VERSION "DNNBNNNYNNNNNNNNNNNNNNNNNNNNNNNNNNNNNNNNNN/4/%%%/4/'%**4NNN///"

NS_ :

BS_:

BU_: Vector__XXX xSolarWave xSolarSurveyor xSolarStorm xNova xMiata_SCP xMiata_AGS UI INV_CHG INV GATEWAY EMS DIAG CHG BMS BATTMON AGS

BO_ 2147560448 ChgCfg: 10 BMS
 SG_ RsvBits : 56|2@1+ (1,0) [0|0] "" BMS,CHG,DIAG,INV_CHG,UI,xNova,xSolarSurveyor,xSolarWave
 SG_ OverChgEnDis : 60|2@1+ (1,0) [0|0] "" BMS,CHG,DIAG,INV_CHG,UI,xNova,xSolarSurveyor,xSolarWave
 SG_ MsgCount : 2|6@1+ (1,0) [0|0] "" BMS,CHG,DIAG,INV_CHG,UI,xNova,xSolarSurveyor,xSolarWave
 SG_ EqlzOneTimeEnDis : 58|2@1+ (1,0) [0|0] "" BMS,CHG,DIAG,INV_CHG,UI,xNova,xSolarSurveyor,xSolarWave
 SG_ DcSrcId : 16|8@1+ (1,0) [0|252] "" BMS,CHG,DIAG,INV_CHG,UI,xNova,xSolarSurveyor,xSolarWave
 SG_ ConcurAccCtr : 8|8@1+ (1,0) [0|252] "" BMS,CHG,DIAG,INV_CHG,UI,xNova,xSolarSurveyor,xSolarWave
 SG_ ChgOverrideEnDis : 62|2@1+ (1,0) [0|0] "" BMS,CHG,DIAG,INV_CHG,UI,xNova,xSolarSurveyor,xSolarWave
 SG_ ChgMode : 64|8@1+ (1,0) [0|252] "" BMS,CHG,DIAG,INV_CHG,UI,xNova,xSolarSurveyor,xSolarWave
 SG_ ChgILimitMin : 40|8@1+ (1,0) [0|252] "%" BMS,CHG,DIAG,INV_CHG,UI,xNova,xSolarSurveyor,xSolarWave
 SG_ ChgILimitMax : 48|8@1+ (1,0) [0|252] "%" BMS,CHG,DIAG,INV_CHG,UI,xNova,xSolarSurveyor,xSolarWave
 SG_ ChgILimit : 32|8@1+ (1,0) [0|252] "%" BMS,CHG,DIAG,INV_CHG,UI,xNova,xSolarSurveyor,xSolarWave
 SG_ ChgAlgorithm : 24|8@1+ (1,0) [0|252] "" BMS,CHG,DIAG,INV_CHG,UI,xNova,xSolarSurveyor,xSolarWave
 SG_ CfgType : 0|2@1+ (1,0) [0|0] "" BMS,CHG,DIAG,INV_CHG,UI,xNova,xSolarSurveyor,xSolarWave
 SG_ BattTempNoSensor : 72|8@1+ (1,0) [0|252] "" BMS,CHG,DIAG,INV_CHG,UI,xNova,xSolarSurveyor,xSolarWave

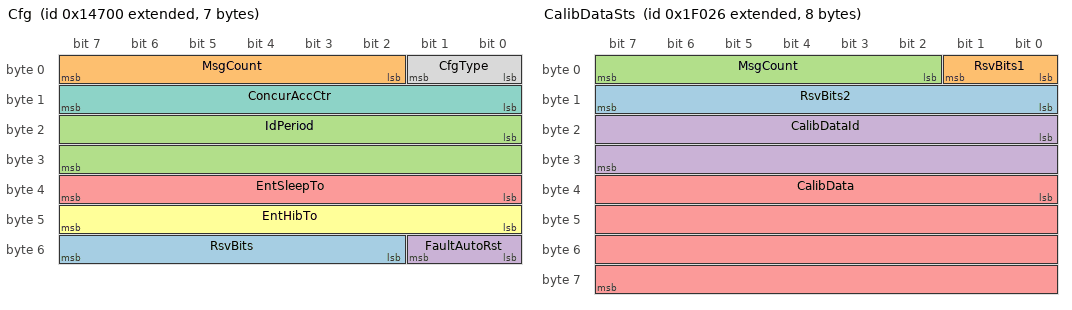
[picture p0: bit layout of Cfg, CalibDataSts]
BO_ 2147567360 Cfg: 7 AGS
 SG_ RsvBits : 50|6@1+ (1,0) [0|0] "" AGS,BATTMON,BMS,CHG,DIAG,EMS,GATEWAY,INV,INV_CHG,UI,xMiata_AGS,xNova,xSolarSurveyor,xSolarWave
 SG_ MsgCount : 2|6@1+ (1,0) [0|0] "" AGS,BATTMON,BMS,CHG,DIAG,EMS,GATEWAY,INV,INV_CHG,UI,xMiata_AGS,xNova,xSolarSurveyor,xSolarWave
 SG_ IdPeriod : 16|16@1+ (0.01,0) [0|655.32] "seconds" AGS,BATTMON,BMS,CHG,DIAG,EMS,GATEWAY,INV,INV_CHG,UI,xMiata_AGS,xNova,xSolarSurveyor,xSolarWave
 SG_ FaultAutoRst : 48|2@1+ (1,0) [0|0] "" AGS,BATTMON,BMS,CHG,DIAG,EMS,GATEWAY,INV,INV_CHG,UI,xMiata_AGS,xNova,xSolarSurveyor,xSolarWave
 SG_ EntSleepTo : 32|8@1+ (1,0) [0|252] "seconds" AGS,BATTMON,BMS,CHG,DIAG,EMS,GATEWAY,INV,INV_CHG,UI,xMiata_AGS,xNova,xSolarSurveyor,xSolarWave
 SG_ EntHibTo : 40|8@1+ (1,0) [0|252] "seconds" AGS,BATTMON,BMS,CHG,DIAG,EMS,GATEWAY,INV,INV_CHG,UI,xMiata_AGS,xNova,xSolarSurveyor,xSolarWave
 SG_ ConcurAccCtr : 8|8@1+ (1,0) [0|252] "" AGS,BATTMON,BMS,CHG,DIAG,EMS,GATEWAY,INV,INV_CHG,UI,xMiata_AGS,xNova,xSolarSurveyor,xSolarWave
 SG_ CfgType : 0|2@1+ (1,0) [0|0] "" AGS,BATTMON,BMS,CHG,DIAG,EMS,GATEWAY,INV,INV_CHG,UI,xMiata_AGS,xNova,xSolarSurveyor,xSolarWave

BO_ 2147610662 CalibDataSts: 8 BATTMON
 SG_ RsvBits2 : 8|8@1+ (1,0) [0|0] "" BATTMON,CHG,DIAG,INV,INV_CHG
 SG_ RsvBits1 : 0|2@1+ (1,0) [0|0] "" BATTMON,CHG,DIAG,INV,INV_CHG
 SG_ MsgCount : 2|6@1+ (1,0) [0|0] "" BATTMON,CHG,DIAG,INV,INV_CHG
 SG_ CalibDataId : 16|16@1+ (1,0) [0|65532] "" BATTMON,CHG,DIAG,INV,INV_CHG
 SG_ CalibData : 32|32@1+ (1,0) [0|4.29497E+09] "" BATTMON,CHG,DIAG,INV,INV_CHG

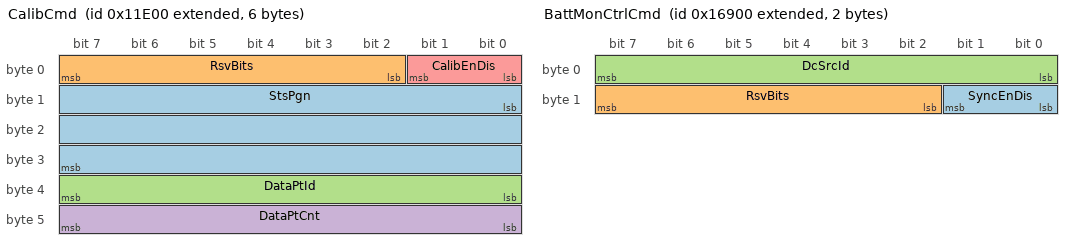
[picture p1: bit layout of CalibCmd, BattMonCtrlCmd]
BO_ 2147556864 CalibCmd: 6 DIAG
 SG_ StsPgn : 8|24@1+ (1,0) [0|0] "" BATTMON,CHG,INV,INV_CHG
 SG_ RsvBits : 2|6@1+ (1,0) [0|0] "" BATTMON,CHG,INV,INV_CHG
 SG_ DataPtId : 32|8@1+ (1,0) [0|252] "" BATTMON,CHG,INV,INV_CHG
 SG_ DataPtCnt : 40|8@1+ (1,0) [0|252] "" BATTMON,CHG,INV,INV_CHG
 SG_ CalibEnDis : 0|2@1+ (1,0) [0|0] "" BATTMON,CHG,INV,INV_CHG

BO_ 2147610665 BmsSts: 18 BATTMON
 SG_ RsvBits : 0|2@1+ (1,0) [0|0] "" CHG,DIAG,INV_CHG,UI,xSolarSurveyor,xSolarWave
 SG_ ReferenceV : 16|32@1- (0.001,0) [-2.14748E+06|2.14748E+06] "V" CHG,DIAG,INV_CHG,UI,xSolarSurveyor,xSolarWave
 SG_ ReferenceI : 48|32@1- (0.001,0) [-2.14748E+06|2.14748E+06] "Amps" CHG,DIAG,INV_CHG,UI,xSolarSurveyor,xSolarWave
 SG_ ReadbackV : 80|32@1- (0.001,0) [-2.14748E+06|2.14748E+06] "V" CHG,DIAG,INV_CHG,UI,xSolarSurveyor,xSolarWave
 SG_ ReadbackI : 112|32@1- (0.001,0) [-2.14748E+06|2.14748E+06] "Amps" CHG,DIAG,INV_CHG,UI,xSolarSurveyor,xSolarWave
 SG_ MsgCount : 2|6@1+ (1,0) [0|0] "" CHG,DIAG,INV_CHG,UI,xSolarSurveyor,xSolarWave
 SG_ DcSrcId : 8|8@1+ (1,0) [0|252] "" CHG,DIAG,INV_CHG,UI,xSolarSurveyor,xSolarWave

BO_ 2147574528 BmsCfg: 16 BATTMON
 SG_ MsgCount : 2|6@1+ (1,0) [0|0] "" BATTMON,BMS,DIAG,INV,INV_CHG,UI,xSolarWave
 SG_ MaxDischargeTimeIntMin : 96|16@1+ (0.01,0) [0|655.32] "seconds" BATTMON,BMS,DIAG,INV,INV_CHG,UI,xSolarWave
 SG_ MaxDischargeTimeIntMax : 112|16@1+ (0.01,0) [0|655.32] "seconds" BATTMON,BMS,DIAG,INV,INV_CHG,UI,xSolarWave
 SG_ MaxDischargeTimeInt : 80|16@1+ (0.01,0) [0|655.32] "seconds" BATTMON,BMS,DIAG,INV,INV_CHG,UI,xSolarWave
 SG_ MaxDischargeIMin : 48|16@1+ (1,0) [0|65532] "%" BATTMON,BMS,DIAG,INV,INV_CHG,UI,xSolarWave
 SG_ MaxDischargeIMax : 64|16@1+ (1,0) [0|65532] "%" BATTMON,BMS,DIAG,INV,INV_CHG,UI,xSolarWave
 SG_ MaxDischargeI : 32|16@1+ (1,0) [0|65532] "%" BATTMON,BMS,DIAG,INV,INV_CHG,UI,xSolarWave
 SG_ DcSrcId : 16|8@1+ (1,0) [0|252] "" BATTMON,BMS,DIAG,INV,INV_CHG,UI,xSolarWave
 SG_ ConcurAccCtr : 8|8@1+ (1,0) [0|252] "" BATTMON,BMS,DIAG,INV,INV_CHG,UI,xSolarWave
 SG_ CfgType : 0|2@1+ (1,0) [0|0] "" BATTMON,BMS,DIAG,INV,INV_CHG,UI,xSolarWave
 SG_ BattType : 24|8@1+ (1,0) [0|252] "" BATTMON,BMS,DIAG,INV,INV_CHG,UI,xSolarWave

BO_ 2147610820 BattSts2: 36 BATTMON
 SG_ Voltage : 16|32@1- (0.001,0) [-2.14748E+06|2.14748E+06] "V" AGS,BATTMON,CHG,DIAG,GATEWAY,INV,INV_CHG,UI,xSolarSurveyor,xSolarWave
 SG_ TimeToFull : 256|16@1+ (1,0) [0|65532] "minutes" AGS,BATTMON,CHG,DIAG,GATEWAY,INV,INV_CHG,UI,xSolarSurveyor,xSolarWave
 SG_ TimeRemain : 208|16@1+ (1,0) [0|65532] "minutes" AGS,BATTMON,CHG,DIAG,GATEWAY,INV,INV_CHG,UI,xSolarSurveyor,xSolarWave
 SG_ TempSensId : 144|8@1+ (1,0) [0|252] "" AGS,BATTMON,CHG,DIAG,GATEWAY,INV,INV_CHG,UI,xSolarSurveyor,xSolarWave
 SG_ Temp : 152|16@1+ (0.01,0) [0|655.32] "°K" AGS,BATTMON,CHG,DIAG,GATEWAY,INV,INV_CHG,UI,xSolarSurveyor,xSolarWave
 SG_ Soh : 176|8@1+ (1,0) [0|252] "%" AGS,BATTMON,CHG,DIAG,GATEWAY,INV,INV_CHG,UI,xSolarSurveyor,xSolarWave
 SG_ Soc : 168|8@1+ (1,0) [0|252] "%" AGS,BATTMON,CHG,DIAG,GATEWAY,INV,INV_CHG,UI,xSolarSurveyor,xSolarWave
 SG_ RsvBits : 0|2@1+ (1,0) [0|0] "" AGS,BATTMON,CHG,DIAG,GATEWAY,INV,INV_CHG,UI,xSolarSurveyor,xSolarWave
 SG_ RippleVoltage : 112|32@1+ (0.001,0) [0|4.29497E+06] "V" AGS,BATTMON,CHG,DIAG,GATEWAY,INV,INV_CHG,UI,xSolarSurveyor,xSolarWave
 SG_ Pwr : 80|32@1+ (1,0) [0|4.29497E+09] "W" AGS,BATTMON,CHG,DIAG,GATEWAY,INV,INV_CHG,UI,xSolarSurveyor,xSolarWave
 SG_ NomBattVoltage : 280|8@1+ (1,0) [0|252] "" AGS,BATTMON,CHG,DIAG,GATEWAY,INV,INV_CHG,UI,xSolarSurveyor,xSolarWave
 SG_ MsgCount : 2|6@1+ (1,0) [0|0] "" AGS,BATTMON,CHG,DIAG,GATEWAY,INV,INV_CHG,UI,xSolarSurveyor,xSolarWave
 SG_ EnergyRemain : 224|32@1+ (1,0) [0|4.29497E+09] "W h" AGS,BATTMON,CHG,DIAG,GATEWAY,INV,INV_CHG,UI,xSolarSurveyor,xSolarWave
 SG_ DcSrcId : 8|8@1+ (1,0) [0|252] "" AGS,BATTMON,CHG,DIAG,GATEWAY,INV,INV_CHG,UI,xSolarSurveyor,xSolarWave
 SG_ Current : 48|32@1- (0.001,0) [-2.14748E+06|2.14748E+06] "Amps" AGS,BATTMON,CHG,DIAG,GATEWAY,INV,INV_CHG,UI,xSolarSurveyor,xSolarWave
 SG_ BattType : 272|8@1+ (1,0) [0|252] "" AGS,BATTMON,CHG,DIAG,GATEWAY,INV,INV_CHG,UI,xSolarSurveyor,xSolarWave
 SG_ BattCapRemain : 184|16@1+ (1,0) [0|65532] "Ah" AGS,BATTMON,CHG,DIAG,GATEWAY,INV,INV_CHG,UI,xSolarSurveyor,xSolarWave
 SG_ BattCapPer : 200|8@1+ (1,0) [0|252] "%" AGS,BATTMON,CHG,DIAG,GATEWAY,INV,INV_CHG,UI,xSolarSurveyor,xSolarWave

BO_ 2147610651 BattMonSts: 39 BATTMON
 SG_ Voltage : 16|32@1- (0.001,0) [-2.14748E+06|2.14748E+06] "V" AGS,BATTMON,CHG,DIAG,INV,INV_CHG,UI,xSolarWave
 SG_ TimeToFull : 160|16@1+ (1,0) [0|65532] "minutes" AGS,BATTMON,CHG,DIAG,INV,INV_CHG,UI,xSolarWave
 SG_ TimeToDischarge : 144|16@1+ (1,0) [0|65532] "minutes" AGS,BATTMON,CHG,DIAG,INV,INV_CHG,UI,xSolarWave
 SG_ Temp : 80|16@1+ (0.01,0) [0|655.32] "°K" AGS,BATTMON,CHG,DIAG,INV,INV_CHG,UI,xSolarWave
 SG_ Soh : 136|8@1+ (1,0) [0|252] "%" AGS,BATTMON,CHG,DIAG,INV,INV_CHG,UI,xSolarWave
 SG_ Soc : 128|8@1+ (1,0) [0|252] "%" AGS,BATTMON,CHG,DIAG,INV,INV_CHG,UI,xSolarWave
 SG_ RsvBits : 202|6@1+ (1,0) [0|0] "" AGS,BATTMON,CHG,DIAG,INV,INV_CHG,UI,xSolarWave
 SG_ RsvBits : 0|2@1+ (1,0) [0|0] "" AGS,BATTMON,CHG,DIAG,INV,INV_CHG,UI,xSolarWave
 SG_ PerOvercharge : 192|8@1+ (1,0) [0|252] "%" AGS,BATTMON,CHG,DIAG,INV,INV_CHG,UI,xSolarWave
 SG_ MsgCount : 2|6@1+ (1,0) [0|0] "" AGS,BATTMON,CHG,DIAG,INV,INV_CHG,UI,xSolarWave
 SG_ Mid3Voltage : 280|32@1- (0.001,0) [-2.14748E+06|2.14748E+06] "V" AGS,BATTMON,CHG,DIAG,INV,INV_CHG,UI,xSolarWave
 SG_ Mid2Voltage : 248|32@1- (0.001,0) [-2.14748E+06|2.14748E+06] "V" AGS,BATTMON,CHG,DIAG,INV,INV_CHG,UI,xSolarWave
 SG_ Mid1Voltage : 216|32@1- (0.001,0) [-2.14748E+06|2.14748E+06] "V" AGS,BATTMON,CHG,DIAG,INV,INV_CHG,UI,xSolarWave
 SG_ LastEqualize : 208|8@1+ (1,0) [0|252] "days" AGS,BATTMON,CHG,DIAG,INV,INV_CHG,UI,xSolarWave
 SG_ HoursInFloat : 176|16@1+ (0.1,0) [0|6553.2] "hours" AGS,BATTMON,CHG,DIAG,INV,INV_CHG,UI,xSolarWave
 SG_ DcSrcId : 8|8@1+ (1,0) [0|252] "" AGS,BATTMON,CHG,DIAG,INV,INV_CHG,UI,xSolarWave
 SG_ Current : 48|32@1- (0.001,0) [-2.14748E+06|2.14748E+06] "Amps" AGS,BATTMON,CHG,DIAG,INV,INV_CHG,UI,xSolarWave
 SG_ BtsPresent : 200|2@1+ (1,0) [0|0] "" AGS,BATTMON,CHG,DIAG,INV,INV_CHG,UI,xSolarWave
 SG_ BattCapRemoved : 96|16@1+ (1,0) [0|65532] "Ah" AGS,BATTMON,CHG,DIAG,INV,INV_CHG,UI,xSolarWave
 SG_ BattCapRemain : 112|16@1+ (1,0) [0|65532] "Ah" AGS,BATTMON,CHG,DIAG,INV,INV_CHG,UI,xSolarWave

BO_ 2147610645 BattMonStatsBatt: 1785 BATTMON
 SG_ VoltageMin : 88|32@1- (0.001,0) [-2.14748E+06|2.14748E+06] "V" DIAG,UI
 SG_ VoltageMax : 120|32@1- (0.001,0) [-2.14748E+06|2.14748E+06] "V" DIAG,UI
 SG_ TimeSinceSync : 392|32@1+ (1,0) [0|4.29497E+09] "seconds" DIAG,UI
 SG_ TempMin : 248|16@1+ (0.01,0) [0|655.32] "°K" DIAG,UI
 SG_ TempMax : 264|16@1+ (0.01,0) [0|655.32] "°K" DIAG,UI
 SG_ RsvBits : 0|2@1+ (1,0) [0|0] "" DIAG,UI
 SG_ PreviousPeriodCount : 19|5@1+ (1,0) [0|0] "" DIAG,UI
 SG_ PreviousPeriod : 16|3@1+ (1,0) [0|0] "" DIAG,UI
 SG_ NumSync : 440|16@1+ (1,0) [0|65532] "" DIAG,UI
 SG_ NumSoc90 : 520|16@1+ (1,0) [0|65532] "" DIAG,UI
 SG_ NumSoc75 : 504|16@1+ (1,0) [0|65532] "" DIAG,UI
 SG_ NumSoc50 : 488|16@1+ (1,0) [0|65532] "" DIAG,UI
 SG_ NumSoc25 : 472|16@1+ (1,0) [0|65532] "" DIAG,UI
 SG_ NumDischg : 456|16@1+ (1,0) [0|65532] "" DIAG,UI
 SG_ NumChg : 424|16@1+ (1,0) [0|65532] "" DIAG,UI
 SG_ MsgCount : 2|6@1+ (1,0) [0|0] "" DIAG,UI
 SG_ EnergyOut : 360|32@1+ (1,0) [0|4.29497E+09] "W h" DIAG,UI
 SG_ EnergyIn : 328|32@1+ (1,0) [0|4.29497E+09] "W h" DIAG,UI
 SG_ DeepestSoc : 536|8@1+ (1,0) [0|252] "%" DIAG,UI
 SG_ DeepestDischgPer : 320|8@1+ (1,0) [0|252] "%" DIAG,UI
 SG_ DeepestDischg : 304|16@1+ (1,0) [0|65532] "Ah" DIAG,UI
 SG_ DcSrcId : 8|8@1+ (1,0) [0|252] "" DIAG,UI
 SG_ CurrentMaxDischg : 56|32@1- (0.001,0) [-2.14748E+06|2.14748E+06] "Amps" DIAG,UI
 SG_ CurrentMaxChg : 24|32@1- (0.001,0) [-2.14748E+06|2.14748E+06] "Amps" DIAG,UI
 SG_ CapacityReturned : 184|32@1- (1,0) [-2.14748E+09|2.14748E+09] "Ah" DIAG,UI
 SG_ CapacityRemoved : 216|32@1- (1,0) [-2.14748E+09|2.14748E+09] "Ah" DIAG,UI
 SG_ CapacityMin : 152|16@1+ (1,0) [0|65532] "Ah" DIAG,UI
 SG_ CapacityMax : 168|16@1+ (1,0) [0|65532] "Ah" DIAG,UI
 SG_ AvgDischgPer : 296|8@1+ (1,0) [0|252] "%" DIAG,UI
 SG_ AvgDischg : 280|16@1+ (1,0) [0|65532] "Ah" DIAG,UI

BO_ 2147610829 BattMonHist: 24 BATTMON
 SG_ RsvBits : 0|2@1+ (1,0) [0|0] "" DIAG,UI
 SG_ NumSync : 160|16@1+ (1,0) [0|65532] "" DIAG,UI
 SG_ NumDischg : 176|16@1+ (1,0) [0|65532] "" DIAG,UI
 SG_ NumChg : 144|16@1+ (1,0) [0|65532] "" DIAG,UI
 SG_ MsgCount : 2|6@1+ (1,0) [0|0] "" DIAG,UI
 SG_ DeepestDischgPer : 64|16@1+ (0.01,0) [0|655.32] "%" DIAG,UI
 SG_ DeepestDischg : 48|16@1+ (1,0) [0|65532] "Ah" DIAG,UI
 SG_ DcSrcId : 8|8@1+ (1,0) [0|252] "" DIAG,UI
 SG_ CapacityReturned : 112|32@1+ (1,0) [0|4.29497E+09] "Ah" DIAG,UI
 SG_ CapacityRemoved : 80|32@1+ (1,0) [0|4.29497E+09] "Ah" DIAG,UI
 SG_ AvgDischgPer : 32|16@1+ (0.01,0) [0|655.32] "%" DIAG,UI
 SG_ AvgDischg : 16|16@1+ (1,0) [0|65532] "Ah" DIAG,UI

BO_ 2147576064 BattMonCtrlCmd: 2 DIAG
 SG_ SyncEnDis : 8|2@1+ (1,0) [0|0] "" BATTMON
 SG_ RsvBits : 10|6@1+ (1,0) [0|0] "" BATTMON
 SG_ DcSrcId : 0|8@1+ (1,0) [0|252] "" BATTMON

BO_ 2147574784 BattMonCfgSync: 19 BATTMON
 SG_ RsvBits : 124|4@1+ (1,0) [0|0] "" BATTMON,DIAG,UI
 SG_ MsgCount : 2|6@1+ (1,0) [0|0] "" BATTMON,DIAG,UI
 SG_ DischgFloorMin : 104|8@1+ (1,0) [0|252] "%" BATTMON,DIAG,UI
 SG_ DischgFloorMax : 112|8@1+ (1,0) [0|252] "%" BATTMON,DIAG,UI
 SG_ DischgFloor : 96|8@1+ (1,0) [0|252] "%" BATTMON,DIAG,UI
 SG_ DcSrcId : 16|8@1+ (1,0) [0|252] "" BATTMON,DIAG,UI
 SG_ ConcurAccCtr : 8|8@1+ (1,0) [0|252] "" BATTMON,DIAG,UI
 SG_ ChgFloatVMin : 40|16@1+ (0.001,0) [0|65.532] "V" BATTMON,DIAG,UI
 SG_ ChgFloatVMax : 56|16@1+ (0.001,0) [0|65.532] "V" BATTMON,DIAG,UI
 SG_ ChgFloatV : 24|16@1+ (0.001,0) [0|65.532] "V" BATTMON,DIAG,UI
 SG_ ChgFloatIMin : 80|8@1+ (0.1,0) [0|25.2] "%" BATTMON,DIAG,UI
 SG_ ChgFloatIMax : 88|8@1+ (0.1,0) [0|25.2] "%" BATTMON,DIAG,UI
 SG_ ChgFloatI : 72|8@1+ (0.1,0) [0|25.2] "%" BATTMON,DIAG,UI
 SG_ CfgType : 0|2@1+ (1,0) [0|0] "" BATTMON,DIAG,UI
 SG_ AutoSyncTime : 120|4@1+ (1,0) [0|0] "seconds" BATTMON,DIAG,UI
 SG_ AutoSyncSensMin : 136|8@1+ (1,0) [0|252] "" BATTMON,DIAG,UI
 SG_ AutoSyncSensMax : 144|8@1+ (1,0) [0|252] "" BATTMON,DIAG,UI
 SG_ AutoSyncSens : 128|8@1+ (1,0) [0|252] "" BATTMON,DIAG,UI

BO_ 2147559680 BattMonCfg: 28 BATTMON
 SG_ TimeRemAvgFilter : 172|2@1+ (1,0) [0|0] "" BATTMON,DIAG,UI
 SG_ TempUnit : 72|8@1+ (1,0) [0|252] "" BATTMON,DIAG,UI
 SG_ ShuntVoltRating : 160|2@1+ (1,0) [0|0] "mV" BATTMON,DIAG,UI
 SG_ ShuntAmpRating : 152|8@1+ (1,0) [0|0] "A" BATTMON,DIAG,UI
 SG_ SetupLock : 170|2@1+ (1,0) [0|0] "" BATTMON,DIAG,UI
 SG_ SelfDischargeRateMin : 136|8@1+ (0.1,0) [0|25.2] "%/month" BATTMON,DIAG,UI
 SG_ SelfDischargeRateMax : 144|8@1+ (0.1,0) [0|25.2] "%/month" BATTMON,DIAG,UI
 SG_ SelfDischargeRate : 128|8@1+ (0.1,0) [0|25.2] "%/month" BATTMON,DIAG,UI
 SG_ RsvBits : 174|2@1+ (1,0) [0|0] "" BATTMON,DIAG,UI
 SG_ NomV : 168|2@1+ (1,0) [0|0] "" BATTMON,DIAG,UI
 SG_ NomTempMin : 40|16@1+ (0.01,0) [0|655.32] "°K" BATTMON,DIAG,UI
 SG_ NomTempMax : 56|16@1+ (0.01,0) [0|655.32] "°K" BATTMON,DIAG,UI
 SG_ NomTemp : 24|16@1+ (0.01,0) [0|655.32] "°K" BATTMON,DIAG,UI
 SG_ NomDisRateMin : 112|8@1+ (1,0) [0|252] "hours" BATTMON,DIAG,UI
 SG_ NomDisRateMax : 120|8@1+ (1,0) [0|252] "hours" BATTMON,DIAG,UI
 SG_ NomDisRate : 104|8@1+ (1,0) [0|252] "hours" BATTMON,DIAG,UI
 SG_ MsgCount : 2|6@1+ (1,0) [0|0] "" BATTMON,DIAG,UI
 SG_ DefaultTempMin : 192|16@1+ (0.01,0) [0|655.32] "°K" BATTMON,DIAG,UI
 SG_ DefaultTempMax : 208|16@1+ (0.01,0) [0|655.32] "°K" BATTMON,DIAG,UI
 SG_ DefaultTemp : 176|16@1+ (0.01,0) [0|655.32] "°K" BATTMON,DIAG,UI
 SG_ DcSrcId : 16|8@1+ (1,0) [0|252] "" BATTMON,DIAG,UI
 SG_ ConcurAccCtr : 8|8@1+ (1,0) [0|252] "" BATTMON,DIAG,UI
 SG_ ChgEfficFactorMode : 162|2@1+ (1,0) [0|0] "" BATTMON,DIAG,UI
 SG_ CfgType : 0|2@1+ (1,0) [0|0] "" BATTMON,DIAG,UI
 SG_ BattCapTempCoeffMin : 88|8@1+ (0.01,0) [0|2.52] "%Ah/°C" BATTMON,DIAG,UI
 SG_ BattCapTempCoeffMax : 96|8@1+ (0.01,0) [0|2.52] "%Ah/°C" BATTMON,DIAG,UI
 SG_ BattCapTempCoeff : 80|8@1+ (0.01,0) [0|2.52] "%Ah/°C" BATTMON,DIAG,UI
 SG_ BacklightDuration : 164|4@1+ (1,0) [0|0] "seconds" BATTMON,DIAG,UI

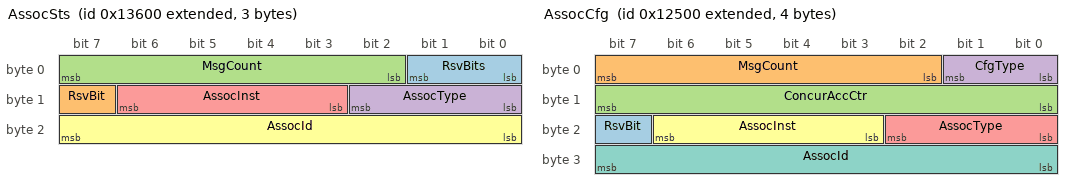
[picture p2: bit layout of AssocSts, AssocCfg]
BO_ 2147563008 AssocSts: 3 AGS
 SG_ RsvBits : 0|2@1+ (1,0) [0|0] "" AGS,BATTMON,BMS,CHG,EMS,GATEWAY,INV,INV_CHG,UI,xMiata_AGS,xNova,xSolarSurveyor,xSolarWave
 SG_ RsvBit : 15|1@1+ (1,0) [0|0] "" AGS,BATTMON,BMS,CHG,EMS,GATEWAY,INV,INV_CHG,UI,xMiata_AGS,xNova,xSolarSurveyor,xSolarWave
 SG_ MsgCount : 2|6@1+ (1,0) [0|0] "" AGS,BATTMON,BMS,CHG,EMS,GATEWAY,INV,INV_CHG,UI,xMiata_AGS,xNova,xSolarSurveyor,xSolarWave
 SG_ AssocType : 8|3@1+ (1,0) [0|0] "" AGS,BATTMON,BMS,CHG,EMS,GATEWAY,INV,INV_CHG,UI,xMiata_AGS,xNova,xSolarSurveyor,xSolarWave
 SG_ AssocInst : 11|4@1+ (1,0) [0|0] "" AGS,BATTMON,BMS,CHG,EMS,GATEWAY,INV,INV_CHG,UI,xMiata_AGS,xNova,xSolarSurveyor,xSolarWave
 SG_ AssocId : 16|8@1+ (1,0) [0|252] "" AGS,BATTMON,BMS,CHG,EMS,GATEWAY,INV,INV_CHG,UI,xMiata_AGS,xNova,xSolarSurveyor,xSolarWave

BO_ 2147558656 AssocCfg: 4 AGS
 SG_ RsvBit : 23|1@1+ (1,0) [0|0] "" AGS,BATTMON,BMS,CHG,DIAG,EMS,INV,INV_CHG,UI,xMiata_AGS,xNova,xSolarSurveyor,xSolarWave
 SG_ MsgCount : 2|6@1+ (1,0) [0|0] "" AGS,BATTMON,BMS,CHG,DIAG,EMS,INV,INV_CHG,UI,xMiata_AGS,xNova,xSolarSurveyor,xSolarWave
 SG_ ConcurAccCtr : 8|8@1+ (1,0) [0|252] "" AGS,BATTMON,BMS,CHG,DIAG,EMS,INV,INV_CHG,UI,xMiata_AGS,xNova,xSolarSurveyor,xSolarWave
 SG_ CfgType : 0|2@1+ (1,0) [0|0] "" AGS,BATTMON,BMS,CHG,DIAG,EMS,INV,INV_CHG,UI,xMiata_AGS,xNova,xSolarSurveyor,xSolarWave
 SG_ AssocType : 16|3@1+ (1,0) [0|0] "" AGS,BATTMON,BMS,CHG,DIAG,EMS,INV,INV_CHG,UI,xMiata_AGS,xNova,xSolarSurveyor,xSolarWave
 SG_ AssocInst : 19|4@1+ (1,0) [0|0] "" AGS,BATTMON,BMS,CHG,DIAG,EMS,INV,INV_CHG,UI,xMiata_AGS,xNova,xSolarSurveyor,xSolarWave
 SG_ AssocId : 24|8@1+ (1,0) [0|252] "" AGS,BATTMON,BMS,CHG,DIAG,EMS,INV,INV_CHG,UI,xMiata_AGS,xNova,xSolarSurveyor,xSolarWave

BO_ 2147610633 ApsSts: 10 CHG
 SG_ Voltage : 16|32@1- (0.001,0) [-2.14748E+06|2.14748E+06] "V" CHG,DIAG,INV,INV_CHG
 SG_ RsvBits : 0|2@1+ (1,0) [0|0] "" CHG,DIAG,INV,INV_CHG
 SG_ OutputId : 8|8@1+ (1,0) [0|252] "" CHG,DIAG,INV,INV_CHG
 SG_ MsgCount : 2|6@1+ (1,0) [0|0] "" CHG,DIAG,INV,INV_CHG
 SG_ Current : 48|32@1- (0.001,0) [-2.14748E+06|2.14748E+06] "Amps" CHG,DIAG,INV,INV_CHG

BO_ 2147552512 ApsCfgUv: 223 CHG
 SG_ UvLvlMin : 88|32@1- (0.001,0) [-2.14748E+06|2.14748E+06] "V" CHG,DIAG,INV,INV_CHG,xNova,xSolarWave
 SG_ UvLvlMax : 120|32@1- (0.001,0) [-2.14748E+06|2.14748E+06] "V" CHG,DIAG,INV,INV_CHG,xNova,xSolarWave
 SG_ UvLvl : 56|32@1- (0.001,0) [-2.14748E+06|2.14748E+06] "V" CHG,DIAG,INV,INV_CHG,xNova,xSolarWave
 SG_ UvIntvlMin : 168|16@1+ (0.01,0) [0|655.32] "seconds" CHG,DIAG,INV,INV_CHG,xNova,xSolarWave
 SG_ UvIntvlMax : 184|16@1+ (0.01,0) [0|655.32] "seconds" CHG,DIAG,INV,INV_CHG,xNova,xSolarWave
 SG_ UvIntvl : 152|16@1+ (0.01,0) [0|655.32] "seconds" CHG,DIAG,INV,INV_CHG,xNova,xSolarWave
 SG_ RefEvtId : 40|16@1+ (1,0) [0|65532] "" CHG,DIAG,INV,INV_CHG,xNova,xSolarWave
 SG_ OutputId : 16|8@1+ (1,0) [0|252] "" CHG,DIAG,INV,INV_CHG,xNova,xSolarWave
 SG_ MsgCount : 2|6@1+ (1,0) [0|0] "" CHG,DIAG,INV,INV_CHG,xNova,xSolarWave
 SG_ EvtId : 24|16@1+ (1,0) [0|65532] "" CHG,DIAG,INV,INV_CHG,xNova,xSolarWave
 SG_ ConcurAccCtr : 8|8@1+ (1,0) [0|252] "" CHG,DIAG,INV,INV_CHG,xNova,xSolarWave
 SG_ CfgType : 0|2@1+ (1,0) [0|0] "" CHG,DIAG,INV,INV_CHG,xNova,xSolarWave

BO_ 2147552768 ApsCfgOv: 223 CHG
 SG_ RefEvtId : 40|16@1+ (1,0) [0|65532] "" CHG,DIAG,INV,INV_CHG,xNova,xSolarWave
 SG_ OvLvlMin : 88|32@1- (0.001,0) [-2.14748E+06|2.14748E+06] "V" CHG,DIAG,INV,INV_CHG,xNova,xSolarWave
 SG_ OvLvlMax : 120|32@1- (0.001,0) [-2.14748E+06|2.14748E+06] "V" CHG,DIAG,INV,INV_CHG,xNova,xSolarWave
 SG_ OvLvl : 56|32@1- (0.001,0) [-2.14748E+06|2.14748E+06] "V" CHG,DIAG,INV,INV_CHG,xNova,xSolarWave
 SG_ OvIntvlMin : 168|16@1+ (0.01,0) [0|655.32] "seconds" CHG,DIAG,INV,INV_CHG,xNova,xSolarWave
 SG_ OvIntvlMax : 184|16@1+ (0.01,0) [0|655.32] "seconds" CHG,DIAG,INV,INV_CHG,xNova,xSolarWave
 SG_ OvIntvl : 152|16@1+ (0.01,0) [0|655.32] "seconds" CHG,DIAG,INV,INV_CHG,xNova,xSolarWave
 SG_ OutputId : 16|8@1+ (1,0) [0|252] "" CHG,DIAG,INV,INV_CHG,xNova,xSolarWave
 SG_ MsgCount : 2|6@1+ (1,0) [0|0] "" CHG,DIAG,INV,INV_CHG,xNova,xSolarWave
 SG_ EvtId : 24|16@1+ (1,0) [0|65532] "" CHG,DIAG,INV,INV_CHG,xNova,xSolarWave
 SG_ ConcurAccCtr : 8|8@1+ (1,0) [0|252] "" CHG,DIAG,INV,INV_CHG,xNova,xSolarWave
 SG_ CfgType : 0|2@1+ (1,0) [0|0] "" CHG,DIAG,INV,INV_CHG,xNova,xSolarWave

BO_ 2147610647 AgsStsGen: 15 AGS
 SG_ Temp : 32|16@1+ (0.01,0) [0|655.32] "°K" DIAG,UI
 SG_ RsvBits : 0|2@1+ (1,0) [0|0] "" DIAG,UI
 SG_ OilPress : 16|16@1+ (100,0) [0|6.5532E+06] "Pa" DIAG,UI
 SG_ MsgCount : 2|6@1+ (1,0) [0|0] "" DIAG,UI
 SG_ FuelPress : 88|16@1+ (100,0) [0|6.5532E+06] "Pa" DIAG,UI
 SG_ FuelLvl : 80|8@1+ (1,0) [0|252] "%" DIAG,UI
 SG_ EngineDiscreteWarnSts : 104|16@1+ (1,0) [0|0] "" DIAG,UI
 SG_ BattV : 48|32@1- (0.001,0) [-2.14748E+06|2.14748E+06] "V" DIAG,UI
 SG_ AcSrcId : 8|8@1+ (1,0) [0|252] "" DIAG,UI

BO_ 2147610641 AgsSts: 10 AGS
 SG_ TimeInt : 56|16@1+ (0.1,0) [0|6553.2] "minutes" AGS,BATTMON,CHG,DIAG,EMS,GATEWAY,INV,INV_CHG,UI,xSolarWave
 SG_ RsvBits2 : 74|6@1+ (1,0) [0|0] "" AGS,BATTMON,CHG,DIAG,EMS,GATEWAY,INV,INV_CHG,UI,xSolarWave
 SG_ RsvBits1 : 0|2@1+ (1,0) [0|0] "" AGS,BATTMON,CHG,DIAG,EMS,GATEWAY,INV,INV_CHG,UI,xSolarWave
 SG_ OpState : 16|16@1+ (1,0) [0|65532] "" AGS,BATTMON,CHG,DIAG,EMS,GATEWAY,INV,INV_CHG,UI,xSolarWave
 SG_ MsgCount : 2|6@1+ (1,0) [0|0] "" AGS,BATTMON,CHG,DIAG,EMS,GATEWAY,INV,INV_CHG,UI,xSolarWave
 SG_ GenState : 32|8@1+ (1,0) [0|252] "" AGS,BATTMON,CHG,DIAG,EMS,GATEWAY,INV,INV_CHG,UI,xSolarWave
 SG_ GenOnReason : 40|8@1+ (1,0) [0|252] "" AGS,BATTMON,CHG,DIAG,EMS,GATEWAY,INV,INV_CHG,UI,xSolarWave
 SG_ GenOffReason : 48|8@1+ (1,0) [0|252] "" AGS,BATTMON,CHG,DIAG,EMS,GATEWAY,INV,INV_CHG,UI,xSolarWave
 SG_ AgsGenSig : 72|2@1+ (1,0) [0|0] "" AGS,BATTMON,CHG,DIAG,EMS,GATEWAY,INV,INV_CHG,UI,xSolarWave
 SG_ AcSrcId : 8|8@1+ (1,0) [0|252] "" AGS,BATTMON,CHG,DIAG,EMS,GATEWAY,INV,INV_CHG,UI,xSolarWave

BO_ 2147610648 AgsStatsGen: 12 AGS
 SG_ TotalRunTime : 48|16@1+ (0.1,0) [0|6553.2] "hours" DIAG,UI
 SG_ SuccStartCnt : 16|16@1+ (1,0) [0|65532] "" DIAG,UI
 SG_ RsvBits : 0|2@1+ (1,0) [0|0] "" DIAG,UI
 SG_ PrevRunTime : 64|16@1+ (1,0) [0|65532] "minutes" DIAG,UI
 SG_ MsgCount : 2|6@1+ (1,0) [0|0] "" DIAG,UI
 SG_ FailStartCnt : 32|16@1+ (1,0) [0|65532] "" DIAG,UI
 SG_ CurrRunTime : 80|16@1+ (1,0) [0|65532] "minutes" DIAG,UI
 SG_ AcSrcId : 8|8@1+ (1,0) [0|252] "" DIAG,UI

BO_ 2147557120 AgsCtrlCmd: 2 DIAG
 SG_ DesiredState : 8|8@1+ (1,0) [0|252] "" AGS,xMiata_AGS
 SG_ AcSrcId : 0|8@1+ (1,0) [0|252] "" AGS,xMiata_AGS

BO_ 2147560192 AgsCfgGen: 223 AGS
 SG_ StopTimeoutMin : 536|16@1+ (1,0) [0|65532] "seconds" AGS,DIAG,UI,xMiata_AGS
 SG_ StopTimeoutMax : 552|16@1+ (1,0) [0|65532] "seconds" AGS,DIAG,UI,xMiata_AGS
 SG_ StopTimeout : 520|16@1+ (1,0) [0|65532] "seconds" AGS,DIAG,UI,xMiata_AGS
 SG_ StarterCooldownTimeMin : 248|16@1+ (1,0) [0|65532] "seconds" AGS,DIAG,UI,xMiata_AGS
 SG_ StarterCooldownTimeMax : 264|16@1+ (1,0) [0|65532] "seconds" AGS,DIAG,UI,xMiata_AGS
 SG_ StarterCooldownTime : 232|16@1+ (1,0) [0|65532] "seconds" AGS,DIAG,UI,xMiata_AGS
 SG_ StartDlyMin : 104|16@1+ (1,0) [0|65532] "seconds" AGS,DIAG,UI,xMiata_AGS
 SG_ StartDlyMax : 120|16@1+ (1,0) [0|65532] "seconds" AGS,DIAG,UI,xMiata_AGS
 SG_ StartDly : 88|16@1+ (1,0) [0|65532] "seconds" AGS,DIAG,UI,xMiata_AGS
 SG_ SpindownTimeMin : 488|16@1+ (1,0) [0|65532] "seconds" AGS,DIAG,UI,xMiata_AGS
 SG_ SpindownTimeMax : 504|16@1+ (1,0) [0|65532] "seconds" AGS,DIAG,UI,xMiata_AGS
 SG_ SpindownTime : 472|16@1+ (1,0) [0|65532] "seconds" AGS,DIAG,UI,xMiata_AGS
 SG_ ShutdownBypassTimeMin : 200|16@1+ (1,0) [0|65532] "seconds" AGS,DIAG,UI,xMiata_AGS
 SG_ ShutdownBypassTimeMax : 216|16@1+ (1,0) [0|65532] "seconds" AGS,DIAG,UI,xMiata_AGS
 SG_ ShutdownBypassTime : 184|16@1+ (1,0) [0|65532] "seconds" AGS,DIAG,UI,xMiata_AGS
 SG_ RelayId : 736|8@1+ (1,0) [0|252] "" AGS,DIAG,UI,xMiata_AGS
 SG_ RelayFunc : 744|8@1+ (1,0) [0|252] "" AGS,DIAG,UI,xMiata_AGS
 SG_ PreheatTimeMin : 56|16@1+ (1,0) [0|65532] "seconds" AGS,DIAG,UI,xMiata_AGS
 SG_ PreheatTimeMax : 72|16@1+ (1,0) [0|65532] "seconds" AGS,DIAG,UI,xMiata_AGS
 SG_ PreheatTime : 40|16@1+ (1,0) [0|65532] "seconds" AGS,DIAG,UI,xMiata_AGS
 SG_ MsgCount : 2|6@1+ (1,0) [0|0] "" AGS,DIAG,UI,xMiata_AGS
 SG_ MaxRunTimeMin : 392|16@1+ (1,0) [0|65532] "minutes" AGS,DIAG,UI,xMiata_AGS
 SG_ MaxRunTimeMax : 408|16@1+ (1,0) [0|65532] "minutes" AGS,DIAG,UI,xMiata_AGS
 SG_ MaxRunTime : 376|16@1+ (1,0) [0|65532] "minutes" AGS,DIAG,UI,xMiata_AGS
 SG_ MaxGenStartRetriesMin : 576|8@1+ (1,0) [0|252] "" AGS,DIAG,UI,xMiata_AGS
 SG_ MaxGenStartRetriesMax : 584|8@1+ (1,0) [0|252] "" AGS,DIAG,UI,xMiata_AGS
 SG_ MaxGenStartRetries : 568|8@1+ (1,0) [0|252] "" AGS,DIAG,UI,xMiata_AGS
 SG_ GenWarmupTimeMin : 344|16@1+ (1,0) [0|65532] "seconds" AGS,DIAG,UI,xMiata_AGS
 SG_ GenWarmupTimeMax : 360|16@1+ (1,0) [0|65532] "seconds" AGS,DIAG,UI,xMiata_AGS
 SG_ GenWarmupTime : 328|16@1+ (1,0) [0|65532] "seconds" AGS,DIAG,UI,xMiata_AGS
 SG_ GenRunHoldTimeMin : 704|16@1+ (0.01,0) [0|655.32] "seconds" AGS,DIAG,UI,xMiata_AGS
 SG_ GenRunHoldTimeMax : 720|16@1+ (0.01,0) [0|655.32] "seconds" AGS,DIAG,UI,xMiata_AGS
 SG_ GenRunHoldTime : 688|16@1+ (0.01,0) [0|655.32] "seconds" AGS,DIAG,UI,xMiata_AGS
 SG_ GenOutType : 32|8@1+ (1,0) [0|252] "" AGS,DIAG,UI,xMiata_AGS
 SG_ GenIntfType : 24|8@1+ (1,0) [0|252] "" AGS,DIAG,UI,xMiata_AGS
 SG_ GenCooldownTimeMin : 440|16@1+ (1,0) [0|65532] "seconds" AGS,DIAG,UI,xMiata_AGS
 SG_ GenCooldownTimeMax : 456|16@1+ (1,0) [0|65532] "seconds" AGS,DIAG,UI,xMiata_AGS
 SG_ GenCooldownTime : 424|16@1+ (1,0) [0|65532] "seconds" AGS,DIAG,UI,xMiata_AGS
 SG_ ExerciseTodMin : 656|16@1+ (1,0) [0|65532] "minutes" AGS,DIAG,UI,xMiata_AGS
 SG_ ExerciseTodMax : 672|16@1+ (1,0) [0|65532] "minutes" AGS,DIAG,UI,xMiata_AGS
 SG_ ExerciseTod : 640|16@1+ (1,0) [0|65532] "minutes" AGS,DIAG,UI,xMiata_AGS
 SG_ ExercisePerMin : 600|8@1+ (1,0) [0|252] "days" AGS,DIAG,UI,xMiata_AGS
 SG_ ExercisePerMax : 608|8@1+ (1,0) [0|252] "days" AGS,DIAG,UI,xMiata_AGS
 SG_ ExercisePer : 592|8@1+ (1,0) [0|252] "days" AGS,DIAG,UI,xMiata_AGS
 SG_ ExerciseDurMin : 624|8@1+ (1,0) [0|252] "minutes" AGS,DIAG,UI,xMiata_AGS
 SG_ ExerciseDurMax : 632|8@1+ (1,0) [0|252] "minutes" AGS,DIAG,UI,xMiata_AGS
 SG_ ExerciseDur : 616|8@1+ (1,0) [0|252] "minutes" AGS,DIAG,UI,xMiata_AGS
 SG_ CrankTimeMin : 152|16@1+ (1,0) [0|65532] "seconds" AGS,DIAG,UI,xMiata_AGS
 SG_ CrankTimeMax : 168|16@1+ (1,0) [0|65532] "seconds" AGS,DIAG,UI,xMiata_AGS
 SG_ CrankTime : 136|16@1+ (1,0) [0|65532] "seconds" AGS,DIAG,UI,xMiata_AGS
 SG_ CrankRetryTimeMin : 296|16@1+ (1,0) [0|65532] "seconds" AGS,DIAG,UI,xMiata_AGS
 SG_ CrankRetryTimeMax : 312|16@1+ (1,0) [0|65532] "seconds" AGS,DIAG,UI,xMiata_AGS
 SG_ CrankRetryTime : 280|16@1+ (1,0) [0|65532] "seconds" AGS,DIAG,UI,xMiata_AGS
 SG_ ConcurAccCtr : 8|8@1+ (1,0) [0|252] "" AGS,DIAG,UI,xMiata_AGS
 SG_ CfgType : 0|2@1+ (1,0) [0|0] "" AGS,DIAG,UI,xMiata_AGS
 SG_ AcSrcId : 16|8@1+ (1,0) [0|252] "" AGS,DIAG,UI,xMiata_AGS

BO_ 2147564544 AgsCfgDcV: 223 AGS
 SG_ VLvlStopMin : 32|32@1- (0.001,0) [-2.14748E+06|2.14748E+06] "V" AGS,DIAG,UI,xMiata_AGS
 SG_ VLvlStopMax : 64|32@1- (0.001,0) [-2.14748E+06|2.14748E+06] "V" AGS,DIAG,UI,xMiata_AGS
 SG_ VLvlStartMin : 128|32@1- (0.001,0) [-2.14748E+06|2.14748E+06] "V" AGS,DIAG,UI,xMiata_AGS
 SG_ VLvlStartMax : 160|32@1- (0.001,0) [-2.14748E+06|2.14748E+06] "V" AGS,DIAG,UI,xMiata_AGS
 SG_ VLvl : 264|32@1- (0.001,0) [-2.14748E+06|2.14748E+06] "V" AGS,DIAG,UI,xMiata_AGS
 SG_ TimeIntStopMin : 96|16@1+ (0.1,0) [0|6553.2] "minutes" AGS,DIAG,UI,xMiata_AGS
 SG_ TimeIntStopMax : 112|16@1+ (0.1,0) [0|6553.2] "minutes" AGS,DIAG,UI,xMiata_AGS
 SG_ TimeIntStartMin : 192|16@1+ (0.1,0) [0|6553.2] "minutes" AGS,DIAG,UI,xMiata_AGS
 SG_ TimeIntStartMax : 208|16@1+ (0.1,0) [0|6553.2] "minutes" AGS,DIAG,UI,xMiata_AGS
 SG_ TimeInt : 296|16@1+ (0.1,0) [0|6553.2] "minutes" AGS,DIAG,UI,xMiata_AGS
 SG_ StartStop : 224|2@1+ (1,0) [0|0] "" AGS,DIAG,UI,xMiata_AGS
 SG_ RsvByte : 16|8@1+ (1,0) [0|0] "" AGS,DIAG,UI,xMiata_AGS
 SG_ RsvBits : 226|6@1+ (1,0) [0|0] "" AGS,DIAG,UI,xMiata_AGS
 SG_ PerEnd : 248|16@1+ (1,0) [0|65532] "minutes" AGS,DIAG,UI,xMiata_AGS
 SG_ PerBeg : 232|16@1+ (1,0) [0|65532] "minutes" AGS,DIAG,UI,xMiata_AGS
 SG_ MsgCount : 2|6@1+ (1,0) [0|0] "" AGS,DIAG,UI,xMiata_AGS
 SG_ DcSrcId : 24|8@1+ (1,0) [0|252] "" AGS,DIAG,UI,xMiata_AGS
 SG_ ConcurAccCtr : 8|8@1+ (1,0) [0|252] "" AGS,DIAG,UI,xMiata_AGS
 SG_ CfgType : 0|2@1+ (1,0) [0|0] "" AGS,DIAG,UI,xMiata_AGS

BO_ 2147571200 AgsCfgDcI: 223 AGS
 SG_ TimeIntStopMin : 96|16@1+ (0.1,0) [0|6553.2] "minutes" AGS,DIAG,UI
 SG_ TimeIntStopMax : 112|16@1+ (0.1,0) [0|6553.2] "minutes" AGS,DIAG,UI
 SG_ TimeIntStartMin : 192|16@1+ (0.1,0) [0|6553.2] "minutes" AGS,DIAG,UI
 SG_ TimeIntStartMax : 208|16@1+ (0.1,0) [0|6553.2] "minutes" AGS,DIAG,UI
 SG_ TimeInt : 296|16@1+ (0.1,0) [0|6553.2] "minutes" AGS,DIAG,UI
 SG_ StartStop : 224|2@1+ (1,0) [0|0] "" AGS,DIAG,UI
 SG_ RsvByte : 16|8@1+ (1,0) [0|0] "" AGS,DIAG,UI
 SG_ RsvBits : 226|6@1+ (1,0) [0|0] "" AGS,DIAG,UI
 SG_ PerEnd : 248|16@1+ (1,0) [0|65532] "minutes" AGS,DIAG,UI
 SG_ PerBeg : 232|16@1+ (1,0) [0|65532] "minutes" AGS,DIAG,UI
 SG_ MsgCount : 2|6@1+ (1,0) [0|0] "" AGS,DIAG,UI
 SG_ ILvlStopMin : 32|32@1- (0.001,0) [-2.14748E+06|2.14748E+06] "Amps" AGS,DIAG,UI
 SG_ ILvlStopMax : 64|32@1- (0.001,0) [-2.14748E+06|2.14748E+06] "Amps" AGS,DIAG,UI
 SG_ ILvlStartMin : 128|32@1- (0.001,0) [-2.14748E+06|2.14748E+06] "Amps" AGS,DIAG,UI
 SG_ ILvlStartMax : 160|32@1- (0.001,0) [-2.14748E+06|2.14748E+06] "Amps" AGS,DIAG,UI
 SG_ ILvl : 264|32@1- (0.001,0) [-2.14748E+06|2.14748E+06] "Amps" AGS,DIAG,UI
 SG_ DcSrcId : 24|8@1+ (1,0) [0|252] "" AGS,DIAG,UI
 SG_ ConcurAccCtr : 8|8@1+ (1,0) [0|252] "" AGS,DIAG,UI
 SG_ CfgType : 0|2@1+ (1,0) [0|0] "" AGS,DIAG,UI

BO_ 2147565312 AgsCfgCntctCls: 223 AGS
 SG_ RsvBits : 91|5@1+ (1,0) [0|0] "" AGS,DIAG,UI,xMiata_AGS
 SG_ PerEnd : 112|16@1+ (1,0) [0|65532] "minutes" AGS,DIAG,UI,xMiata_AGS
 SG_ PerBeg : 96|16@1+ (1,0) [0|65532] "minutes" AGS,DIAG,UI,xMiata_AGS
 SG_ OpnDlyMin : 56|16@1+ (0.1,0) [0|6553.2] "minutes" AGS,DIAG,UI,xMiata_AGS
 SG_ OpnDlyMax : 72|16@1+ (0.1,0) [0|6553.2] "minutes" AGS,DIAG,UI,xMiata_AGS
 SG_ OpnDly : 144|16@1+ (0.1,0) [0|6553.2] "minutes" AGS,DIAG,UI,xMiata_AGS
 SG_ MsgCount : 2|6@1+ (1,0) [0|0] "" AGS,DIAG,UI,xMiata_AGS
 SG_ ConcurAccCtr : 8|8@1+ (1,0) [0|252] "" AGS,DIAG,UI,xMiata_AGS
 SG_ CntctInst : 88|3@1+ (1,0) [0|0] "" AGS,DIAG,UI,xMiata_AGS
 SG_ ClsDlyMin : 24|16@1+ (0.1,0) [0|6553.2] "minutes" AGS,DIAG,UI,xMiata_AGS
 SG_ ClsDlyMax : 40|16@1+ (0.1,0) [0|6553.2] "minutes" AGS,DIAG,UI,xMiata_AGS
 SG_ ClsDly : 128|16@1+ (0.1,0) [0|6553.2] "minutes" AGS,DIAG,UI,xMiata_AGS
 SG_ CfgType : 0|2@1+ (1,0) [0|0] "" AGS,DIAG,UI,xMiata_AGS
 SG_ AcSrcId : 16|8@1+ (1,0) [0|252] "" AGS,DIAG,UI,xMiata_AGS

BO_ 2147564800 AgsCfgBattSoc: 223 AGS
 SG_ TimeIntStopMin : 48|16@1+ (0.1,0) [0|6553.2] "minutes" AGS,DIAG,UI,xMiata_AGS
 SG_ TimeIntStopMax : 64|16@1+ (0.1,0) [0|6553.2] "minutes" AGS,DIAG,UI,xMiata_AGS
 SG_ TimeIntStartMin : 96|16@1+ (0.1,0) [0|6553.2] "minutes" AGS,DIAG,UI,xMiata_AGS
 SG_ TimeIntStartMax : 112|16@1+ (0.1,0) [0|6553.2] "minutes" AGS,DIAG,UI,xMiata_AGS
 SG_ TimeInt : 176|16@1+ (0.1,0) [0|6553.2] "minutes" AGS,DIAG,UI,xMiata_AGS
 SG_ StartStop : 128|2@1+ (1,0) [0|0] "" AGS,DIAG,UI,xMiata_AGS
 SG_ SocLvlStopMin : 32|8@1+ (1,0) [0|252] "%" AGS,DIAG,UI,xMiata_AGS
 SG_ SocLvlStopMax : 40|8@1+ (1,0) [0|252] "%" AGS,DIAG,UI,xMiata_AGS
 SG_ SocLvlStartMin : 80|8@1+ (1,0) [0|252] "%" AGS,DIAG,UI,xMiata_AGS
 SG_ SocLvlStartMax : 88|8@1+ (1,0) [0|252] "%" AGS,DIAG,UI,xMiata_AGS
 SG_ SocLvl : 168|8@1+ (1,0) [0|252] "%" AGS,DIAG,UI,xMiata_AGS
 SG_ RsvByte : 16|8@1+ (1,0) [0|0] "" AGS,DIAG,UI,xMiata_AGS
 SG_ RsvBits : 130|6@1+ (1,0) [0|0] "" AGS,DIAG,UI,xMiata_AGS
 SG_ PerEnd : 152|16@1+ (1,0) [0|65532] "minutes" AGS,DIAG,UI,xMiata_AGS
 SG_ PerBeg : 136|16@1+ (1,0) [0|65532] "minutes" AGS,DIAG,UI,xMiata_AGS
 SG_ MsgCount : 2|6@1+ (1,0) [0|0] "" AGS,DIAG,UI,xMiata_AGS
 SG_ DcSrcId : 24|8@1+ (1,0) [0|252] "" AGS,DIAG,UI,xMiata_AGS
 SG_ ConcurAccCtr : 8|8@1+ (1,0) [0|252] "" AGS,DIAG,UI,xMiata_AGS
 SG_ CfgType : 0|2@1+ (1,0) [0|0] "" AGS,DIAG,UI,xMiata_AGS

BO_ 2147571456 AgsCfgAcPwr: 223 AGS
 SG_ TimeIntStopMin : 96|16@1+ (0.1,0) [0|6553.2] "minutes" AGS,DIAG,UI
 SG_ TimeIntStopMax : 112|16@1+ (0.1,0) [0|6553.2] "minutes" AGS,DIAG,UI
 SG_ TimeIntStartMin : 192|16@1+ (0.1,0) [0|6553.2] "minutes" AGS,DIAG,UI
 SG_ TimeIntStartMax : 208|16@1+ (0.1,0) [0|6553.2] "minutes" AGS,DIAG,UI
 SG_ TimeInt : 296|16@1+ (0.1,0) [0|6553.2] "minutes" AGS,DIAG,UI
 SG_ StartStop : 224|2@1+ (1,0) [0|0] "" AGS,DIAG,UI
 SG_ RsvByte : 16|8@1+ (1,0) [0|0] "" AGS,DIAG,UI
 SG_ RsvBits : 226|6@1+ (1,0) [0|0] "" AGS,DIAG,UI
 SG_ PerEnd : 248|16@1+ (1,0) [0|65532] "minutes" AGS,DIAG,UI
 SG_ PerBeg : 232|16@1+ (1,0) [0|65532] "minutes" AGS,DIAG,UI
 SG_ MsgCount : 2|6@1+ (1,0) [0|0] "" AGS,DIAG,UI
 SG_ ConcurAccCtr : 8|8@1+ (1,0) [0|252] "" AGS,DIAG,UI
 SG_ CfgType : 0|2@1+ (1,0) [0|0] "" AGS,DIAG,UI
 SG_ AcSrcId : 24|8@1+ (1,0) [0|252] "" AGS,DIAG,UI
 SG_ AcPwrLvlStopMin : 32|32@1+ (1,0) [0|4.29497E+09] "W" AGS,DIAG,UI
 SG_ AcPwrLvlStopMax : 64|32@1+ (1,0) [0|4.29497E+09] "W" AGS,DIAG,UI
 SG_ AcPwrLvlStartMin : 128|32@1+ (1,0) [0|4.29497E+09] "W" AGS,DIAG,UI
 SG_ AcPwrLvlStartMax : 160|32@1+ (1,0) [0|4.29497E+09] "W" AGS,DIAG,UI
 SG_ AcPwrLvl : 264|32@1+ (1,0) [0|4.29497E+09] "W" AGS,DIAG,UI

BO_ 2147565056 AgsCfgAcI: 223 AGS
 SG_ TimeIntStopMin : 96|16@1+ (0.1,0) [0|6553.2] "minutes" AGS,DIAG,UI,xMiata_AGS
 SG_ TimeIntStopMax : 112|16@1+ (0.1,0) [0|6553.2] "minutes" AGS,DIAG,UI,xMiata_AGS
 SG_ TimeIntStartMin : 192|16@1+ (0.1,0) [0|6553.2] "minutes" AGS,DIAG,UI,xMiata_AGS
 SG_ TimeIntStartMax : 208|16@1+ (0.1,0) [0|6553.2] "minutes" AGS,DIAG,UI,xMiata_AGS
 SG_ TimeInt : 296|16@1+ (0.1,0) [0|6553.2] "minutes" AGS,DIAG,UI,xMiata_AGS
 SG_ StartStop : 224|2@1+ (1,0) [0|0] "" AGS,DIAG,UI,xMiata_AGS
 SG_ RsvByte : 16|8@1+ (1,0) [0|0] "" AGS,DIAG,UI,xMiata_AGS
 SG_ RsvBits : 226|6@1+ (1,0) [0|0] "" AGS,DIAG,UI,xMiata_AGS
 SG_ PerEnd : 248|16@1+ (1,0) [0|65532] "minutes" AGS,DIAG,UI,xMiata_AGS
 SG_ PerBeg : 232|16@1+ (1,0) [0|65532] "minutes" AGS,DIAG,UI,xMiata_AGS
 SG_ MsgCount : 2|6@1+ (1,0) [0|0] "" AGS,DIAG,UI,xMiata_AGS
 SG_ ConcurAccCtr : 8|8@1+ (1,0) [0|252] "" AGS,DIAG,UI,xMiata_AGS
 SG_ CfgType : 0|2@1+ (1,0) [0|0] "" AGS,DIAG,UI,xMiata_AGS
 SG_ AcSrcId : 24|8@1+ (1,0) [0|252] "" AGS,DIAG,UI,xMiata_AGS
 SG_ AcILvlStopMin : 32|32@1+ (0.001,0) [0|4.29497E+06] "Amps" AGS,DIAG,UI,xMiata_AGS
 SG_ AcILvlStopMax : 64|32@1+ (0.001,0) [0|4.29497E+06] "Amps" AGS,DIAG,UI,xMiata_AGS
 SG_ AcILvlStartMin : 128|32@1+ (0.001,0) [0|4.29497E+06] "Amps" AGS,DIAG,UI,xMiata_AGS
 SG_ AcILvlStartMax : 160|32@1+ (0.001,0) [0|4.29497E+06] "Amps" AGS,DIAG,UI,xMiata_AGS
 SG_ AcILvl : 264|32@1+ (0.001,0) [0|4.29497E+06] "Amps" AGS,DIAG,UI,xMiata_AGS

BO_ 2147559936 AgsCfg: 223 AGS
 SG_ RsvBits2 : 117|3@1+ (1,0) [0|0] "" AGS,DIAG,UI,xMiata_AGS
 SG_ RsvBits1 : 58|6@1+ (1,0) [0|0] "" AGS,DIAG,UI,xMiata_AGS
 SG_ QtEnDis : 56|2@1+ (1,0) [0|0] "" AGS,DIAG,UI,xMiata_AGS
 SG_ QtEnd : 40|16@1+ (1,0) [0|65532] "minutes" AGS,DIAG,UI,xMiata_AGS
 SG_ QtBeg : 24|16@1+ (1,0) [0|65532] "minutes" AGS,DIAG,UI,xMiata_AGS
 SG_ MsgCount : 2|6@1+ (1,0) [0|0] "" AGS,DIAG,UI,xMiata_AGS
 SG_ MaxAutoCycNoUserMin : 96|8@1+ (1,0) [0|252] "" AGS,DIAG,UI,xMiata_AGS
 SG_ MaxAutoCycNoUserMax : 104|8@1+ (1,0) [0|252] "" AGS,DIAG,UI,xMiata_AGS
 SG_ MaxAutoCycNoUser : 88|8@1+ (1,0) [0|252] "" AGS,DIAG,UI,xMiata_AGS
 SG_ FloatAutoStopEnDis : 86|2@1+ (1,0) [0|0] "" AGS,DIAG,UI,xMiata_AGS
 SG_ DcVAutoStopEnDis : 66|2@1+ (1,0) [0|0] "" AGS,DIAG,UI,xMiata_AGS
 SG_ DcVAutoStartEnDis : 64|2@1+ (1,0) [0|0] "" AGS,DIAG,UI,xMiata_AGS
 SG_ DcIAutoStopEnDis : 70|2@1+ (1,0) [0|0] "" AGS,DIAG,UI,xMiata_AGS
 SG_ DcIAutoStartEnDis : 68|2@1+ (1,0) [0|0] "" AGS,DIAG,UI,xMiata_AGS
 SG_ ConcurAccCtr : 8|8@1+ (1,0) [0|252] "" AGS,DIAG,UI,xMiata_AGS
 SG_ CntctInst : 112|3@1+ (1,0) [0|0] "" AGS,DIAG,UI,xMiata_AGS
 SG_ CntctClsAutoEnDis : 115|2@1+ (1,0) [0|0] "" AGS,DIAG,UI,xMiata_AGS
 SG_ CfgType : 0|2@1+ (1,0) [0|0] "" AGS,DIAG,UI,xMiata_AGS
 SG_ BattSocAutoStopEnDis : 74|2@1+ (1,0) [0|0] "" AGS,DIAG,UI,xMiata_AGS
 SG_ BattSocAutoStartEnDis : 72|2@1+ (1,0) [0|0] "" AGS,DIAG,UI,xMiata_AGS
 SG_ AcSrcId : 16|8@1+ (1,0) [0|252] "" AGS,DIAG,UI,xMiata_AGS
 SG_ AcPwrAutoStopEnDis : 82|2@1+ (1,0) [0|0] "" AGS,DIAG,UI,xMiata_AGS
 SG_ AcPwrAutoStartEnDis : 80|2@1+ (1,0) [0|0] "" AGS,DIAG,UI,xMiata_AGS
 SG_ AcIAutoStopEnDis : 78|2@1+ (1,0) [0|0] "" AGS,DIAG,UI,xMiata_AGS
 SG_ AcIAutoStartEnDis : 76|2@1+ (1,0) [0|0] "" AGS,DIAG,UI,xMiata_AGS
 SG_ AbsorpAutoStopEnDis : 84|2@1+ (1,0) [0|0] "" AGS,DIAG,UI,xMiata_AGS

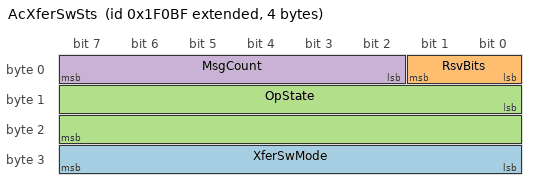
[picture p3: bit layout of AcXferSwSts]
BO_ 2147610815 AcXferSwSts: 4 xSolarWave
 SG_ XferSwMode : 24|8@1+ (1,0) [0|252] "" AGS,CHG,DIAG,INV,INV_CHG,UI,xSolarWave
 SG_ RsvBits : 0|2@1+ (1,0) [0|0] "" AGS,CHG,DIAG,INV,INV_CHG,UI,xSolarWave
 SG_ OpState : 8|16@1+ (1,0) [0|65532] "" AGS,CHG,DIAG,INV,INV_CHG,UI,xSolarWave
 SG_ MsgCount : 2|6@1+ (1,0) [0|0] "" AGS,CHG,DIAG,INV,INV_CHG,UI,xSolarWave

BO_ 2147599360 AcXferSwCfg: 223 DIAG
 SG_ XferSwMode : 16|8@1+ (1,0) [0|252] "" DIAG,UI,xSolarWave
 SG_ XferSwDelay : 32|16@1+ (0.01,0) [0|655.32] "seconds" DIAG,UI,xSolarWave
 SG_ MsgCount : 2|6@1+ (1,0) [0|0] "" DIAG,UI,xSolarWave
 SG_ ConcurAccCtr : 8|8@1+ (1,0) [0|252] "" DIAG,UI,xSolarWave
 SG_ CfgType : 0|2@1+ (1,0) [0|0] "" DIAG,UI,xSolarWave
 SG_ AcSrcId : 24|8@1+ (1,0) [0|252] "" DIAG,UI,xSolarWave

BO_ 2147612869 ActiveWarnSts2: 223 AGS
 SG_ WarnType : 8|3@1+ (1,0) [0|0] "" DIAG,GATEWAY,UI
 SG_ WarnTime : 24|32@1+ (1,0) [0|4.29497E+09] "seconds" DIAG,GATEWAY,UI
 SG_ WarnId : 11|13@1+ (1,0) [0|0] "" DIAG,GATEWAY,UI
 SG_ StringId : 56|16@1+ (1,0) [0|65532] "" DIAG,GATEWAY,UI
 SG_ RsvBits : 0|2@1+ (1,0) [0|0] "" DIAG,GATEWAY,UI
 SG_ MsgCount : 2|6@1+ (1,0) [0|0] "" DIAG,GATEWAY,UI

BO_ 2147612685 ActiveWarnSts: 223 AGS
 SG_ WarnType : 8|3@1+ (1,0) [0|0] "" DIAG,GATEWAY,UI
 SG_ WarnTime : 24|32@1+ (1,0) [0|4.29497E+09] "seconds" DIAG,GATEWAY,UI
 SG_ WarnId : 11|13@1+ (1,0) [0|0] "" DIAG,GATEWAY,UI
 SG_ RsvBits : 0|2@1+ (1,0) [0|0] "" DIAG,GATEWAY,UI
 SG_ MsgCount : 2|6@1+ (1,0) [0|0] "" DIAG,GATEWAY,UI

BO_ 2147612870 ActiveFaultSts2: 223 AGS
 SG_ StringId : 56|16@1+ (1,0) [0|65532] "" BMS,DIAG,GATEWAY,UI
 SG_ RsvBits : 0|2@1+ (1,0) [0|0] "" BMS,DIAG,GATEWAY,UI
 SG_ MsgCount : 2|6@1+ (1,0) [0|0] "" BMS,DIAG,GATEWAY,UI
 SG_ FaultType : 8|3@1+ (1,0) [0|0] "" BMS,DIAG,GATEWAY,UI
 SG_ FaultTime : 24|32@1+ (1,0) [0|4.29497E+09] "seconds" BMS,DIAG,GATEWAY,UI
 SG_ FaultId : 11|13@1+ (1,0) [0|0] "" BMS,DIAG,GATEWAY,UI

BO_ 2147612683 ActiveFaultSts: 223 AGS
 SG_ RsvBits : 0|2@1+ (1,0) [0|0] "" DIAG,GATEWAY,UI
 SG_ MsgCount : 2|6@1+ (1,0) [0|0] "" DIAG,GATEWAY,UI
 SG_ FaultType : 8|3@1+ (1,0) [0|0] "" DIAG,GATEWAY,UI
 SG_ FaultTime : 24|32@1+ (1,0) [0|4.29497E+09] "seconds" DIAG,GATEWAY,UI
 SG_ FaultId : 11|13@1+ (1,0) [0|0] "" DIAG,GATEWAY,UI

BO_ 2147610646 AcStsRms: 223 CHG
 SG_ Voltage : 40|32@1+ (0.001,0) [0|4.29497E+06] "V" AGS,CHG,DIAG,GATEWAY,INV_CHG,UI,xSolarWave
 SG_ TotalFlag : 16|2@1+ (1,0) [0|0] "" AGS,CHG,DIAG,GATEWAY,INV_CHG,UI,xSolarWave
 SG_ RsvBits2 : 18|6@1+ (1,0) [0|0] "" AGS,CHG,DIAG,GATEWAY,INV_CHG,UI,xSolarWave
 SG_ RsvBits1 : 0|2@1+ (1,0) [0|0] "" AGS,CHG,DIAG,GATEWAY,INV_CHG,UI,xSolarWave
 SG_ RealPwrPer : 208|8@1+ (1,0) [0|252] "%" AGS,CHG,DIAG,GATEWAY,INV_CHG,UI,xSolarWave
 SG_ RealPwr : 176|32@1- (1,0) [-2.14748E+09|2.14748E+09] "W" AGS,CHG,DIAG,GATEWAY,INV_CHG,UI,xSolarWave
 SG_ Quality : 32|8@1+ (1,0) [0|252] "" AGS,CHG,DIAG,GATEWAY,INV_CHG,UI,xSolarWave
 SG_ PowerFactor : 216|8@1- (0.01,0) [-1|1] "" AGS,CHG,DIAG,GATEWAY,INV_CHG,UI,xSolarWave
 SG_ MsgCount : 2|6@1+ (1,0) [0|0] "" AGS,CHG,DIAG,GATEWAY,INV_CHG,UI,xSolarWave
 SG_ Line : 24|8@1+ (1,0) [0|252] "" AGS,CHG,DIAG,GATEWAY,INV_CHG,UI,xSolarWave
 SG_ Freq : 112|16@1+ (0.01,0) [0|655.32] "Hz" AGS,CHG,DIAG,GATEWAY,INV_CHG,UI,xSolarWave
 SG_ CurrentPer : 104|8@1+ (1,0) [0|252] "%" AGS,CHG,DIAG,GATEWAY,INV_CHG,UI,xSolarWave
 SG_ Current : 72|32@1- (0.001,0) [-2.14748E+06|2.14748E+06] "Amps" AGS,CHG,DIAG,GATEWAY,INV_CHG,UI,xSolarWave
 SG_ BreakerSz : 128|16@1+ (0.01,0) [0|655.32] "A" AGS,CHG,DIAG,GATEWAY,INV_CHG,UI,xSolarWave
 SG_ ApparentPwr : 144|32@1- (1,0) [-2.14748E+09|2.14748E+09] "VA" AGS,CHG,DIAG,GATEWAY,INV_CHG,UI,xSolarWave
 SG_ AcSrcId : 8|8@1+ (1,0) [0|252] "" AGS,CHG,DIAG,GATEWAY,INV_CHG,UI,xSolarWave

BO_ 2147610630 AcOutStsRms: 223 DIAG
 SG_ Waveform : 24|8@1+ (1,0) [0|252] "" AGS,DIAG,GATEWAY,INV,INV_CHG,UI,xMiata_AGS,xSolarWave
 SG_ Voltage : 40|32@1+ (0.001,0) [0|4.29497E+06] "V" AGS,DIAG,GATEWAY,INV,INV_CHG,UI,xMiata_AGS,xSolarWave
 SG_ TotalFlag : 8|2@1+ (1,0) [0|0] "" AGS,DIAG,GATEWAY,INV,INV_CHG,UI,xMiata_AGS,xSolarWave
 SG_ RsvBits2 : 10|6@1+ (1,0) [0|0] "" AGS,DIAG,GATEWAY,INV,INV_CHG,UI,xMiata_AGS,xSolarWave
 SG_ RsvBits1 : 0|2@1+ (1,0) [0|0] "" AGS,DIAG,GATEWAY,INV,INV_CHG,UI,xMiata_AGS,xSolarWave
 SG_ RealPwrPer : 208|8@1+ (1,0) [0|252] "%" AGS,DIAG,GATEWAY,INV,INV_CHG,UI,xMiata_AGS,xSolarWave
 SG_ RealPwr : 176|32@1- (1,0) [-2.14748E+09|2.14748E+09] "W" AGS,DIAG,GATEWAY,INV,INV_CHG,UI,xMiata_AGS,xSolarWave
 SG_ MsgCount : 2|6@1+ (1,0) [0|0] "" AGS,DIAG,GATEWAY,INV,INV_CHG,UI,xMiata_AGS,xSolarWave
 SG_ Line : 32|8@1+ (1,0) [0|252] "" AGS,DIAG,GATEWAY,INV,INV_CHG,UI,xMiata_AGS,xSolarWave
 SG_ Freq : 112|16@1+ (0.01,0) [0|655.32] "Hz" AGS,DIAG,GATEWAY,INV,INV_CHG,UI,xMiata_AGS,xSolarWave
 SG_ CurrentPer : 104|8@1+ (1,0) [0|252] "%" AGS,DIAG,GATEWAY,INV,INV_CHG,UI,xMiata_AGS,xSolarWave
 SG_ Current : 72|32@1+ (0.001,0) [0|4.29497E+06] "Amps" AGS,DIAG,GATEWAY,INV,INV_CHG,UI,xMiata_AGS,xSolarWave
 SG_ BreakerSz : 128|16@1+ (0.01,0) [0|655.32] "A" AGS,DIAG,GATEWAY,INV,INV_CHG,UI,xMiata_AGS,xSolarWave
 SG_ ApparentPwr : 144|32@1+ (1,0) [0|4.29497E+09] "VA" AGS,DIAG,GATEWAY,INV,INV_CHG,UI,xMiata_AGS,xSolarWave
 SG_ AcSrcId : 16|8@1+ (1,0) [0|252] "" AGS,DIAG,GATEWAY,INV,INV_CHG,UI,xMiata_AGS,xSolarWave

BO_ 2147610631 AcOutStsPeak: 223 DIAG
 SG_ Waveform : 24|8@1+ (1,0) [0|252] "" AGS,DIAG,INV,INV_CHG,UI
 SG_ Voltage : 40|32@1+ (0.001,0) [0|4.29497E+06] "V" AGS,DIAG,INV,INV_CHG,UI
 SG_ TotalFlag : 8|2@1+ (1,0) [0|0] "" AGS,DIAG,INV,INV_CHG,UI
 SG_ RsvBits2 : 10|6@1+ (1,0) [0|0] "" AGS,DIAG,INV,INV_CHG,UI
 SG_ RsvBits1 : 0|2@1+ (1,0) [0|0] "" AGS,DIAG,INV,INV_CHG,UI
 SG_ RealPwrPer : 208|8@1+ (1,0) [0|252] "%" AGS,DIAG,INV,INV_CHG,UI
 SG_ RealPwr : 176|32@1+ (1,0) [0|4.29497E+09] "W" AGS,DIAG,INV,INV_CHG,UI
 SG_ MsgCount : 2|6@1+ (1,0) [0|0] "" AGS,DIAG,INV,INV_CHG,UI
 SG_ Line : 32|8@1+ (1,0) [0|252] "" AGS,DIAG,INV,INV_CHG,UI
 SG_ Freq : 112|16@1+ (0.01,0) [0|655.32] "Hz" AGS,DIAG,INV,INV_CHG,UI
 SG_ CurrentPer : 104|8@1+ (1,0) [0|252] "%" AGS,DIAG,INV,INV_CHG,UI
 SG_ Current : 72|32@1+ (0.001,0) [0|4.29497E+06] "Amps" AGS,DIAG,INV,INV_CHG,UI
 SG_ BreakerSz : 128|16@1+ (0.01,0) [0|655.32] "A" AGS,DIAG,INV,INV_CHG,UI
 SG_ ApparentPwr : 144|32@1+ (1,0) [0|4.29497E+09] "VA" AGS,DIAG,INV,INV_CHG,UI
 SG_ AcSrcId : 16|8@1+ (1,0) [0|252] "" AGS,DIAG,INV,INV_CHG,UI

BO_ 2147610632 AcOutStsAvg: 223 DIAG
 SG_ Waveform : 24|8@1+ (1,0) [0|252] "" AGS,DIAG,INV,INV_CHG,UI
 SG_ Voltage : 40|32@1+ (0.001,0) [0|4.29497E+06] "V" AGS,DIAG,INV,INV_CHG,UI
 SG_ TotalFlag : 8|2@1+ (1,0) [0|0] "" AGS,DIAG,INV,INV_CHG,UI
 SG_ RsvBits2 : 10|6@1+ (1,0) [0|0] "" AGS,DIAG,INV,INV_CHG,UI
 SG_ RsvBits1 : 0|2@1+ (1,0) [0|0] "" AGS,DIAG,INV,INV_CHG,UI
 SG_ RealPwrPer : 208|8@1+ (1,0) [0|252] "%" AGS,DIAG,INV,INV_CHG,UI
 SG_ RealPwr : 176|32@1+ (1,0) [0|4.29497E+09] "W" AGS,DIAG,INV,INV_CHG,UI
 SG_ MsgCount : 2|6@1+ (1,0) [0|0] "" AGS,DIAG,INV,INV_CHG,UI
 SG_ Line : 32|8@1+ (1,0) [0|252] "" AGS,DIAG,INV,INV_CHG,UI
 SG_ Freq : 112|16@1+ (0.01,0) [0|655.32] "Hz" AGS,DIAG,INV,INV_CHG,UI
 SG_ CurrentPer : 104|8@1+ (1,0) [0|252] "%" AGS,DIAG,INV,INV_CHG,UI
 SG_ Current : 72|32@1+ (0.001,0) [0|4.29497E+06] "Amps" AGS,DIAG,INV,INV_CHG,UI
 SG_ BreakerSz : 128|16@1+ (0.01,0) [0|655.32] "A" AGS,DIAG,INV,INV_CHG,UI
 SG_ ApparentPwr : 144|32@1+ (1,0) [0|4.29497E+09] "VA" AGS,DIAG,INV,INV_CHG,UI
 SG_ AcSrcId : 16|8@1+ (1,0) [0|252] "" AGS,DIAG,INV,INV_CHG,UI

BO_ 2147570176 AcOutCfgUvRms: 223 DIAG
 SG_ UvLvlMin : 88|32@1- (0.001,0) [-2.14748E+06|2.14748E+06] "V" DIAG,INV,INV_CHG,UI,xNova,xSolarWave
 SG_ UvLvlMax : 120|32@1- (0.001,0) [-2.14748E+06|2.14748E+06] "V" DIAG,INV,INV_CHG,UI,xNova,xSolarWave
 SG_ UvLvl : 56|32@1- (0.001,0) [-2.14748E+06|2.14748E+06] "V" DIAG,INV,INV_CHG,UI,xNova,xSolarWave
 SG_ UvIntvlMin : 168|16@1+ (0.01,0) [0|655.32] "seconds" DIAG,INV,INV_CHG,UI,xNova,xSolarWave
 SG_ UvIntvlMax : 184|16@1+ (0.01,0) [0|655.32] "seconds" DIAG,INV,INV_CHG,UI,xNova,xSolarWave
 SG_ UvIntvl : 152|16@1+ (0.01,0) [0|655.32] "seconds" DIAG,INV,INV_CHG,UI,xNova,xSolarWave
 SG_ RefEvtId : 40|16@1+ (1,0) [0|65532] "" DIAG,INV,INV_CHG,UI,xNova,xSolarWave
 SG_ MsgCount : 2|6@1+ (1,0) [0|0] "" DIAG,INV,INV_CHG,UI,xNova,xSolarWave
 SG_ EvtId : 24|16@1+ (1,0) [0|65532] "" DIAG,INV,INV_CHG,UI,xNova,xSolarWave
 SG_ ConcurAccCtr : 8|8@1+ (1,0) [0|252] "" DIAG,INV,INV_CHG,UI,xNova,xSolarWave
 SG_ CfgType : 0|2@1+ (1,0) [0|0] "" DIAG,INV,INV_CHG,UI,xNova,xSolarWave
 SG_ AcSrcId : 16|8@1+ (1,0) [0|252] "" DIAG,INV,INV_CHG,UI,xNova,xSolarWave

BO_TX_BU_ 2147560448 : xSolarWave,CHG,UI,INV_CHG,DIAG,xNova,xSolarSurveyor,BMS;
BO_TX_BU_ 2147567360 : xMiata_AGS,xSolarWave,BATTMON,AGS,INV,CHG,UI,INV_CHG,DIAG,GATEWAY,xNova,xSolarSurveyor,EMS,BMS;
BO_TX_BU_ 2147610662 : BATTMON,INV,CHG,INV_CHG,DIAG;
BO_TX_BU_ 2147610665 : BATTMON,DIAG,BMS;
BO_TX_BU_ 2147574528 : xSolarWave,BATTMON,INV,UI,INV_CHG,DIAG,BMS;
BO_TX_BU_ 2147610820 : xSolarWave,BATTMON,INV,CHG,INV_CHG,DIAG,xSolarSurveyor;
BO_TX_BU_ 2147576064 : UI,DIAG,GATEWAY;
BO_TX_BU_ 2147574784 : BATTMON,UI,DIAG;
BO_TX_BU_ 2147559680 : BATTMON,UI,DIAG;
BO_TX_BU_ 2147563008 : xMiata_AGS,xSolarWave,BATTMON,AGS,INV,CHG,INV_CHG,xNova,xSolarSurveyor,EMS,BMS;
BO_TX_BU_ 2147558656 : xMiata_AGS,xSolarWave,BATTMON,AGS,INV,CHG,UI,INV_CHG,DIAG,xNova,xSolarSurveyor,EMS,BMS;
BO_TX_BU_ 2147610633 : xSolarWave,INV,CHG,INV_CHG,DIAG,xNova;
BO_TX_BU_ 2147552512 : xSolarWave,INV,CHG,INV_CHG,DIAG,xNova;
BO_TX_BU_ 2147552768 : xSolarWave,INV,CHG,INV_CHG,DIAG,xNova;
BO_TX_BU_ 2147610647 : xMiata_AGS,AGS;
BO_TX_BU_ 2147610641 : xMiata_AGS,AGS;
BO_TX_BU_ 2147610648 : xMiata_AGS,AGS;
BO_TX_BU_ 2147557120 : UI,DIAG,GATEWAY;
BO_TX_BU_ 2147560192 : xMiata_AGS,AGS,UI,DIAG;
BO_TX_BU_ 2147564544 : xMiata_AGS,AGS,UI,DIAG;
BO_TX_BU_ 2147571200 : AGS,UI,DIAG;
BO_TX_BU_ 2147565312 : xMiata_AGS,AGS,UI,DIAG;
BO_TX_BU_ 2147564800 : xMiata_AGS,AGS,UI,DIAG;
BO_TX_BU_ 2147571456 : AGS,UI,DIAG;
BO_TX_BU_ 2147565056 : xMiata_AGS,AGS,UI,DIAG;
BO_TX_BU_ 2147559936 : xMiata_AGS,AGS,UI,DIAG;
BO_TX_BU_ 2147599360 : xSolarWave,UI,DIAG;
BO_TX_BU_ 2147612869 : xSolarWave,BATTMON,AGS,INV,CHG,UI,INV_CHG,DIAG,GATEWAY,xSolarSurveyor,EMS,BMS;
BO_TX_BU_ 2147612685 : xMiata_AGS,BATTMON,AGS,INV,CHG,UI,INV_CHG,DIAG,GATEWAY,xNova;
BO_TX_BU_ 2147612870 : xSolarWave,BATTMON,AGS,INV,CHG,UI,INV_CHG,DIAG,GATEWAY,xSolarSurveyor,EMS,BMS;
BO_TX_BU_ 2147612683 : xMiata_AGS,BATTMON,AGS,INV,CHG,UI,INV_CHG,DIAG,GATEWAY,xNova;
BO_TX_BU_ 2147610646 : xSolarWave,CHG,INV_CHG,DIAG,xNova;
BO_TX_BU_ 2147610630 : xSolarWave,INV,INV_CHG,DIAG,xNova;
BO_TX_BU_ 2147610631 : INV,INV_CHG,DIAG;
BO_TX_BU_ 2147610632 : INV,INV_CHG,DIAG;
BO_TX_BU_ 2147570176 : xSolarWave,INV,UI,INV_CHG,DIAG,xNova;
CM_ BO_ 2147560448 "Charger Configuration";
CM_ SG_ 2147560448 RsvBits "Reserved Bits";
CM_ SG_ 2147560448 OverChgEnDis "Over Charge Enable/Disable";
CM_ SG_ 2147560448 MsgCount "Message Count";
CM_ SG_ 2147560448 EqlzOneTimeEnDis "Equalize One-Time Enable/Disable";
CM_ SG_ 2147560448 DcSrcId "DC Source Identifier";
CM_ SG_ 2147560448 ConcurAccCtr "Concurrent Access Counter";
CM_ SG_ 2147560448 ChgOverrideEnDis "Charger Override Enable/Disable";
CM_ SG_ 2147560448 ChgMode "Charge Mode";
CM_ SG_ 2147560448 ChgILimitMin "Charger Current Limit - Minimum";
CM_ SG_ 2147560448 ChgILimitMax "Charger Current Limit - Maximum";
CM_ SG_ 2147560448 ChgILimit "Charger Current Limit";
CM_ SG_ 2147560448 ChgAlgorithm "Charging Algorithm";
CM_ SG_ 2147560448 CfgType "Configuration Type";
CM_ SG_ 2147560448 BattTempNoSensor "Battery Temperature - No Sensor";
CM_ BO_ 2147567360 "Configuration";
CM_ SG_ 2147567360 RsvBits "Reserved Bits";
CM_ SG_ 2147567360 MsgCount "Message Count";
CM_ SG_ 2147567360 IdPeriod "Identify Period";
CM_ SG_ 2147567360 FaultAutoRst "Fault Automatic Reset";
CM_ SG_ 2147567360 EntSleepTo "Enter Sleep Timeout";
CM_ SG_ 2147567360 EntHibTo "Enter Hibernate Timeout";
CM_ SG_ 2147567360 ConcurAccCtr "Concurrent Access Counter";
CM_ SG_ 2147567360 CfgType "Configuration Type";
CM_ BO_ 2147610662 "Calibration Data Status";
CM_ SG_ 2147610662 RsvBits2 "Reserved Bits 2";
CM_ SG_ 2147610662 RsvBits1 "Reserved Bits 1";
CM_ SG_ 2147610662 MsgCount "Message Count";
CM_ SG_ 2147610662 CalibDataId "Calibration Data ID";
CM_ SG_ 2147610662 CalibData "Calibration Data";
CM_ BO_ 2147556864 "Calibration Command";
CM_ SG_ 2147556864 StsPgn "Status Parameter Group Number";
CM_ SG_ 2147556864 RsvBits "Reserved Bits";
CM_ SG_ 2147556864 DataPtId "Data Point Identifier";
CM_ SG_ 2147556864 DataPtCnt "Data Point Count";
CM_ SG_ 2147556864 CalibEnDis "Calibration Enable/Disable";
CM_ BO_ 2147610665 "Battery Management System Status";
CM_ SG_ 2147610665 RsvBits "Reserved Bits";
CM_ SG_ 2147610665 ReferenceV "Reference Voltage";
CM_ SG_ 2147610665 ReferenceI "Reference Current";
CM_ SG_ 2147610665 ReadbackV "Readback Voltage";
CM_ SG_ 2147610665 ReadbackI "Readback Current";
CM_ SG_ 2147610665 MsgCount "Message Count";
CM_ SG_ 2147610665 DcSrcId "DC Source Identifier";
CM_ BO_ 2147574528 "Battery Management System Configuration";
CM_ SG_ 2147574528 MsgCount "Message Count";
CM_ SG_ 2147574528 MaxDischargeTimeIntMin "Maximum Discharge Time Interval - Minimum";
CM_ SG_ 2147574528 MaxDischargeTimeIntMax "Maximum Discharge Time Interval - Maximum";
CM_ SG_ 2147574528 MaxDischargeTimeInt "Maximum Discharge Time Interval";
CM_ SG_ 2147574528 MaxDischargeIMin "Maximum Discharge Current - Minimum";
CM_ SG_ 2147574528 MaxDischargeIMax "Maximum Discharge Current - Maximum";
CM_ SG_ 2147574528 MaxDischargeI "Maximum Discharge Current";
CM_ SG_ 2147574528 DcSrcId "DC Source Identifier";
CM_ SG_ 2147574528 ConcurAccCtr "Concurrent Access Counter";
CM_ SG_ 2147574528 CfgType "Configuration Type";
CM_ SG_ 2147574528 BattType "Battery Type";
CM_ BO_ 2147610820 "Battery Status (Deux)";
CM_ SG_ 2147610820 Voltage "Voltage";
CM_ SG_ 2147610820 TimeToFull "Time to Full";
CM_ SG_ 2147610820 TimeRemain "Time Remaining";
CM_ SG_ 2147610820 TempSensId "Temperature Sensor Identifier";
CM_ SG_ 2147610820 Temp "Temperature";
CM_ SG_ 2147610820 Soh "State of Health";
CM_ SG_ 2147610820 Soc "State of Charge";
CM_ SG_ 2147610820 RsvBits "Reserved Bits";
CM_ SG_ 2147610820 RippleVoltage "Ripple Voltage";
CM_ SG_ 2147610820 Pwr "Power";
CM_ SG_ 2147610820 NomBattVoltage "Nominal Battery Voltage";
CM_ SG_ 2147610820 MsgCount "Message Count";
CM_ SG_ 2147610820 EnergyRemain "Energy Remaining";
CM_ SG_ 2147610820 DcSrcId "DC Source Identifier";
CM_ SG_ 2147610820 Current "Current";
CM_ SG_ 2147610820 BattType "Battery Type";
CM_ SG_ 2147610820 BattCapRemain "Battery Capacity Remaining";
CM_ SG_ 2147610820 BattCapPer "Battery Capacity Percent of Maximum";
CM_ BO_ 2147610651 "Battery Monitor Status";
CM_ SG_ 2147610651 Voltage "Voltage";
CM_ SG_ 2147610651 TimeToFull "Time to Full";
CM_ SG_ 2147610651 TimeToDischarge "Time to Discharge";
CM_ SG_ 2147610651 Temp "Temperature";
CM_ SG_ 2147610651 Soh "State of Health";
CM_ SG_ 2147610651 Soc "State of Charge";
CM_ SG_ 2147610651 RsvBits "Reserved Bits";
CM_ SG_ 2147610651 RsvBits "Reserved Bits";
CM_ SG_ 2147610651 PerOvercharge "Percent Overcharge";
CM_ SG_ 2147610651 MsgCount "Message Count";
CM_ SG_ 2147610651 Mid3Voltage "Midpoint 3 Voltage";
CM_ SG_ 2147610651 Mid2Voltage "Midpoint 2 Voltage";
CM_ SG_ 2147610651 Mid1Voltage "Midpoint 1 Voltage";
CM_ SG_ 2147610651 LastEqualize "Last Equalize";
CM_ SG_ 2147610651 HoursInFloat "Hours in Float";
CM_ SG_ 2147610651 DcSrcId "DC Source Identifier";
CM_ SG_ 2147610651 Current "Current";
CM_ SG_ 2147610651 BtsPresent "BTS Present";
CM_ SG_ 2147610651 BattCapRemoved "Battery Capacity Removed";
CM_ SG_ 2147610651 BattCapRemain "Battery Capacity Remaining";
CM_ BO_ 2147610645 "Battery Monitor Statistics - Battery";
CM_ SG_ 2147610645 VoltageMin "Voltage Minimum";
CM_ SG_ 2147610645 VoltageMax "Voltage Maximum";
CM_ SG_ 2147610645 TimeSinceSync "Time Since Synchronization";
CM_ SG_ 2147610645 TempMin "Lowest Temperature";
CM_ SG_ 2147610645 TempMax "Highest Temperature";
CM_ SG_ 2147610645 RsvBits "Reserved Bits";
CM_ SG_ 2147610645 PreviousPeriodCount "Previous Period Count";
CM_ SG_ 2147610645 PreviousPeriod "Previous Period";
CM_ SG_ 2147610645 NumSync "Number of Synchronizations";
CM_ SG_ 2147610645 NumSoc90 "Number of times SOC < 90%";
CM_ SG_ 2147610645 NumSoc75 "Number of times SOC < 75%";
CM_ SG_ 2147610645 NumSoc50 "Number of times SOC < 50%";
CM_ SG_ 2147610645 NumSoc25 "Number of times SOC < 25%";
CM_ SG_ 2147610645 NumDischg "Number of Discharges";
CM_ SG_ 2147610645 NumChg "Number of Charge cycles";
CM_ SG_ 2147610645 MsgCount "Message Count";
CM_ SG_ 2147610645 EnergyOut "Energy Removed from Battery";
CM_ SG_ 2147610645 EnergyIn "Energy Into the Battery";
CM_ SG_ 2147610645 DeepestSoc "Deepest State of Charge Percent";
CM_ SG_ 2147610645 DeepestDischgPer "Deepest Discharge Percent";
CM_ SG_ 2147610645 DeepestDischg "Deepest Discharge";
CM_ SG_ 2147610645 DcSrcId "DC Source Identifier";
CM_ SG_ 2147610645 CurrentMaxDischg "Current Maximum while Discharging";
CM_ SG_ 2147610645 CurrentMaxChg "Current Maximum while Charging";
CM_ SG_ 2147610645 CapacityReturned "Capacity Returned to Battery";
CM_ SG_ 2147610645 CapacityRemoved "Capacity Removed from Battery";
CM_ SG_ 2147610645 CapacityMin "Capacity Minimum";
CM_ SG_ 2147610645 CapacityMax "Capacity Maximum";
CM_ SG_ 2147610645 AvgDischgPer "Average Discharge Percent";
CM_ SG_ 2147610645 AvgDischg "Average Discharge";
CM_ BO_ 2147610829 "Battery Monitor History";
CM_ SG_ 2147610829 RsvBits "Reserved Bits";
CM_ SG_ 2147610829 NumSync "Number of Synchronizations";
CM_ SG_ 2147610829 NumDischg "Number of Discharges";
CM_ SG_ 2147610829 NumChg "Number of Charge cycles";
CM_ SG_ 2147610829 MsgCount "Message Count";
CM_ SG_ 2147610829 DeepestDischgPer "Deepest Discharge Percent";
CM_ SG_ 2147610829 DeepestDischg "Deepest Discharge";
CM_ SG_ 2147610829 DcSrcId "DC Source Identifier";
CM_ SG_ 2147610829 CapacityReturned "Capacity Returned to Battery";
CM_ SG_ 2147610829 CapacityRemoved "Capacity Removed from Battery";
CM_ SG_ 2147610829 AvgDischgPer "Average Discharge Percent";
CM_ SG_ 2147610829 AvgDischg "Average Discharge";
CM_ BO_ 2147576064 "Battery Monitor Control Command";
CM_ SG_ 2147576064 SyncEnDis "Synchronize Enable/Disable";
CM_ SG_ 2147576064 RsvBits "Reserved Bits";
CM_ SG_ 2147576064 DcSrcId "DC Source Identifier";
CM_ BO_ 2147574784 "Battery Monitor Configuration - Synchronization";
CM_ SG_ 2147574784 RsvBits "Reserved Bits";
CM_ SG_ 2147574784 MsgCount "Message Count";
CM_ SG_ 2147574784 DischgFloorMin "Discharge Floor - Minimum";
CM_ SG_ 2147574784 DischgFloorMax "Discharge Floor - Maximum";
CM_ SG_ 2147574784 DischgFloor "Discharge Floor";
CM_ SG_ 2147574784 DcSrcId "DC Source Identifier";
CM_ SG_ 2147574784 ConcurAccCtr "Concurrent Access Counter";
CM_ SG_ 2147574784 ChgFloatVMin "Charger's Float Voltage - Minimum";
CM_ SG_ 2147574784 ChgFloatVMax "Charger's Float Voltage - Maximum";
CM_ SG_ 2147574784 ChgFloatV "Charger's Float Voltage";
CM_ SG_ 2147574784 ChgFloatIMin "Charger's Float Current - Minimum";
CM_ SG_ 2147574784 ChgFloatIMax "Charger's Float Current - Maximum";
CM_ SG_ 2147574784 ChgFloatI "Charger's Float Current";
CM_ SG_ 2147574784 CfgType "Configuration Type";
CM_ SG_ 2147574784 AutoSyncTime "Auto-Sync Time";
CM_ SG_ 2147574784 AutoSyncSensMin "Auto-Sync Sensitivity - Minimum";
CM_ SG_ 2147574784 AutoSyncSensMax "Auto-Sync Sensitivity - Maximum";
CM_ SG_ 2147574784 AutoSyncSens "Auto-Sync Sensitivity";
CM_ BO_ 2147559680 "Battery Monitor Configuration";
CM_ SG_ 2147559680 TimeRemAvgFilter "Time Remaining Averaging Filter";
CM_ SG_ 2147559680 TempUnit "Temperature Unit";
CM_ SG_ 2147559680 ShuntVoltRating "Shunt Voltage Rating";
CM_ SG_ 2147559680 ShuntAmpRating "Shunt Amp Rating";
CM_ SG_ 2147559680 SetupLock "Setup Lock";
CM_ SG_ 2147559680 SelfDischargeRateMin "Self Discharge Rate - Minimum";
CM_ SG_ 2147559680 SelfDischargeRateMax "Self Discharge Rate - Maximum";
CM_ SG_ 2147559680 SelfDischargeRate "Self Discharge Rate";
CM_ SG_ 2147559680 RsvBits "Reserved Bits";
CM_ SG_ 2147559680 NomV "Nominal Voltage";
CM_ SG_ 2147559680 NomTempMin "Nominal Temperature - Minimum";
CM_ SG_ 2147559680 NomTempMax "Nominal Temperature - Maximum";
CM_ SG_ 2147559680 NomTemp "Nominal Temperature";
CM_ SG_ 2147559680 NomDisRateMin "Nominal Discharge Rate - Minimum";
CM_ SG_ 2147559680 NomDisRateMax "Nominal Discharge Rate - Maximum";
CM_ SG_ 2147559680 NomDisRate "Nominal Discharge Rate";
CM_ SG_ 2147559680 MsgCount "Message Count";
CM_ SG_ 2147559680 DefaultTempMin "Default Temperature - Minimum";
CM_ SG_ 2147559680 DefaultTempMax "Default Temperature - Maximum";
CM_ SG_ 2147559680 DefaultTemp "Default Temperature";
CM_ SG_ 2147559680 DcSrcId "DC Source Identifier";
CM_ SG_ 2147559680 ConcurAccCtr "Concurrent Access Counter";
CM_ SG_ 2147559680 ChgEfficFactorMode "Charge Efficiency Factor Mode";
CM_ SG_ 2147559680 CfgType "Configuration Type";
CM_ SG_ 2147559680 BattCapTempCoeffMin "Battery Capacity Temperature Coefficient - Minimum";
CM_ SG_ 2147559680 BattCapTempCoeffMax "Battery Capacity Temperature Coefficient - Maximum";
CM_ SG_ 2147559680 BattCapTempCoeff "Battery Capacity Temperature Coefficient";
CM_ SG_ 2147559680 BacklightDuration "Backlight Duration";
CM_ BO_ 2147563008 "Association Status";
CM_ SG_ 2147563008 RsvBits "Reserved Bits";
CM_ SG_ 2147563008 RsvBit "Reserved Bit";
CM_ SG_ 2147563008 MsgCount "Message Count";
CM_ SG_ 2147563008 AssocType "Association Type";
CM_ SG_ 2147563008 AssocInst "Association Instance";
CM_ SG_ 2147563008 AssocId "Association Identifier";
CM_ BO_ 2147558656 "Association Configuration";
CM_ SG_ 2147558656 RsvBit "Reserved Bit";
CM_ SG_ 2147558656 MsgCount "Message Count";
CM_ SG_ 2147558656 ConcurAccCtr "Concurrent Access Counter";
CM_ SG_ 2147558656 CfgType "Configuration Type";
CM_ SG_ 2147558656 AssocType "Association Type";
CM_ SG_ 2147558656 AssocInst "Association Instance";
CM_ SG_ 2147558656 AssocId "Association Identifier";
CM_ BO_ 2147610633 "Auxiliary Power Supply Status";
CM_ SG_ 2147610633 Voltage "Voltage";
CM_ SG_ 2147610633 RsvBits "Reserved Bits";
CM_ SG_ 2147610633 OutputId "Output Identifier";
CM_ SG_ 2147610633 MsgCount "Message Count";
CM_ SG_ 2147610633 Current "Current";
CM_ BO_ 2147552512 "Auxiliary Power Supply Configuration - Under Volta";
CM_ SG_ 2147552512 UvLvlMin "Under Voltage Level - Minimum";
CM_ SG_ 2147552512 UvLvlMax "Under Voltage Level - Maximum";
CM_ SG_ 2147552512 UvLvl "Under Voltage Level";
CM_ SG_ 2147552512 UvIntvlMin "Under Voltage Interval - Minimum";
CM_ SG_ 2147552512 UvIntvlMax "Under Voltage Interval - Maximum";
CM_ SG_ 2147552512 UvIntvl "Under Voltage Interval";
CM_ SG_ 2147552512 RefEvtId "Reference Event Identifier";
CM_ SG_ 2147552512 OutputId "Output Identifier";
CM_ SG_ 2147552512 MsgCount "Message Count";
CM_ SG_ 2147552512 EvtId "Event Identifier";
CM_ SG_ 2147552512 ConcurAccCtr "Concurrent Access Counter";
CM_ SG_ 2147552512 CfgType "Configuration Type";
CM_ BO_ 2147552768 "Auxiliary Power Supply Configuration - Over Voltag";
CM_ SG_ 2147552768 RefEvtId "Reference Event Identifier";
CM_ SG_ 2147552768 OvLvlMin "Over Voltage Level - Minimum";
CM_ SG_ 2147552768 OvLvlMax "Over Voltage Level - Maximum";
CM_ SG_ 2147552768 OvLvl "Over Voltage Level";
CM_ SG_ 2147552768 OvIntvlMin "Over Voltage Interval - Minimum";
CM_ SG_ 2147552768 OvIntvlMax "Over Voltage Interval - Maximum";
CM_ SG_ 2147552768 OvIntvl "Over Voltage Interval";
CM_ SG_ 2147552768 OutputId "Output Identifier";
CM_ SG_ 2147552768 MsgCount "Message Count";
CM_ SG_ 2147552768 EvtId "Event Identifier";
CM_ SG_ 2147552768 ConcurAccCtr "Concurrent Access Counter";
CM_ SG_ 2147552768 CfgType "Configuration Type";
CM_ BO_ 2147610647 "AGS Status - Generator";
CM_ SG_ 2147610647 Temp "Temperature";
CM_ SG_ 2147610647 RsvBits "Reserved Bits";
CM_ SG_ 2147610647 OilPress "Oil Pressure";
CM_ SG_ 2147610647 MsgCount "Message Count";
CM_ SG_ 2147610647 FuelPress "Fuel Pressure";
CM_ SG_ 2147610647 FuelLvl "Fuel Level";
CM_ SG_ 2147610647 EngineDiscreteWarnSts "Engine Discrete Warning Status";
CM_ SG_ 2147610647 BattV "Battery Voltage";
CM_ SG_ 2147610647 AcSrcId "AC Source Identifier";
CM_ BO_ 2147610641 "AGS Status";
CM_ SG_ 2147610641 TimeInt "Time Interval to Start/Stop";
CM_ SG_ 2147610641 RsvBits2 "Reserved Bits 2";
CM_ SG_ 2147610641 RsvBits1 "Reserved Bits 1";
CM_ SG_ 2147610641 OpState "Operating State";
CM_ SG_ 2147610641 MsgCount "Message Count";
CM_ SG_ 2147610641 GenState "Generator State";
CM_ SG_ 2147610641 GenOnReason "Generator 'On' Reason";
CM_ SG_ 2147610641 GenOffReason "Generator 'Off' Reason";
CM_ SG_ 2147610641 AgsGenSig "AGS to Generator Signal";
CM_ SG_ 2147610641 AcSrcId "AC Source Identifier";
CM_ BO_ 2147610648 "AGS Statistics - Generator";
CM_ SG_ 2147610648 TotalRunTime "Total Run Time";
CM_ SG_ 2147610648 SuccStartCnt "Successful Starts Counter";
CM_ SG_ 2147610648 RsvBits "Reserved Bits";
CM_ SG_ 2147610648 PrevRunTime "Previous Run Time";
CM_ SG_ 2147610648 MsgCount "Message Count";
CM_ SG_ 2147610648 FailStartCnt "Failed Starts Counter";
CM_ SG_ 2147610648 CurrRunTime "Current Run Time";
CM_ SG_ 2147610648 AcSrcId "AC Source Identifier";
CM_ BO_ 2147557120 "AGS Control Command";
CM_ SG_ 2147557120 DesiredState "Desired State";
CM_ SG_ 2147557120 AcSrcId "AC Source Identifier";
CM_ BO_ 2147560192 "AGS Configuration - Generator";
CM_ SG_ 2147560192 StopTimeoutMin "Stop Timeout - Minimum";
CM_ SG_ 2147560192 StopTimeoutMax "Stop Timeout - Maximum";
CM_ SG_ 2147560192 StopTimeout "Stop Timeout";
CM_ SG_ 2147560192 StarterCooldownTimeMin "Starter Cooldown Time - Minimum";
CM_ SG_ 2147560192 StarterCooldownTimeMax "Starter Cooldown Time - Maximum";
CM_ SG_ 2147560192 StarterCooldownTime "Starter Cooldown Time";
CM_ SG_ 2147560192 StartDlyMin "Start Delay - Minimum";
CM_ SG_ 2147560192 StartDlyMax "Start Delay - Maximum";
CM_ SG_ 2147560192 StartDly "Start Delay";
CM_ SG_ 2147560192 SpindownTimeMin "Spindown Time - Minimum";
CM_ SG_ 2147560192 SpindownTimeMax "Spindown Time - Maximum";
CM_ SG_ 2147560192 SpindownTime "Spindown Time";
CM_ SG_ 2147560192 ShutdownBypassTimeMin "Shutdown Bypass Time - Minimum";
CM_ SG_ 2147560192 ShutdownBypassTimeMax "Shutdown Bypass Time - Maximum";
CM_ SG_ 2147560192 ShutdownBypassTime "Shutdown Bypass Time";
CM_ SG_ 2147560192 RelayId "Relay Identifier";
CM_ SG_ 2147560192 RelayFunc "Relay Function";
CM_ SG_ 2147560192 PreheatTimeMin "Preheat Time - Minimum";
CM_ SG_ 2147560192 PreheatTimeMax "Preheat Time - Maximum";
CM_ SG_ 2147560192 PreheatTime "Preheat Time";
CM_ SG_ 2147560192 MsgCount "Message Count";
CM_ SG_ 2147560192 MaxRunTimeMin "Maximum Run Time - Minimum";
CM_ SG_ 2147560192 MaxRunTimeMax "Maximum Run Time - Maximum";
CM_ SG_ 2147560192 MaxRunTime "Maximum Run Time";
CM_ SG_ 2147560192 MaxGenStartRetriesMin "Maximum Generator Start Retries - Minimum";
CM_ SG_ 2147560192 MaxGenStartRetriesMax "Maximum Generator Start Retries - Maximum";
CM_ SG_ 2147560192 MaxGenStartRetries "Maximum Generator Start Retries";
CM_ SG_ 2147560192 GenWarmupTimeMin "Generator Warmup Time - Minimum";
CM_ SG_ 2147560192 GenWarmupTimeMax "Generator Warmup Time - Maximum";
CM_ SG_ 2147560192 GenWarmupTime "Generator Warmup Time";
CM_ SG_ 2147560192 GenRunHoldTimeMin "Generator Run Hold Time - Minimum";
CM_ SG_ 2147560192 GenRunHoldTimeMax "Generator Run Hold Time - Maximum";
CM_ SG_ 2147560192 GenRunHoldTime "Generator Run Hold Time";
CM_ SG_ 2147560192 GenOutType "Generator Output Type";
CM_ SG_ 2147560192 GenIntfType "Generator Interface Type";
CM_ SG_ 2147560192 GenCooldownTimeMin "Generator Cool Down Time - Minimum";
CM_ SG_ 2147560192 GenCooldownTimeMax "Generator Cool Down Time - Maximum";
CM_ SG_ 2147560192 GenCooldownTime "Generator Cool Down Time";
CM_ SG_ 2147560192 ExerciseTodMin "Exercise Time of Day - Minimum";
CM_ SG_ 2147560192 ExerciseTodMax "Exercise Time of Day - Maximum";
CM_ SG_ 2147560192 ExerciseTod "Exercise Time of Day";
CM_ SG_ 2147560192 ExercisePerMin "Exercise Period - Minimum";
CM_ SG_ 2147560192 ExercisePerMax "Exercise Period - Maximum";
CM_ SG_ 2147560192 ExercisePer "Exercise Period";
CM_ SG_ 2147560192 ExerciseDurMin "Exercise Duration - Minimum";
CM_ SG_ 2147560192 ExerciseDurMax "Exercise Duration - Maximum";
CM_ SG_ 2147560192 ExerciseDur "Exercise Duration";
CM_ SG_ 2147560192 CrankTimeMin "Crank Time - Minimum";
CM_ SG_ 2147560192 CrankTimeMax "Crank Time - Maximum";
CM_ SG_ 2147560192 CrankTime "Crank Time";
CM_ SG_ 2147560192 CrankRetryTimeMin "Crank Retry Time - Minimum";
CM_ SG_ 2147560192 CrankRetryTimeMax "Crank Retry Time - Maximum";
CM_ SG_ 2147560192 CrankRetryTime "Crank Retry Time";
CM_ SG_ 2147560192 ConcurAccCtr "Concurrent Access Counter";
CM_ SG_ 2147560192 CfgType "Configuration Type";
CM_ SG_ 2147560192 AcSrcId "AC Source Identifier";
CM_ BO_ 2147564544 "AGS Configuration - DC Voltage";
CM_ SG_ 2147564544 VLvlStopMin "Voltage Level to Stop - Min";
CM_ SG_ 2147564544 VLvlStopMax "Voltage Level to Stop - Max";
CM_ SG_ 2147564544 VLvlStartMin "Voltage Level to Start - Min";
CM_ SG_ 2147564544 VLvlStartMax "Voltage Level to Start - Max";
CM_ SG_ 2147564544 VLvl "Voltage Level to Start/Stop";
CM_ SG_ 2147564544 TimeIntStopMin "Time Interval to Stop - Min";
CM_ SG_ 2147564544 TimeIntStopMax "Time Interval to Stop - Max";
CM_ SG_ 2147564544 TimeIntStartMin "Time Interval to Start - Min";
CM_ SG_ 2147564544 TimeIntStartMax "Time Interval to Start - Max";
CM_ SG_ 2147564544 TimeInt "Time Interval to Start/Stop";
CM_ SG_ 2147564544 StartStop "Start or Stop";
CM_ SG_ 2147564544 RsvByte "Reserved Byte";
CM_ SG_ 2147564544 RsvBits "Reserved Bits";
CM_ SG_ 2147564544 PerEnd "Period End";
CM_ SG_ 2147564544 PerBeg "Period Begin";
CM_ SG_ 2147564544 MsgCount "Message Count";
CM_ SG_ 2147564544 DcSrcId "DC Source Identifier";
CM_ SG_ 2147564544 ConcurAccCtr "Concurrent Access Counter";
CM_ SG_ 2147564544 CfgType "Configuration Type";
CM_ BO_ 2147571200 "AGS Configuration - DC Current";
CM_ SG_ 2147571200 TimeIntStopMin "Time Interval to Stop - Min";
CM_ SG_ 2147571200 TimeIntStopMax "Time Interval to Stop - Max";
CM_ SG_ 2147571200 TimeIntStartMin "Time Interval to Start - Min";
CM_ SG_ 2147571200 TimeIntStartMax "Time Interval to Start - Max";
CM_ SG_ 2147571200 TimeInt "Time Interval to Start/Stop";
CM_ SG_ 2147571200 StartStop "Start or Stop";
CM_ SG_ 2147571200 RsvByte "Reserved Byte";
CM_ SG_ 2147571200 RsvBits "Reserved Bits";
CM_ SG_ 2147571200 PerEnd "Period End";
CM_ SG_ 2147571200 PerBeg "Period Begin";
CM_ SG_ 2147571200 MsgCount "Message Count";
CM_ SG_ 2147571200 ILvlStopMin "Current Level to Stop - Min";
CM_ SG_ 2147571200 ILvlStopMax "Current Level to Stop - Max";
CM_ SG_ 2147571200 ILvlStartMin "Current Level to Start - Min";
CM_ SG_ 2147571200 ILvlStartMax "Current Level to Start - Max";
CM_ SG_ 2147571200 ILvl "Current Level to Start/Stop";
CM_ SG_ 2147571200 DcSrcId "DC Source Identifier";
CM_ SG_ 2147571200 ConcurAccCtr "Concurrent Access Counter";
CM_ SG_ 2147571200 CfgType "Configuration Type";
CM_ BO_ 2147565312 "AGS Configuration - Contact Closure";
CM_ SG_ 2147565312 RsvBits "Reserved Bits";
CM_ SG_ 2147565312 PerEnd "Period End";
CM_ SG_ 2147565312 PerBeg "Period Begin";
CM_ SG_ 2147565312 OpnDlyMin "Opening Delay - Min";
CM_ SG_ 2147565312 OpnDlyMax "Opening Delay - Max";
CM_ SG_ 2147565312 OpnDly "Opening Delay";
CM_ SG_ 2147565312 MsgCount "Message Count";
CM_ SG_ 2147565312 ConcurAccCtr "Concurrent Access Counter";
CM_ SG_ 2147565312 CntctInst "Contact Instance";
CM_ SG_ 2147565312 ClsDlyMin "Closing Delay - Min";
CM_ SG_ 2147565312 ClsDlyMax "Closing Delay - Max";
CM_ SG_ 2147565312 ClsDly "Closing Delay";
CM_ SG_ 2147565312 CfgType "Configuration Type";
CM_ SG_ 2147565312 AcSrcId "AC Source Identifier";
CM_ BO_ 2147564800 "AGS Configuration - Battery SOC";
CM_ SG_ 2147564800 TimeIntStopMin "Time Interval to Stop - Min";
CM_ SG_ 2147564800 TimeIntStopMax "Time Interval to Stop - Max";
CM_ SG_ 2147564800 TimeIntStartMin "Time Interval to Start - Min";
CM_ SG_ 2147564800 TimeIntStartMax "Time Interval to Start - Max";
CM_ SG_ 2147564800 TimeInt "Time Interval to Start/Stop";
CM_ SG_ 2147564800 StartStop "Start or Stop";
CM_ SG_ 2147564800 SocLvlStopMin "State of Charge Level to Stop - Min";
CM_ SG_ 2147564800 SocLvlStopMax "State of Charge Level to Stop - Max";
CM_ SG_ 2147564800 SocLvlStartMin "State of Charge Level to Start - Min";
CM_ SG_ 2147564800 SocLvlStartMax "State of Charge Level to Start - Max";
CM_ SG_ 2147564800 SocLvl "State of Charge Level to Start/Stop";
CM_ SG_ 2147564800 RsvByte "Reserved Byte";
CM_ SG_ 2147564800 RsvBits "Reserved Bits";
CM_ SG_ 2147564800 PerEnd "Period End";
CM_ SG_ 2147564800 PerBeg "Period Begin";
CM_ SG_ 2147564800 MsgCount "Message Count";
CM_ SG_ 2147564800 DcSrcId "DC Source Identifier";
CM_ SG_ 2147564800 ConcurAccCtr "Concurrent Access Counter";
CM_ SG_ 2147564800 CfgType "Configuration Type";
CM_ BO_ 2147571456 "AGS Configuration - AC Power";
CM_ SG_ 2147571456 TimeIntStopMin "Time Interval to Stop - Min";
CM_ SG_ 2147571456 TimeIntStopMax "Time Interval to Stop - Max";
CM_ SG_ 2147571456 TimeIntStartMin "Time Interval to Start - Min";
CM_ SG_ 2147571456 TimeIntStartMax "Time Interval to Start - Max";
CM_ SG_ 2147571456 TimeInt "Time Interval to Start/Stop";
CM_ SG_ 2147571456 StartStop "Start or Stop";
CM_ SG_ 2147571456 RsvByte "Reserved Byte";
CM_ SG_ 2147571456 RsvBits "Reserved bits";
CM_ SG_ 2147571456 PerEnd "Period End";
CM_ SG_ 2147571456 PerBeg "Period Begin";
CM_ SG_ 2147571456 MsgCount "Message Count";
CM_ SG_ 2147571456 ConcurAccCtr "Concurrent Access Counter";
CM_ SG_ 2147571456 CfgType "Configuration Type";
CM_ SG_ 2147571456 AcSrcId "AC Source Identifier";
CM_ SG_ 2147571456 AcPwrLvlStopMin "AC Power Level to Stop - Min";
CM_ SG_ 2147571456 AcPwrLvlStopMax "AC Power Level to Stop - Max";
CM_ SG_ 2147571456 AcPwrLvlStartMin "AC Power Level to Start - Min";
CM_ SG_ 2147571456 AcPwrLvlStartMax "AC Power Level to Start - Max";
CM_ SG_ 2147571456 AcPwrLvl "AC Power Level to Start/Stop";
CM_ BO_ 2147565056 "AGS Configuration - AC Current";
CM_ SG_ 2147565056 TimeIntStopMin "Time Interval to Stop - Min";
CM_ SG_ 2147565056 TimeIntStopMax "Time Interval to Stop - Max";
CM_ SG_ 2147565056 TimeIntStartMin "Time Interval to Start - Min";
CM_ SG_ 2147565056 TimeIntStartMax "Time Interval to Start - Max";
CM_ SG_ 2147565056 TimeInt "Time Interval to Start/Stop";
CM_ SG_ 2147565056 StartStop "Start or Stop";
CM_ SG_ 2147565056 RsvByte "Reserved Byte";
CM_ SG_ 2147565056 RsvBits "Reserved bits";
CM_ SG_ 2147565056 PerEnd "Period End";
CM_ SG_ 2147565056 PerBeg "Period Begin";
CM_ SG_ 2147565056 MsgCount "Message Count";
CM_ SG_ 2147565056 ConcurAccCtr "Concurrent Access Counter";
CM_ SG_ 2147565056 CfgType "Configuration Type";
CM_ SG_ 2147565056 AcSrcId "AC Source Identifier";
CM_ SG_ 2147565056 AcILvlStopMin "AC Current Level to Stop - Min";
CM_ SG_ 2147565056 AcILvlStopMax "AC Current Level to Stop - Max";
CM_ SG_ 2147565056 AcILvlStartMin "AC Current Level to Start - Min";
CM_ SG_ 2147565056 AcILvlStartMax "AC Current Level to Start - Max";
CM_ SG_ 2147565056 AcILvl "AC Current Level to Start/Stop";
CM_ BO_ 2147559936 "AGS Configuration";
CM_ SG_ 2147559936 RsvBits2 "Reserved Bits 2";
CM_ SG_ 2147559936 RsvBits1 "Reserved Bits 1";
CM_ SG_ 2147559936 QtEnDis "Quiet Time Enable/Disable";
CM_ SG_ 2147559936 QtEnd "Quiet Time End";
CM_ SG_ 2147559936 QtBeg "Quiet Time Begin";
CM_ SG_ 2147559936 MsgCount "Message Count";
CM_ SG_ 2147559936 MaxAutoCycNoUserMin "Maximum Automatic Cycles with No User Intervention - Minimum";
CM_ SG_ 2147559936 MaxAutoCycNoUserMax "Maximum Automatic Cycles with No User Intervention - Maximum";
CM_ SG_ 2147559936 MaxAutoCycNoUser "Maximum Automatic Cycles with No User Intervention";
CM_ SG_ 2147559936 FloatAutoStopEnDis "Float Auto Stop Enable/Disable";
CM_ SG_ 2147559936 DcVAutoStopEnDis "DC Voltage Auto Stop Enable/Disable";
CM_ SG_ 2147559936 DcVAutoStartEnDis "DC Voltage Auto Start Enable/Disable";
CM_ SG_ 2147559936 DcIAutoStopEnDis "DC Current Auto Stop Enable/Disable";
CM_ SG_ 2147559936 DcIAutoStartEnDis "DC Current Auto Start Enable/Disable";
CM_ SG_ 2147559936 ConcurAccCtr "Concurrent Access Counter";
CM_ SG_ 2147559936 CntctInst "Contact Instance";
CM_ SG_ 2147559936 CntctClsAutoEnDis "Contact Closure Auto Enable/Disable";
CM_ SG_ 2147559936 CfgType "Configuration Type";
CM_ SG_ 2147559936 BattSocAutoStopEnDis "Battery SOC Auto Stop Enable/Disable";
CM_ SG_ 2147559936 BattSocAutoStartEnDis "Battery SOC Auto Start Enable/Disable";
CM_ SG_ 2147559936 AcSrcId "AC Source Identifier";
CM_ SG_ 2147559936 AcPwrAutoStopEnDis "AC Power Auto Stop Enable/Disable";
CM_ SG_ 2147559936 AcPwrAutoStartEnDis "AC Power Auto Start Enable/Disable";
CM_ SG_ 2147559936 AcIAutoStopEnDis "AC Current Auto Stop Enable/Disable";
CM_ SG_ 2147559936 AcIAutoStartEnDis "AC Current Auto Start Enable/Disable";
CM_ SG_ 2147559936 AbsorpAutoStopEnDis "Absorption Auto Stop Enable/Disable";
CM_ BO_ 2147610815 "AC Transfer Switch Status";
CM_ SG_ 2147610815 XferSwMode "Transfer Switch Mode";
CM_ SG_ 2147610815 RsvBits "Reserved Bits";
CM_ SG_ 2147610815 OpState "Operating State";
CM_ SG_ 2147610815 MsgCount "Message Count";
CM_ BO_ 2147599360 "AC Transfer Switch Configuration";
CM_ SG_ 2147599360 XferSwMode "Transfer Switch Mode";
CM_ SG_ 2147599360 XferSwDelay "Transfer Switch Delay";
CM_ SG_ 2147599360 MsgCount "Message Count";
CM_ SG_ 2147599360 ConcurAccCtr "Concurrent Access Counter";
CM_ SG_ 2147599360 CfgType "Configuration Type";
CM_ SG_ 2147599360 AcSrcId "AC Source Identifier";
CM_ BO_ 2147612869 "Active Warning Status (Deux)";
CM_ SG_ 2147612869 WarnType "Warning Type";
CM_ SG_ 2147612869 WarnTime "Warning Time";
CM_ SG_ 2147612869 WarnId "Warning Identifier";
CM_ SG_ 2147612869 StringId "String Identifier";
CM_ SG_ 2147612869 RsvBits "Reserved Bits";
CM_ SG_ 2147612869 MsgCount "Message Count";
CM_ BO_ 2147612685 "Active Warning Status";
CM_ SG_ 2147612685 WarnType "Warning Type";
CM_ SG_ 2147612685 WarnTime "Warning Time";
CM_ SG_ 2147612685 WarnId "Warning Identifier";
CM_ SG_ 2147612685 RsvBits "Reserved Bits";
CM_ SG_ 2147612685 MsgCount "Message Count";
CM_ BO_ 2147612870 "Active Fault Status (Deux)";
CM_ SG_ 2147612870 StringId "String Identifier";
CM_ SG_ 2147612870 RsvBits "Reserved Bits";
CM_ SG_ 2147612870 MsgCount "Message Count";
CM_ SG_ 2147612870 FaultType "Fault Type";
CM_ SG_ 2147612870 FaultTime "Fault Time";
CM_ SG_ 2147612870 FaultId "Fault Identifier";
CM_ BO_ 2147612683 "Active Fault Status";
CM_ SG_ 2147612683 RsvBits "Reserved Bits";
CM_ SG_ 2147612683 MsgCount "Message Count";
CM_ SG_ 2147612683 FaultType "Fault Type";
CM_ SG_ 2147612683 FaultTime "Fault Time";
CM_ SG_ 2147612683 FaultId "Fault Identifier";
CM_ BO_ 2147610646 "AC Status - RMS";
CM_ SG_ 2147610646 Voltage "Voltage";
CM_ SG_ 2147610646 TotalFlag "Total Flag";
CM_ SG_ 2147610646 RsvBits2 "Reserved Bits";
CM_ SG_ 2147610646 RsvBits1 "Reserved Bits";
CM_ SG_ 2147610646 RealPwrPer "Real Power Percent of Maximum";
CM_ SG_ 2147610646 RealPwr "Real Power";
CM_ SG_ 2147610646 Quality "Quality";
CM_ SG_ 2147610646 PowerFactor "Power Factor";
CM_ SG_ 2147610646 MsgCount "Message Count";
CM_ SG_ 2147610646 Line "Line";
CM_ SG_ 2147610646 Freq "Frequency";
CM_ SG_ 2147610646 CurrentPer "Current Percent of Maximum";
CM_ SG_ 2147610646 Current "Current";
CM_ SG_ 2147610646 BreakerSz "Breaker Size";
CM_ SG_ 2147610646 ApparentPwr "Apparent Power";
CM_ SG_ 2147610646 AcSrcId "AC Source Identifer";
CM_ BO_ 2147610630 "AC Output Status - RMS";
CM_ SG_ 2147610630 Waveform "Waveform";
CM_ SG_ 2147610630 Voltage "Voltage";
CM_ SG_ 2147610630 TotalFlag "Total Flag";
CM_ SG_ 2147610630 RsvBits2 "Reserved Bits 2";
CM_ SG_ 2147610630 RsvBits1 "Reserved Bits 1";
CM_ SG_ 2147610630 RealPwrPer "Real Power Percent of Maximum";
CM_ SG_ 2147610630 RealPwr "Real Power";
CM_ SG_ 2147610630 MsgCount "Message Count";
CM_ SG_ 2147610630 Line "Line";
CM_ SG_ 2147610630 Freq "Frequency";
CM_ SG_ 2147610630 CurrentPer "Current Percent of Maximum";
CM_ SG_ 2147610630 Current "Current";
CM_ SG_ 2147610630 BreakerSz "Breaker Size";
CM_ SG_ 2147610630 ApparentPwr "Apparent Power";
CM_ SG_ 2147610630 AcSrcId "AC Source Identifer";
CM_ BO_ 2147610631 "AC Output Status - Peak";
CM_ SG_ 2147610631 Waveform "Waveform";
CM_ SG_ 2147610631 Voltage "Voltage";
CM_ SG_ 2147610631 TotalFlag "Total Flag";
CM_ SG_ 2147610631 RsvBits2 "Reserved Bits 2";
CM_ SG_ 2147610631 RsvBits1 "Reserved Bits 1";
CM_ SG_ 2147610631 RealPwrPer "Real Power Percent of Maximum";
CM_ SG_ 2147610631 RealPwr "Real Power";
CM_ SG_ 2147610631 MsgCount "Message Count";
CM_ SG_ 2147610631 Line "Line";
CM_ SG_ 2147610631 Freq "Frequency";
CM_ SG_ 2147610631 CurrentPer "Current Percent of Maximu";
CM_ SG_ 2147610631 Current "Current";
CM_ SG_ 2147610631 BreakerSz "Breaker Size";
CM_ SG_ 2147610631 ApparentPwr "Apparent Power";
CM_ SG_ 2147610631 AcSrcId "AC Source Identifer";
CM_ BO_ 2147610632 "AC Output Status - Average";
CM_ SG_ 2147610632 Waveform "Waveform";
CM_ SG_ 2147610632 Voltage "Voltage";
CM_ SG_ 2147610632 TotalFlag "Total Flag";
CM_ SG_ 2147610632 RsvBits2 "Reserved Bits 2";
CM_ SG_ 2147610632 RsvBits1 "Reserved Bits 1";
CM_ SG_ 2147610632 RealPwrPer "Real Power Percent of Maximum";
CM_ SG_ 2147610632 RealPwr "Real Power";
CM_ SG_ 2147610632 MsgCount "Message Count";
CM_ SG_ 2147610632 Line "Line";
CM_ SG_ 2147610632 Freq "Frequency";
CM_ SG_ 2147610632 CurrentPer "Current Percent of Maximu";
CM_ SG_ 2147610632 Current "Current";
CM_ SG_ 2147610632 BreakerSz "Breaker Size";
CM_ SG_ 2147610632 ApparentPwr "Apparent Power";
CM_ SG_ 2147610632 AcSrcId "AC Source Identifer";
CM_ BO_ 2147570176 "AC Output Configuration - Under Voltage - RMS";
CM_ SG_ 2147570176 UvLvlMin "Under Voltage Level - Minimum";
CM_ SG_ 2147570176 UvLvlMax "Under Voltage Level - Maximum";
CM_ SG_ 2147570176 UvLvl "Under Voltage Level";
CM_ SG_ 2147570176 UvIntvlMin "Under Voltage Interval - Minimum";
CM_ SG_ 2147570176 UvIntvlMax "Under Voltage Interval - Maximum";
CM_ SG_ 2147570176 UvIntvl "Under Voltage Interval";
CM_ SG_ 2147570176 RefEvtId "Reference Event Identifier";
CM_ SG_ 2147570176 MsgCount "Message Count";
CM_ SG_ 2147570176 EvtId "Event Identifier";
CM_ SG_ 2147570176 ConcurAccCtr "Concurrent Access Counter";
CM_ SG_ 2147570176 CfgType "Configuration Type";
CM_ SG_ 2147570176 AcSrcId "AC Source Identifer";
BA_DEF_ BO_  "J1939PGPrio" INT 0 7;
BA_DEF_ BO_  "J1939PGR1" INT 0 1;
BA_DEF_ BO_  "J1939PGDest" INT 0 255;
BA_DEF_ BO_  "J1939PGSrc" INT 0 255;
BA_DEF_ BO_  "CycleTime" INT 5 1000;
BA_DEF_ BO_  "SingleFrame" INT 0 1;
BA_DEF_DEF_  "J1939PGPrio" 0;
BA_DEF_DEF_  "J1939PGR1" 0;
BA_DEF_DEF_  "J1939PGDest" 0;
BA_DEF_DEF_  "J1939PGSrc" 0;
BA_DEF_DEF_  "CycleTime" 100;
BA_DEF_DEF_  "SingleFrame" 0;
BA_ "J1939PGPrio" BO_ 2147560448 6;
BA_ "J1939PGDest" BO_ 2147560448 255;
BA_ "J1939PGPrio" BO_ 2147567360 6;
BA_ "J1939PGDest" BO_ 2147567360 255;
BA_ "SingleFrame" BO_ 2147567360 1;
BA_ "J1939PGPrio" BO_ 2147610662 6;
BA_ "J1939PGDest" BO_ 2147610662 255;
BA_ "SingleFrame" BO_ 2147610662 1;
BA_ "J1939PGPrio" BO_ 2147556864 6;
BA_ "J1939PGDest" BO_ 2147556864 255;
BA_ "SingleFrame" BO_ 2147556864 1;
BA_ "J1939PGPrio" BO_ 2147610665 6;
BA_ "J1939PGDest" BO_ 2147610665 255;
BA_ "CycleTime" BO_ 2147610665 500;
BA_ "J1939PGPrio" BO_ 2147574528 6;
BA_ "J1939PGDest" BO_ 2147574528 255;
BA_ "J1939PGPrio" BO_ 2147610820 6;
BA_ "J1939PGDest" BO_ 2147610820 255;
BA_ "CycleTime" BO_ 2147610820 500;
BA_ "J1939PGPrio" BO_ 2147610651 6;
BA_ "J1939PGDest" BO_ 2147610651 255;
BA_ "CycleTime" BO_ 2147610651 500;
BA_ "J1939PGPrio" BO_ 2147610645 6;
BA_ "J1939PGDest" BO_ 2147610645 255;
BA_ "SingleFrame" BO_ 2147610645 1;
BA_ "J1939PGPrio" BO_ 2147610829 6;
BA_ "J1939PGDest" BO_ 2147610829 255;
BA_ "CycleTime" BO_ 2147610829 5;
BA_ "J1939PGPrio" BO_ 2147576064 6;
BA_ "J1939PGDest" BO_ 2147576064 255;
BA_ "CycleTime" BO_ 2147576064 5;
BA_ "SingleFrame" BO_ 2147576064 1;
BA_ "J1939PGPrio" BO_ 2147574784 6;
BA_ "J1939PGDest" BO_ 2147574784 255;
BA_ "J1939PGPrio" BO_ 2147559680 6;
BA_ "J1939PGDest" BO_ 2147559680 255;
BA_ "J1939PGPrio" BO_ 2147563008 6;
BA_ "J1939PGDest" BO_ 2147563008 255;
BA_ "SingleFrame" BO_ 2147563008 1;
BA_ "J1939PGPrio" BO_ 2147558656 6;
BA_ "J1939PGDest" BO_ 2147558656 255;
BA_ "SingleFrame" BO_ 2147558656 1;
BA_ "J1939PGPrio" BO_ 2147610633 6;
BA_ "J1939PGDest" BO_ 2147610633 255;
BA_ "J1939PGPrio" BO_ 2147552512 6;
BA_ "J1939PGDest" BO_ 2147552512 255;
BA_ "J1939PGPrio" BO_ 2147552768 6;
BA_ "J1939PGDest" BO_ 2147552768 255;
BA_ "J1939PGPrio" BO_ 2147610647 6;
BA_ "J1939PGDest" BO_ 2147610647 255;
BA_ "J1939PGPrio" BO_ 2147610641 6;
BA_ "J1939PGDest" BO_ 2147610641 255;
BA_ "CycleTime" BO_ 2147610641 500;
BA_ "J1939PGPrio" BO_ 2147610648 6;
BA_ "J1939PGDest" BO_ 2147610648 255;
BA_ "J1939PGPrio" BO_ 2147557120 6;
BA_ "J1939PGDest" BO_ 2147557120 255;
BA_ "SingleFrame" BO_ 2147557120 1;
BA_ "J1939PGPrio" BO_ 2147560192 6;
BA_ "J1939PGDest" BO_ 2147560192 255;
BA_ "J1939PGPrio" BO_ 2147564544 6;
BA_ "J1939PGDest" BO_ 2147564544 255;
BA_ "J1939PGPrio" BO_ 2147571200 6;
BA_ "J1939PGDest" BO_ 2147571200 255;
BA_ "J1939PGPrio" BO_ 2147565312 6;
BA_ "J1939PGDest" BO_ 2147565312 255;
BA_ "J1939PGPrio" BO_ 2147564800 6;
BA_ "J1939PGDest" BO_ 2147564800 255;
BA_ "J1939PGPrio" BO_ 2147571456 6;
BA_ "J1939PGDest" BO_ 2147571456 255;
BA_ "J1939PGPrio" BO_ 2147565056 6;
BA_ "J1939PGDest" BO_ 2147565056 255;
BA_ "J1939PGPrio" BO_ 2147559936 6;
BA_ "J1939PGDest" BO_ 2147559936 255;
BA_ "J1939PGPrio" BO_ 2147610815 6;
BA_ "J1939PGDest" BO_ 2147610815 255;
BA_ "CycleTime" BO_ 2147610815 500;
BA_ "SingleFrame" BO_ 2147610815 1;
BA_ "J1939PGPrio" BO_ 2147599360 6;
BA_ "J1939PGDest" BO_ 2147599360 255;
BA_ "J1939PGPrio" BO_ 2147612869 6;
BA_ "J1939PGDest" BO_ 2147612869 255;
BA_ "J1939PGPrio" BO_ 2147612685 6;
BA_ "J1939PGDest" BO_ 2147612685 255;
BA_ "J1939PGPrio" BO_ 2147612870 6;
BA_ "J1939PGDest" BO_ 2147612870 255;
BA_ "J1939PGPrio" BO_ 2147612683 6;
BA_ "J1939PGDest" BO_ 2147612683 255;
BA_ "J1939PGPrio" BO_ 2147610646 6;
BA_ "J1939PGDest" BO_ 2147610646 255;
BA_ "CycleTime" BO_ 2147610646 500;
BA_ "J1939PGPrio" BO_ 2147610630 6;
BA_ "J1939PGDest" BO_ 2147610630 255;
BA_ "CycleTime" BO_ 2147610630 500;
BA_ "J1939PGPrio" BO_ 2147610631 6;
BA_ "J1939PGDest" BO_ 2147610631 255;
BA_ "CycleTime" BO_ 2147610631 500;
BA_ "J1939PGPrio" BO_ 2147610632 6;
BA_ "J1939PGDest" BO_ 2147610632 255;
BA_ "CycleTime" BO_ 2147610632 500;
BA_ "J1939PGPrio" BO_ 2147570176 6;
BA_ "J1939PGDest" BO_ 2147570176 255;
VAL_ 2147560448 OverChgEnDis 0 "Off" 1 "On" 2 "Reserved" 3 "No Change" ;
VAL_ 2147560448 EqlzOneTimeEnDis 0 "Off" 1 "On" 2 "Reserved" 3 "No Change" ;
VAL_ 2147560448 DcSrcId 0 "Invalid" 1 "None" 2 "Anonymous" 3 "HouseBatBank1" 4 "HouseBatBank2" 5 "HouseBatBank3" 6 "HouseBatBank4" 7 "HouseBatBank5" 8 "HouseBatBank6" 9 "StartBatBank1" 10 "StartBatBank2" 11 "StartBatBank3" 12 "StartBatBank4" 13 "StartBatBank5" 14 "StartBatBank6" 21 "SolarArray1" 22 "SolarArray2" 23 "SolarArray3" 24 "SolarArray4" 25 "SolarArray5" 26 "SolarArray6" 27 "SolarArray7" 28 "SolarArray8" 29 "SolarArray9" 30 "SolarArray10" 31 "SolarArray11" 32 "SolarArray12" 33 "SolarArray13" 34 "SolarArray14" 35 "SolarArray15" 36 "SolarArray16" 252 "All" 253 "Reserved" 254 "Out of Range" 255 "Data Not Available Do Not Change" ;
VAL_ 2147560448 ChgOverrideEnDis 0 "Off" 1 "On" 2 "Reserved" 3 "No Change" ;
VAL_ 2147560448 ChgMode 0 "Standalone" 1 "Primary" 2 "Secondary" 3 "Echo" 253 "Reserved" 254 "Out of Range" 255 "Data Not Available Do Not Change" ;
VAL_ 2147560448 ChgAlgorithm 0 "Invalid" 1 "3Stage" 2 "2StageNoFloat" 3 "CVCC" 4 "Trickle" 253 "Reserved" 254 "Out of Range" 255 "Data Not Available Do Not Change" 5 "4Stage" ;
VAL_ 2147560448 CfgType 0 "User" 1 "OEM" 2 "Factory" 3 "Reserved" ;
VAL_ 2147560448 BattTempNoSensor 0 "Cold" 1 "Warm" 2 "Hot" ;
VAL_ 2147567360 FaultAutoRst 0 "Off" 1 "On" 2 "Reserved" 3 "No Change" ;
VAL_ 2147567360 CfgType 0 "User" 1 "OEM" 2 "Factory" 3 "Reserved" ;
VAL_ 2147610662 CalibDataId 0 "Invalid" 1 "DC Input Power" 2 "DC Output Power" ;
VAL_ 2147556864 CalibEnDis 0 "Off" 1 "On" 2 "Reserved" 3 "No Change" ;
VAL_ 2147610665 DcSrcId 0 "Invalid" 1 "None" 2 "Anonymous" 3 "HouseBatBank1" 4 "HouseBatBank2" 5 "HouseBatBank3" 6 "HouseBatBank4" 7 "HouseBatBank5" 8 "HouseBatBank6" 9 "StartBatBank1" 10 "StartBatBank2" 11 "StartBatBank3" 12 "StartBatBank4" 13 "StartBatBank5" 14 "StartBatBank6" 21 "SolarArray1" 22 "SolarArray2" 23 "SolarArray3" 24 "SolarArray4" 25 "SolarArray5" 26 "SolarArray6" 27 "SolarArray7" 28 "SolarArray8" 29 "SolarArray9" 30 "SolarArray10" 31 "SolarArray11" 32 "SolarArray12" 33 "SolarArray13" 34 "SolarArray14" 35 "SolarArray15" 36 "SolarArray16" 252 "All" 253 "Reserved" 254 "Out of Range" 255 "Data Not Available Do Not Change" ;
VAL_ 2147574528 DcSrcId 0 "Invalid" 1 "None" 2 "Anonymous" 3 "HouseBatBank1" 4 "HouseBatBank2" 5 "HouseBatBank3" 6 "HouseBatBank4" 7 "HouseBatBank5" 8 "HouseBatBank6" 9 "StartBatBank1" 10 "StartBatBank2" 11 "StartBatBank3" 12 "StartBatBank4" 13 "StartBatBank5" 14 "StartBatBank6" 21 "SolarArray1" 22 "SolarArray2" 23 "SolarArray3" 24 "SolarArray4" 25 "SolarArray5" 26 "SolarArray6" 27 "SolarArray7" 28 "SolarArray8" 29 "SolarArray9" 30 "SolarArray10" 31 "SolarArray11" 32 "SolarArray12" 33 "SolarArray13" 34 "SolarArray14" 35 "SolarArray15" 36 "SolarArray16" 252 "All" 253 "Reserved" 254 "Out of Range" 255 "Data Not Available Do Not Change" ;
VAL_ 2147574528 CfgType 0 "User" 1 "OEM" 2 "Factory" 3 "Reserved" ;
VAL_ 2147574528 BattType 0 "Flooded" 1 "Gel" 2 "AGM" 3 "Custom" 4 "Deep Cycle" 5 "Optima" 253 "Reserved" 254 "Out Of Range" 255 "Data Not Available Do Not Change" 6 "Lithium Ion" ;
VAL_ 2147610820 TempSensId 0 "Battery 1" 1 "Battery 2" 2 "Battery 3" 3 "Battery 4" 4 "Battery 5" 5 "Battery 6" 10 "Ambient 1" 11 "Ambient 2" 12 "Ambient 3" 13 "Ambient 4" 14 "Shunt 1" 15 "Shunt 2" 16 "Shunt 3" 17 "Shunt 4" 253 "Reserved" 254 "Out of Range" 255 "Data Not Available Do Not Change" ;
VAL_ 2147610820 DcSrcId 0 "Invalid" 1 "None" 2 "Anonymous" 3 "HouseBatBank1" 4 "HouseBatBank2" 5 "HouseBatBank3" 6 "HouseBatBank4" 7 "HouseBatBank5" 8 "HouseBatBank6" 9 "StartBatBank1" 10 "StartBatBank2" 11 "StartBatBank3" 12 "StartBatBank4" 13 "StartBatBank5" 14 "StartBatBank6" 21 "SolarArray1" 22 "SolarArray2" 23 "SolarArray3" 24 "SolarArray4" 25 "SolarArray5" 26 "SolarArray6" 27 "SolarArray7" 28 "SolarArray8" 29 "SolarArray9" 30 "SolarArray10" 31 "SolarArray11" 32 "SolarArray12" 33 "SolarArray13" 34 "SolarArray14" 35 "SolarArray15" 36 "SolarArray16" 252 "All" 253 "Reserved" 254 "Out of Range" 255 "Data Not Available Do Not Change" ;
VAL_ 2147610820 BattType 0 "Flooded" 1 "Gel" 2 "AGM" 3 "Custom" 4 "Deep Cycle" 5 "Optima" 253 "Reserved" 254 "Out Of Range" 255 "Data Not Available Do Not Change" 6 "Lithium Ion" ;
VAL_ 2147610651 DcSrcId 0 "Invalid" 1 "None" 2 "Anonymous" 3 "HouseBatBank1" 4 "HouseBatBank2" 5 "HouseBatBank3" 6 "HouseBatBank4" 7 "HouseBatBank5" 8 "HouseBatBank6" 9 "StartBatBank1" 10 "StartBatBank2" 11 "StartBatBank3" 12 "StartBatBank4" 13 "StartBatBank5" 14 "StartBatBank6" 21 "SolarArray1" 22 "SolarArray2" 23 "SolarArray3" 24 "SolarArray4" 25 "SolarArray5" 26 "SolarArray6" 27 "SolarArray7" 28 "SolarArray8" 29 "SolarArray9" 30 "SolarArray10" 31 "SolarArray11" 32 "SolarArray12" 33 "SolarArray13" 34 "SolarArray14" 35 "SolarArray15" 36 "SolarArray16" 252 "All" 253 "Reserved" 254 "Out of Range" 255 "Data Not Available Do Not Change" ;
VAL_ 2147610651 BtsPresent 0 "Off" 1 "On" 2 "Error" 3 "Unknown" ;
VAL_ 2147610645 PreviousPeriod 0 "Life" 1 "Year" 2 "Month" 3 "Week" 4 "Day" 5 "Hour" 6 "User" ;
VAL_ 2147610645 DcSrcId 0 "Invalid" 1 "None" 2 "Anonymous" 3 "HouseBatBank1" 4 "HouseBatBank2" 5 "HouseBatBank3" 6 "HouseBatBank4" 7 "HouseBatBank5" 8 "HouseBatBank6" 9 "StartBatBank1" 10 "StartBatBank2" 11 "StartBatBank3" 12 "StartBatBank4" 13 "StartBatBank5" 14 "StartBatBank6" 21 "SolarArray1" 22 "SolarArray2" 23 "SolarArray3" 24 "SolarArray4" 25 "SolarArray5" 26 "SolarArray6" 27 "SolarArray7" 28 "SolarArray8" 29 "SolarArray9" 30 "SolarArray10" 31 "SolarArray11" 32 "SolarArray12" 33 "SolarArray13" 34 "SolarArray14" 35 "SolarArray15" 36 "SolarArray16" 252 "All" 253 "Reserved" 254 "Out of Range" 255 "Data Not Available Do Not Change" ;
VAL_ 2147610829 DcSrcId 0 "Invalid" 1 "None" 2 "Anonymous" 3 "HouseBatBank1" 4 "HouseBatBank2" 5 "HouseBatBank3" 6 "HouseBatBank4" 7 "HouseBatBank5" 8 "HouseBatBank6" 9 "StartBatBank1" 10 "StartBatBank2" 11 "StartBatBank3" 12 "StartBatBank4" 13 "StartBatBank5" 14 "StartBatBank6" 21 "SolarArray1" 22 "SolarArray2" 23 "SolarArray3" 24 "SolarArray4" 25 "SolarArray5" 26 "SolarArray6" 27 "SolarArray7" 28 "SolarArray8" 29 "SolarArray9" 30 "SolarArray10" 31 "SolarArray11" 32 "SolarArray12" 33 "SolarArray13" 34 "SolarArray14" 35 "SolarArray15" 36 "SolarArray16" 252 "All" 253 "Reserved" 254 "Out of Range" 255 "Data Not Available Do Not Change" ;
VAL_ 2147576064 SyncEnDis 0 "Off" 1 "On" 2 "Reserved" 3 "No Change" ;
VAL_ 2147576064 DcSrcId 0 "Invalid" 1 "None" 2 "Anonymous" 3 "HouseBatBank1" 4 "HouseBatBank2" 5 "HouseBatBank3" 6 "HouseBatBank4" 7 "HouseBatBank5" 8 "HouseBatBank6" 9 "StartBatBank1" 10 "StartBatBank2" 11 "StartBatBank3" 12 "StartBatBank4" 13 "StartBatBank5" 14 "StartBatBank6" 21 "SolarArray1" 22 "SolarArray2" 23 "SolarArray3" 24 "SolarArray4" 25 "SolarArray5" 26 "SolarArray6" 27 "SolarArray7" 28 "SolarArray8" 29 "SolarArray9" 30 "SolarArray10" 31 "SolarArray11" 32 "SolarArray12" 33 "SolarArray13" 34 "SolarArray14" 35 "SolarArray15" 36 "SolarArray16" 252 "All" 253 "Reserved" 254 "Out of Range" 255 "Data Not Available Do Not Change" ;
VAL_ 2147574784 DcSrcId 0 "Invalid" 1 "None" 2 "Anonymous" 3 "HouseBatBank1" 4 "HouseBatBank2" 5 "HouseBatBank3" 6 "HouseBatBank4" 7 "HouseBatBank5" 8 "HouseBatBank6" 9 "StartBatBank1" 10 "StartBatBank2" 11 "StartBatBank3" 12 "StartBatBank4" 13 "StartBatBank5" 14 "StartBatBank6" 21 "SolarArray1" 22 "SolarArray2" 23 "SolarArray3" 24 "SolarArray4" 25 "SolarArray5" 26 "SolarArray6" 27 "SolarArray7" 28 "SolarArray8" 29 "SolarArray9" 30 "SolarArray10" 31 "SolarArray11" 32 "SolarArray12" 33 "SolarArray13" 34 "SolarArray14" 35 "SolarArray15" 36 "SolarArray16" 252 "All" 253 "Reserved" 254 "Out of Range" 255 "Data Not Available Do Not Change" ;
VAL_ 2147574784 CfgType 0 "User" 1 "OEM" 2 "Factory" 3 "Reserved" ;
VAL_ 2147574784 AutoSyncTime 0 "5" 1 "10" 2 "15" 3 "30" 4 "45" 5 "60" 6 "90" 7 "120" 8 "150" 9 "180" 10 "240" 11 "300" ;
VAL_ 2147559680 TimeRemAvgFilter 0 "Fastest" 1 "Faster" 2 "Fast" 3 "Reserved" ;
VAL_ 2147559680 TempUnit 0 "Imperial" 1 "Standard" 2 "Metric" 253 "Reserved" 254 "Out Of Range" 255 "Data Not Available Do Not Change" ;
VAL_ 2147559680 ShuntVoltRating 0 "50" 1 "60" ;
VAL_ 2147559680 ShuntAmpRating 0 "10" 1 "11" 2 "12" 3 "13" 4 "14" 5 "15" 6 "16" 7 "17" 8 "18" 9 "19" 10 "20" 11 "21" 12 "22" 13 "23" 14 "24" 15 "25" 16 "30" 17 "35" 18 "40" 19 "45" 20 "50" 21 "55" 22 "60" 23 "65" 24 "70" 25 "75" 26 "80" 27 "85" 28 "90" 29 "95" 30 "100" 31 "110" 32 "120" 33 "130" 34 "140" 35 "150" 36 "160" 37 "170" 38 "180" 39 "190" 40 "200" 41 "210" 42 "220" 43 "230" 44 "240" 45 "250" 46 "300" 47 "350" 48 "400" 49 "450" 50 "500" 51 "550" 52 "600" 53 "650" 54 "700" 55 "750" 56 "800" 57 "850" 58 "900" 59 "950" 60 "1000" 61 "1100" 62 "1200" 63 "1300" 64 "1400" 65 "1500" 66 "1600" 67 "1700" 68 "1800" 69 "1900" 70 "2000" 71 "2100" 72 "2200" 73 "2300" 74 "2400" 75 "2500" 76 "3000" 77 "3500" 78 "4000" 79 "4500" 80 "5000" 81 "5500" 82 "6000" 83 "6500" 84 "7000" 85 "7500" 86 "8000" 87 "8500" 88 "9000" ;
VAL_ 2147559680 SetupLock 0 "Off" 1 "On" 2 "Reserved" 3 "No Change" ;
VAL_ 2147559680 NomV 0 "12V" 1 "24V" 2 "48V" 3 "Reserved" ;
VAL_ 2147559680 DcSrcId 0 "Invalid" 1 "None" 2 "Anonymous" 3 "HouseBatBank1" 4 "HouseBatBank2" 5 "HouseBatBank3" 6 "HouseBatBank4" 7 "HouseBatBank5" 8 "HouseBatBank6" 9 "StartBatBank1" 10 "StartBatBank2" 11 "StartBatBank3" 12 "StartBatBank4" 13 "StartBatBank5" 14 "StartBatBank6" 21 "SolarArray1" 22 "SolarArray2" 23 "SolarArray3" 24 "SolarArray4" 25 "SolarArray5" 26 "SolarArray6" 27 "SolarArray7" 28 "SolarArray8" 29 "SolarArray9" 30 "SolarArray10" 31 "SolarArray11" 32 "SolarArray12" 33 "SolarArray13" 34 "SolarArray14" 35 "SolarArray15" 36 "SolarArray16" 252 "All" 253 "Reserved" 254 "Out of Range" 255 "Data Not Available Do Not Change" ;
VAL_ 2147559680 ChgEfficFactorMode 0 "Manual" 1 "Automatic" 2 "Reserved" 3 "No Change" ;
VAL_ 2147559680 CfgType 0 "User" 1 "OEM" 2 "Factory" 3 "Reserved" ;
VAL_ 2147559680 BacklightDuration 0 "Off" 1 "5" 2 "10" 3 "15" 4 "30" 5 "45" 6 "60" 7 "90" 8 "120" 9 "150" 10 "180" 11 "240" 12 "300" 13 "On" 14 "Automatic" 15 "Reserved" ;
VAL_ 2147563008 AssocType 0 "Invalid" 1 "DCInput" 2 "DCOut" 3 "DCInputOut" 4 "Reserved" 5 "ACInput" 6 "ACOut" 7 "ACInputOut" ;
VAL_ 2147558656 CfgType 0 "User" 1 "OEM" 2 "Factory" 3 "Reserved" ;
VAL_ 2147558656 AssocType 0 "Invalid" 1 "DCInput" 2 "DCOut" 3 "DCInputOut" 4 "Reserved" 5 "ACInput" 6 "ACOut" 7 "ACInputOut" ;
VAL_ 2147552512 RefEvtId 436 "SPS Auto Off Array V Low" 437 "SPS Auto On Array V Low" 438 "SPS Auto Off Ground Flt" 439 "SPS Auto On Ground Flt" 440 "SPS Auto Off External Shutdown Flt" 0 "None" 10 "Control Command Hibernate" 11 "Control Command Safe" 12 "Control Command Power Save" 13 "Control Command Operating" 14 "Control Command Diagnostic" 15 "Control Command Last Mode" 20 "Reset Command Reboot" 21 "Reset Command Download" 22 "Reset Command Oem" 23 "Reset Command Factory" 24 "Reset Command Reboot Clear Nv" 25 "Powered Up" 30 "Clear Command Active Faults" 31 "Clear Command Fault Log" 32 "Clear Command Active Warns" 33 "Clear Command Warn Log" 34 "Clear Command State Event Log" 35 "Clear Command Comm Stats" 36 "Clear Command Stats" 37 "Clear Command All" 40 "Date Time Configured" 50 "Warn Cleared" 51 "Fault Cleared" 52 "Fault Set" 60 "User Cfg Changed" 61 "Oem Cfg Changed" 70 "Triggered Fault" 250 "Shutdown Threshold" 251 "Shutdown Hysteresis" 252 "Warning Threshold" 253 "Warning Hysteresis" 254 "Transfer Threshold" 255 "Fan 0 Threshold" 256 "Fan 10 Threshold" 257 "Fan 20 Threshold" 258 "Fan 30 Threshold" 259 "Fan 40 Threshold" 260 "Fan 50 Threshold" 261 "Fan 60 Threshold" 262 "Fan 70 Threshold" 263 "Fan 80 Threshold" 264 "Fan 90 Threshold" 265 "Fan 100 Threshold" 266 "Relay Open Threshold" 267 "Relay Close Threshold" 268 "Charger Derating Ac In V" 269 "Charger Derating Ac In I" 270 "Charger Derating Ext Temp" 271 "Charger Derating Int Temp" 272 "Charger Derating Ripple V" 273 "Lost Ac Threshold" 274 "Lost Ac Hysteresis" 275 "Imm Shutdown Threshold" 276 "Imm Shutdown Hysteresis" 277 "Charger Shutdown Threshold" 278 "Charger Shutdown Hysteresis" 279 "Charger Warning Threshold" 280 "Charger Warning Hysteresis" 281 "Inverter Shutdown Threshold" 282 "Inverter Shutdown Hysteresis" 283 "Inverter Warning Threshold" 284 "Inverter Warning Hysteresis" 285 "Charger Derating Temp Start Point" 286 "Charger Derating Temp End Point" 287 "Charger Recharge Threshold" 300 "Ags Exercise Start" 301 "Ags Exercise Stop" 302 "Ags Quiet Time Begin" 303 "Ags Quiet Time End" 304 "Ags Battery Soc Start" 305 "Ags Battery Soc Stop" 306 "Ags Dc V Start" 307 "Ags Dc V Stop" 308 "Ags Ac I Start" 309 "Ags Ac I Stop" 310 "Ags Contact Start" 311 "Ags Contact Stop" 312 "Ags Float Stop" 313 "Ags Absorp Stop" 314 "Ags Manual On" 315 "Ags Manual Off" 316 "Ags Auto" 317 "Ags External On" 318 "Ags External Off" 319 "Gen External On" 320 "Gen External Off" 321 "Ags External Shutdown" 322 "Ags Auto Off" 323 "Ags Dc I Start" 324 "Ags Dc I Stop" 325 "Ags Ac Power Start" 326 "Ags Ac Power Stop" 400 "Sps Manual Off" 401 "Sps Manual On" 410 "Sps Auto Off" 411 "Sps Auto On" 420 "Sps Auto Off Batt V Low" 421 "Sps Auto On Batt V Low" 422 "Sps Auto Off Batt V High" 423 "Sps Auto On Batt V High" 424 "Sps Auto Off Array V High" 425 "Sps Auto On Array V High" 426 "Sps Auto Off Batt Temp Low" 427 "Sps Auto On Batt Temp Low" 428 "Sps Auto Off Batt Temp High" 429 "Sps Auto On Batt Temp High" 430 "Sps Auto Off Heat Sink Temp High" 431 "Sps Auto On Heat Sink Temp High" 432 "Sps Auto Off Fault" 433 "Sps Auto On Fault" 434 "Aps Check Timeout" 435 "Aps Qualify Timeout" 512 "Resume From Safe" 513 "AC Fault Set" 514 "Invert Fault Set" 515 "Charge Fault Set" 516 "Charger Enable" 517 "Charger Disable" 518 "Inverter Enable" 519 "Inverter Disable" 520 "Charge Suspend On" 521 "Charge Suspend Off" 522 "AC Good" 523 "AC Bad" 524 "Load Sense Enable" 525 "Load Sense Active" 526 "Invert Active" 527 "Bulk Exit" 528 "Absorption Exit" 529 "Float Exit" 530 "Float 3-Stage Set" 531 "Float 2-Stage Set" 532 "Equalize Enable" 533 "Equalize Disable" 534 "Equalize Exit" 535 "Load Sense Disable" 536 "Sell To Grid Enabled" 537 "Sell To Grid Disabled" 538 "Grid Support Enable" 539 "Grid Support Disable" 540 "Gen Support Enable" 541 "Gen Support Disable" 542 "Peak Load Shaving Enable" 543 "Peak Load Shaving Disable" 544 "Peak Load Shaving Tod Start" 545 "Peak Load Shaving Tod Stop" 546 "Unit Off" 547 "System Absorption Exit" 548 "System Inverter Enable" 549 "System AC Good" 550 "Anti Islanding Condition" 551 "Hibernate Timeout" 552 "External Sync Error" 553 "External Suspend Request" 554 "Engaging Charger" 555 "Engaging Gen Support" 556 "Grid Tie Engage Timeout" 557 "Gen Support Engage Timeout" 558 "Charge Engage Timeout" 559 "Inverter Engage Timeout" 560 "Charge Exit Timeout" 561 "Grid Support Entry Amps" 562 "Grid Support Exit Amps" 563 "Gen Support Entry Amps" 564 "Gen Support Exit Amps" 565 "Grid Support Entry Vdc" 566 "Grid Support Exit Vdc" 567 "Low Batt Cut Off Entry Vdc" 568 "Low Batt Recharge Vdc" 569 "Low Batt Cut Off Exit Vdc" 570 "Invert To Bypass Timeout" 571 "Force Charge" 572 "System Engage Bulk Charge" 441 "SPS Auto On External Shutdown Flt" 442 "SPS Auto Off Input Over Volt Flt" 443 "SPS Auto On Input Over Volt Flt" 444 "SPS Auto Off Input Over Volt Err" 445 "SPS Auto On Input Over Volt Err" 446 "SPS Auto Off Input Over Volt Wrn" 447 "SPS Auto On Input Over Volt Wrn" 448 "SPS Auto Off Output Over Volt Err" 449 "SPS Auto On Output Over Volt Err" 450 "SPS Auto Off Output Over Volt Wrn" 451 "SPS Auto On Output Over Volt Wrn" 452 "SPS Auto Off Output Under Volt Err" 453 "SPS Auto On Output Under Volt Err" 454 "SPS Auto Off Output Under Volt Wrn" 455 "SPS Auto On Output Under Volt Wrn" 456 "SPS Auto Off Output Over Curr Err" 457 "SPS Auto On Output Over Curr Err" 458 "SPS Auto Off Batt Over Temp Err" 459 "SPS Auto On Batt Over Temp Err" 460 "SPS Auto Off Batt Over Temp Wrn" 461 "SPS Auto On Batt Over Temp Wrn" 462 "SPS Auto Off Batt Under Temp Wrn" 463 "SPS Auto On Batt Under Temp Wrn" 464 "SPS Auto Off Heatsink Over Temp Err" 465 "SPS Auto On Heatsink Over Temp Err" 466 "SPS Auto Off Heatsink Over Temp Wrn" 467 "SPS Auto On Heatsink Over Temp Wrn" 468 "SPS Auto Off Ambient Over Temp Err" 469 "SPS Auto On Ambient Over Temp Err" 470 "SPS Auto Off Ambient Over Temp Wrn" 471 "SPS Auto On Ambient Over Temp Wrn" 472 "SPS Auto Off Capacitor Over Temp Err" 473 "SPS Auto On Capacitor Over Temp Err" 474 "SPS Auto Off Fan Flt" 475 "SPS Auto On Fan Flt" 476 "SPS Auto Off Fan Err" 477 "SPS Auto On Fan Err" 478 "SPS Auto Off Input Over Curr Err" 479 "SPS Auto On Input Over Curr Err" 480 "SPS Auto Off Output Over Curr Flt" 481 "SPS Auto On Output Over Curr Flt" 482 "SPS Auto Off Network PS Flt" 483 "SPS Auto On Network PS Flt" 484 "SPS Auto Off Setup Flt" 485 "SPS Auto On Setup Flt" 38 "Clear Command User Stats" 573 "AC Good Pending" 574 "Grid Safe" 585 "PLS Time In Float Ready" 575 "Power Conversion Fault" 576 "Low Battery Support Exit" 577 "Grid Support Exit" 578 "GFS Enable" 579 "GFS Disable" 580 "Force Sell" 486 "SPS Auto On Bulk Exit" 487 "SPS Auto Off Bulk Exit" 488 "SPS Auto On Absorption Exit" 489 "SPS Auto Off Absorption Exit" 490 "SPS Auto On State Of Charge Low" 491 "SPS Auto Off State Of Charge Low" 492 "SPS Auto On Time Of Day" 493 "SPS Auto Off Time Of Day" 581 "Sell Time Of Day Start" 582 "Sell Time Of Day Stop" 583 "Aux Port Time Of Day Start" 584 "Aux Port Time Of Day Stop" ;
VAL_ 2147552512 EvtId 436 "SPS Auto Off Array V Low" 437 "SPS Auto On Array V Low" 438 "SPS Auto Off Ground Flt" 439 "SPS Auto On Ground Flt" 440 "SPS Auto Off External Shutdown Flt" 0 "None" 10 "Control Command Hibernate" 11 "Control Command Safe" 12 "Control Command Power Save" 13 "Control Command Operating" 14 "Control Command Diagnostic" 15 "Control Command Last Mode" 20 "Reset Command Reboot" 21 "Reset Command Download" 22 "Reset Command Oem" 23 "Reset Command Factory" 24 "Reset Command Reboot Clear Nv" 25 "Powered Up" 30 "Clear Command Active Faults" 31 "Clear Command Fault Log" 32 "Clear Command Active Warns" 33 "Clear Command Warn Log" 34 "Clear Command State Event Log" 35 "Clear Command Comm Stats" 36 "Clear Command Stats" 37 "Clear Command All" 40 "Date Time Configured" 50 "Warn Cleared" 51 "Fault Cleared" 52 "Fault Set" 60 "User Cfg Changed" 61 "Oem Cfg Changed" 70 "Triggered Fault" 250 "Shutdown Threshold" 251 "Shutdown Hysteresis" 252 "Warning Threshold" 253 "Warning Hysteresis" 254 "Transfer Threshold" 255 "Fan 0 Threshold" 256 "Fan 10 Threshold" 257 "Fan 20 Threshold" 258 "Fan 30 Threshold" 259 "Fan 40 Threshold" 260 "Fan 50 Threshold" 261 "Fan 60 Threshold" 262 "Fan 70 Threshold" 263 "Fan 80 Threshold" 264 "Fan 90 Threshold" 265 "Fan 100 Threshold" 266 "Relay Open Threshold" 267 "Relay Close Threshold" 268 "Charger Derating Ac In V" 269 "Charger Derating Ac In I" 270 "Charger Derating Ext Temp" 271 "Charger Derating Int Temp" 272 "Charger Derating Ripple V" 273 "Lost Ac Threshold" 274 "Lost Ac Hysteresis" 275 "Imm Shutdown Threshold" 276 "Imm Shutdown Hysteresis" 277 "Charger Shutdown Threshold" 278 "Charger Shutdown Hysteresis" 279 "Charger Warning Threshold" 280 "Charger Warning Hysteresis" 281 "Inverter Shutdown Threshold" 282 "Inverter Shutdown Hysteresis" 283 "Inverter Warning Threshold" 284 "Inverter Warning Hysteresis" 285 "Charger Derating Temp Start Point" 286 "Charger Derating Temp End Point" 287 "Charger Recharge Threshold" 300 "Ags Exercise Start" 301 "Ags Exercise Stop" 302 "Ags Quiet Time Begin" 303 "Ags Quiet Time End" 304 "Ags Battery Soc Start" 305 "Ags Battery Soc Stop" 306 "Ags Dc V Start" 307 "Ags Dc V Stop" 308 "Ags Ac I Start" 309 "Ags Ac I Stop" 310 "Ags Contact Start" 311 "Ags Contact Stop" 312 "Ags Float Stop" 313 "Ags Absorp Stop" 314 "Ags Manual On" 315 "Ags Manual Off" 316 "Ags Auto" 317 "Ags External On" 318 "Ags External Off" 319 "Gen External On" 320 "Gen External Off" 321 "Ags External Shutdown" 322 "Ags Auto Off" 323 "Ags Dc I Start" 324 "Ags Dc I Stop" 325 "Ags Ac Power Start" 326 "Ags Ac Power Stop" 400 "Sps Manual Off" 401 "Sps Manual On" 410 "Sps Auto Off" 411 "Sps Auto On" 420 "Sps Auto Off Batt V Low" 421 "Sps Auto On Batt V Low" 422 "Sps Auto Off Batt V High" 423 "Sps Auto On Batt V High" 424 "Sps Auto Off Array V High" 425 "Sps Auto On Array V High" 426 "Sps Auto Off Batt Temp Low" 427 "Sps Auto On Batt Temp Low" 428 "Sps Auto Off Batt Temp High" 429 "Sps Auto On Batt Temp High" 430 "Sps Auto Off Heat Sink Temp High" 431 "Sps Auto On Heat Sink Temp High" 432 "Sps Auto Off Fault" 433 "Sps Auto On Fault" 434 "Aps Check Timeout" 435 "Aps Qualify Timeout" 512 "Resume From Safe" 513 "AC Fault Set" 514 "Invert Fault Set" 515 "Charge Fault Set" 516 "Charger Enable" 517 "Charger Disable" 518 "Inverter Enable" 519 "Inverter Disable" 520 "Charge Suspend On" 521 "Charge Suspend Off" 522 "AC Good" 523 "AC Bad" 524 "Load Sense Enable" 525 "Load Sense Active" 526 "Invert Active" 527 "Bulk Exit" 528 "Absorption Exit" 529 "Float Exit" 530 "Float 3-Stage Set" 531 "Float 2-Stage Set" 532 "Equalize Enable" 533 "Equalize Disable" 534 "Equalize Exit" 535 "Load Sense Disable" 536 "Sell To Grid Enabled" 537 "Sell To Grid Disabled" 538 "Grid Support Enable" 539 "Grid Support Disable" 540 "Gen Support Enable" 541 "Gen Support Disable" 542 "Peak Load Shaving Enable" 543 "Peak Load Shaving Disable" 544 "Peak Load Shaving Tod Start" 545 "Peak Load Shaving Tod Stop" 546 "Unit Off" 547 "System Absorption Exit" 548 "System Inverter Enable" 549 "System AC Good" 550 "Anti Islanding Condition" 551 "Hibernate Timeout" 552 "External Sync Error" 553 "External Suspend Request" 554 "Engaging Charger" 555 "Engaging Gen Support" 556 "Grid Tie Engage Timeout" 557 "Gen Support Engage Timeout" 558 "Charge Engage Timeout" 559 "Inverter Engage Timeout" 560 "Charge Exit Timeout" 561 "Grid Support Entry Amps" 562 "Grid Support Exit Amps" 563 "Gen Support Entry Amps" 564 "Gen Support Exit Amps" 565 "Grid Support Entry Vdc" 566 "Grid Support Exit Vdc" 567 "Low Batt Cut Off Entry Vdc" 568 "Low Batt Recharge Vdc" 569 "Low Batt Cut Off Exit Vdc" 570 "Invert To Bypass Timeout" 571 "Force Charge" 572 "System Engage Bulk Charge" 441 "SPS Auto On External Shutdown Flt" 442 "SPS Auto Off Input Over Volt Flt" 443 "SPS Auto On Input Over Volt Flt" 444 "SPS Auto Off Input Over Volt Err" 445 "SPS Auto On Input Over Volt Err" 446 "SPS Auto Off Input Over Volt Wrn" 447 "SPS Auto On Input Over Volt Wrn" 448 "SPS Auto Off Output Over Volt Err" 449 "SPS Auto On Output Over Volt Err" 450 "SPS Auto Off Output Over Volt Wrn" 451 "SPS Auto On Output Over Volt Wrn" 452 "SPS Auto Off Output Under Volt Err" 453 "SPS Auto On Output Under Volt Err" 454 "SPS Auto Off Output Under Volt Wrn" 455 "SPS Auto On Output Under Volt Wrn" 456 "SPS Auto Off Output Over Curr Err" 457 "SPS Auto On Output Over Curr Err" 458 "SPS Auto Off Batt Over Temp Err" 459 "SPS Auto On Batt Over Temp Err" 460 "SPS Auto Off Batt Over Temp Wrn" 461 "SPS Auto On Batt Over Temp Wrn" 462 "SPS Auto Off Batt Under Temp Wrn" 463 "SPS Auto On Batt Under Temp Wrn" 464 "SPS Auto Off Heatsink Over Temp Err" 465 "SPS Auto On Heatsink Over Temp Err" 466 "SPS Auto Off Heatsink Over Temp Wrn" 467 "SPS Auto On Heatsink Over Temp Wrn" 468 "SPS Auto Off Ambient Over Temp Err" 469 "SPS Auto On Ambient Over Temp Err" 470 "SPS Auto Off Ambient Over Temp Wrn" 471 "SPS Auto On Ambient Over Temp Wrn" 472 "SPS Auto Off Capacitor Over Temp Err" 473 "SPS Auto On Capacitor Over Temp Err" 474 "SPS Auto Off Fan Flt" 475 "SPS Auto On Fan Flt" 476 "SPS Auto Off Fan Err" 477 "SPS Auto On Fan Err" 478 "SPS Auto Off Input Over Curr Err" 479 "SPS Auto On Input Over Curr Err" 480 "SPS Auto Off Output Over Curr Flt" 481 "SPS Auto On Output Over Curr Flt" 482 "SPS Auto Off Network PS Flt" 483 "SPS Auto On Network PS Flt" 484 "SPS Auto Off Setup Flt" 485 "SPS Auto On Setup Flt" 38 "Clear Command User Stats" 573 "AC Good Pending" 574 "Grid Safe" 585 "PLS Time In Float Ready" 575 "Power Conversion Fault" 576 "Low Battery Support Exit" 577 "Grid Support Exit" 578 "GFS Enable" 579 "GFS Disable" 580 "Force Sell" 486 "SPS Auto On Bulk Exit" 487 "SPS Auto Off Bulk Exit" 488 "SPS Auto On Absorption Exit" 489 "SPS Auto Off Absorption Exit" 490 "SPS Auto On State Of Charge Low" 491 "SPS Auto Off State Of Charge Low" 492 "SPS Auto On Time Of Day" 493 "SPS Auto Off Time Of Day" 581 "Sell Time Of Day Start" 582 "Sell Time Of Day Stop" 583 "Aux Port Time Of Day Start" 584 "Aux Port Time Of Day Stop" ;
VAL_ 2147552512 CfgType 0 "User" 1 "OEM" 2 "Factory" 3 "Reserved" ;
VAL_ 2147552768 RefEvtId 436 "SPS Auto Off Array V Low" 437 "SPS Auto On Array V Low" 438 "SPS Auto Off Ground Flt" 439 "SPS Auto On Ground Flt" 440 "SPS Auto Off External Shutdown Flt" 0 "None" 10 "Control Command Hibernate" 11 "Control Command Safe" 12 "Control Command Power Save" 13 "Control Command Operating" 14 "Control Command Diagnostic" 15 "Control Command Last Mode" 20 "Reset Command Reboot" 21 "Reset Command Download" 22 "Reset Command Oem" 23 "Reset Command Factory" 24 "Reset Command Reboot Clear Nv" 25 "Powered Up" 30 "Clear Command Active Faults" 31 "Clear Command Fault Log" 32 "Clear Command Active Warns" 33 "Clear Command Warn Log" 34 "Clear Command State Event Log" 35 "Clear Command Comm Stats" 36 "Clear Command Stats" 37 "Clear Command All" 40 "Date Time Configured" 50 "Warn Cleared" 51 "Fault Cleared" 52 "Fault Set" 60 "User Cfg Changed" 61 "Oem Cfg Changed" 70 "Triggered Fault" 250 "Shutdown Threshold" 251 "Shutdown Hysteresis" 252 "Warning Threshold" 253 "Warning Hysteresis" 254 "Transfer Threshold" 255 "Fan 0 Threshold" 256 "Fan 10 Threshold" 257 "Fan 20 Threshold" 258 "Fan 30 Threshold" 259 "Fan 40 Threshold" 260 "Fan 50 Threshold" 261 "Fan 60 Threshold" 262 "Fan 70 Threshold" 263 "Fan 80 Threshold" 264 "Fan 90 Threshold" 265 "Fan 100 Threshold" 266 "Relay Open Threshold" 267 "Relay Close Threshold" 268 "Charger Derating Ac In V" 269 "Charger Derating Ac In I" 270 "Charger Derating Ext Temp" 271 "Charger Derating Int Temp" 272 "Charger Derating Ripple V" 273 "Lost Ac Threshold" 274 "Lost Ac Hysteresis" 275 "Imm Shutdown Threshold" 276 "Imm Shutdown Hysteresis" 277 "Charger Shutdown Threshold" 278 "Charger Shutdown Hysteresis" 279 "Charger Warning Threshold" 280 "Charger Warning Hysteresis" 281 "Inverter Shutdown Threshold" 282 "Inverter Shutdown Hysteresis" 283 "Inverter Warning Threshold" 284 "Inverter Warning Hysteresis" 285 "Charger Derating Temp Start Point" 286 "Charger Derating Temp End Point" 287 "Charger Recharge Threshold" 300 "Ags Exercise Start" 301 "Ags Exercise Stop" 302 "Ags Quiet Time Begin" 303 "Ags Quiet Time End" 304 "Ags Battery Soc Start" 305 "Ags Battery Soc Stop" 306 "Ags Dc V Start" 307 "Ags Dc V Stop" 308 "Ags Ac I Start" 309 "Ags Ac I Stop" 310 "Ags Contact Start" 311 "Ags Contact Stop" 312 "Ags Float Stop" 313 "Ags Absorp Stop" 314 "Ags Manual On" 315 "Ags Manual Off" 316 "Ags Auto" 317 "Ags External On" 318 "Ags External Off" 319 "Gen External On" 320 "Gen External Off" 321 "Ags External Shutdown" 322 "Ags Auto Off" 323 "Ags Dc I Start" 324 "Ags Dc I Stop" 325 "Ags Ac Power Start" 326 "Ags Ac Power Stop" 400 "Sps Manual Off" 401 "Sps Manual On" 410 "Sps Auto Off" 411 "Sps Auto On" 420 "Sps Auto Off Batt V Low" 421 "Sps Auto On Batt V Low" 422 "Sps Auto Off Batt V High" 423 "Sps Auto On Batt V High" 424 "Sps Auto Off Array V High" 425 "Sps Auto On Array V High" 426 "Sps Auto Off Batt Temp Low" 427 "Sps Auto On Batt Temp Low" 428 "Sps Auto Off Batt Temp High" 429 "Sps Auto On Batt Temp High" 430 "Sps Auto Off Heat Sink Temp High" 431 "Sps Auto On Heat Sink Temp High" 432 "Sps Auto Off Fault" 433 "Sps Auto On Fault" 434 "Aps Check Timeout" 435 "Aps Qualify Timeout" 512 "Resume From Safe" 513 "AC Fault Set" 514 "Invert Fault Set" 515 "Charge Fault Set" 516 "Charger Enable" 517 "Charger Disable" 518 "Inverter Enable" 519 "Inverter Disable" 520 "Charge Suspend On" 521 "Charge Suspend Off" 522 "AC Good" 523 "AC Bad" 524 "Load Sense Enable" 525 "Load Sense Active" 526 "Invert Active" 527 "Bulk Exit" 528 "Absorption Exit" 529 "Float Exit" 530 "Float 3-Stage Set" 531 "Float 2-Stage Set" 532 "Equalize Enable" 533 "Equalize Disable" 534 "Equalize Exit" 535 "Load Sense Disable" 536 "Sell To Grid Enabled" 537 "Sell To Grid Disabled" 538 "Grid Support Enable" 539 "Grid Support Disable" 540 "Gen Support Enable" 541 "Gen Support Disable" 542 "Peak Load Shaving Enable" 543 "Peak Load Shaving Disable" 544 "Peak Load Shaving Tod Start" 545 "Peak Load Shaving Tod Stop" 546 "Unit Off" 547 "System Absorption Exit" 548 "System Inverter Enable" 549 "System AC Good" 550 "Anti Islanding Condition" 551 "Hibernate Timeout" 552 "External Sync Error" 553 "External Suspend Request" 554 "Engaging Charger" 555 "Engaging Gen Support" 556 "Grid Tie Engage Timeout" 557 "Gen Support Engage Timeout" 558 "Charge Engage Timeout" 559 "Inverter Engage Timeout" 560 "Charge Exit Timeout" 561 "Grid Support Entry Amps" 562 "Grid Support Exit Amps" 563 "Gen Support Entry Amps" 564 "Gen Support Exit Amps" 565 "Grid Support Entry Vdc" 566 "Grid Support Exit Vdc" 567 "Low Batt Cut Off Entry Vdc" 568 "Low Batt Recharge Vdc" 569 "Low Batt Cut Off Exit Vdc" 570 "Invert To Bypass Timeout" 571 "Force Charge" 572 "System Engage Bulk Charge" 441 "SPS Auto On External Shutdown Flt" 442 "SPS Auto Off Input Over Volt Flt" 443 "SPS Auto On Input Over Volt Flt" 444 "SPS Auto Off Input Over Volt Err" 445 "SPS Auto On Input Over Volt Err" 446 "SPS Auto Off Input Over Volt Wrn" 447 "SPS Auto On Input Over Volt Wrn" 448 "SPS Auto Off Output Over Volt Err" 449 "SPS Auto On Output Over Volt Err" 450 "SPS Auto Off Output Over Volt Wrn" 451 "SPS Auto On Output Over Volt Wrn" 452 "SPS Auto Off Output Under Volt Err" 453 "SPS Auto On Output Under Volt Err" 454 "SPS Auto Off Output Under Volt Wrn" 455 "SPS Auto On Output Under Volt Wrn" 456 "SPS Auto Off Output Over Curr Err" 457 "SPS Auto On Output Over Curr Err" 458 "SPS Auto Off Batt Over Temp Err" 459 "SPS Auto On Batt Over Temp Err" 460 "SPS Auto Off Batt Over Temp Wrn" 461 "SPS Auto On Batt Over Temp Wrn" 462 "SPS Auto Off Batt Under Temp Wrn" 463 "SPS Auto On Batt Under Temp Wrn" 464 "SPS Auto Off Heatsink Over Temp Err" 465 "SPS Auto On Heatsink Over Temp Err" 466 "SPS Auto Off Heatsink Over Temp Wrn" 467 "SPS Auto On Heatsink Over Temp Wrn" 468 "SPS Auto Off Ambient Over Temp Err" 469 "SPS Auto On Ambient Over Temp Err" 470 "SPS Auto Off Ambient Over Temp Wrn" 471 "SPS Auto On Ambient Over Temp Wrn" 472 "SPS Auto Off Capacitor Over Temp Err" 473 "SPS Auto On Capacitor Over Temp Err" 474 "SPS Auto Off Fan Flt" 475 "SPS Auto On Fan Flt" 476 "SPS Auto Off Fan Err" 477 "SPS Auto On Fan Err" 478 "SPS Auto Off Input Over Curr Err" 479 "SPS Auto On Input Over Curr Err" 480 "SPS Auto Off Output Over Curr Flt" 481 "SPS Auto On Output Over Curr Flt" 482 "SPS Auto Off Network PS Flt" 483 "SPS Auto On Network PS Flt" 484 "SPS Auto Off Setup Flt" 485 "SPS Auto On Setup Flt" 38 "Clear Command User Stats" 573 "AC Good Pending" 574 "Grid Safe" 585 "PLS Time In Float Ready" 575 "Power Conversion Fault" 576 "Low Battery Support Exit" 577 "Grid Support Exit" 578 "GFS Enable" 579 "GFS Disable" 580 "Force Sell" 486 "SPS Auto On Bulk Exit" 487 "SPS Auto Off Bulk Exit" 488 "SPS Auto On Absorption Exit" 489 "SPS Auto Off Absorption Exit" 490 "SPS Auto On State Of Charge Low" 491 "SPS Auto Off State Of Charge Low" 492 "SPS Auto On Time Of Day" 493 "SPS Auto Off Time Of Day" 581 "Sell Time Of Day Start" 582 "Sell Time Of Day Stop" 583 "Aux Port Time Of Day Start" 584 "Aux Port Time Of Day Stop" ;
VAL_ 2147552768 EvtId 436 "SPS Auto Off Array V Low" 437 "SPS Auto On Array V Low" 438 "SPS Auto Off Ground Flt" 439 "SPS Auto On Ground Flt" 440 "SPS Auto Off External Shutdown Flt" 0 "None" 10 "Control Command Hibernate" 11 "Control Command Safe" 12 "Control Command Power Save" 13 "Control Command Operating" 14 "Control Command Diagnostic" 15 "Control Command Last Mode" 20 "Reset Command Reboot" 21 "Reset Command Download" 22 "Reset Command Oem" 23 "Reset Command Factory" 24 "Reset Command Reboot Clear Nv" 25 "Powered Up" 30 "Clear Command Active Faults" 31 "Clear Command Fault Log" 32 "Clear Command Active Warns" 33 "Clear Command Warn Log" 34 "Clear Command State Event Log" 35 "Clear Command Comm Stats" 36 "Clear Command Stats" 37 "Clear Command All" 40 "Date Time Configured" 50 "Warn Cleared" 51 "Fault Cleared" 52 "Fault Set" 60 "User Cfg Changed" 61 "Oem Cfg Changed" 70 "Triggered Fault" 250 "Shutdown Threshold" 251 "Shutdown Hysteresis" 252 "Warning Threshold" 253 "Warning Hysteresis" 254 "Transfer Threshold" 255 "Fan 0 Threshold" 256 "Fan 10 Threshold" 257 "Fan 20 Threshold" 258 "Fan 30 Threshold" 259 "Fan 40 Threshold" 260 "Fan 50 Threshold" 261 "Fan 60 Threshold" 262 "Fan 70 Threshold" 263 "Fan 80 Threshold" 264 "Fan 90 Threshold" 265 "Fan 100 Threshold" 266 "Relay Open Threshold" 267 "Relay Close Threshold" 268 "Charger Derating Ac In V" 269 "Charger Derating Ac In I" 270 "Charger Derating Ext Temp" 271 "Charger Derating Int Temp" 272 "Charger Derating Ripple V" 273 "Lost Ac Threshold" 274 "Lost Ac Hysteresis" 275 "Imm Shutdown Threshold" 276 "Imm Shutdown Hysteresis" 277 "Charger Shutdown Threshold" 278 "Charger Shutdown Hysteresis" 279 "Charger Warning Threshold" 280 "Charger Warning Hysteresis" 281 "Inverter Shutdown Threshold" 282 "Inverter Shutdown Hysteresis" 283 "Inverter Warning Threshold" 284 "Inverter Warning Hysteresis" 285 "Charger Derating Temp Start Point" 286 "Charger Derating Temp End Point" 287 "Charger Recharge Threshold" 300 "Ags Exercise Start" 301 "Ags Exercise Stop" 302 "Ags Quiet Time Begin" 303 "Ags Quiet Time End" 304 "Ags Battery Soc Start" 305 "Ags Battery Soc Stop" 306 "Ags Dc V Start" 307 "Ags Dc V Stop" 308 "Ags Ac I Start" 309 "Ags Ac I Stop" 310 "Ags Contact Start" 311 "Ags Contact Stop" 312 "Ags Float Stop" 313 "Ags Absorp Stop" 314 "Ags Manual On" 315 "Ags Manual Off" 316 "Ags Auto" 317 "Ags External On" 318 "Ags External Off" 319 "Gen External On" 320 "Gen External Off" 321 "Ags External Shutdown" 322 "Ags Auto Off" 323 "Ags Dc I Start" 324 "Ags Dc I Stop" 325 "Ags Ac Power Start" 326 "Ags Ac Power Stop" 400 "Sps Manual Off" 401 "Sps Manual On" 410 "Sps Auto Off" 411 "Sps Auto On" 420 "Sps Auto Off Batt V Low" 421 "Sps Auto On Batt V Low" 422 "Sps Auto Off Batt V High" 423 "Sps Auto On Batt V High" 424 "Sps Auto Off Array V High" 425 "Sps Auto On Array V High" 426 "Sps Auto Off Batt Temp Low" 427 "Sps Auto On Batt Temp Low" 428 "Sps Auto Off Batt Temp High" 429 "Sps Auto On Batt Temp High" 430 "Sps Auto Off Heat Sink Temp High" 431 "Sps Auto On Heat Sink Temp High" 432 "Sps Auto Off Fault" 433 "Sps Auto On Fault" 434 "Aps Check Timeout" 435 "Aps Qualify Timeout" 512 "Resume From Safe" 513 "AC Fault Set" 514 "Invert Fault Set" 515 "Charge Fault Set" 516 "Charger Enable" 517 "Charger Disable" 518 "Inverter Enable" 519 "Inverter Disable" 520 "Charge Suspend On" 521 "Charge Suspend Off" 522 "AC Good" 523 "AC Bad" 524 "Load Sense Enable" 525 "Load Sense Active" 526 "Invert Active" 527 "Bulk Exit" 528 "Absorption Exit" 529 "Float Exit" 530 "Float 3-Stage Set" 531 "Float 2-Stage Set" 532 "Equalize Enable" 533 "Equalize Disable" 534 "Equalize Exit" 535 "Load Sense Disable" 536 "Sell To Grid Enabled" 537 "Sell To Grid Disabled" 538 "Grid Support Enable" 539 "Grid Support Disable" 540 "Gen Support Enable" 541 "Gen Support Disable" 542 "Peak Load Shaving Enable" 543 "Peak Load Shaving Disable" 544 "Peak Load Shaving Tod Start" 545 "Peak Load Shaving Tod Stop" 546 "Unit Off" 547 "System Absorption Exit" 548 "System Inverter Enable" 549 "System AC Good" 550 "Anti Islanding Condition" 551 "Hibernate Timeout" 552 "External Sync Error" 553 "External Suspend Request" 554 "Engaging Charger" 555 "Engaging Gen Support" 556 "Grid Tie Engage Timeout" 557 "Gen Support Engage Timeout" 558 "Charge Engage Timeout" 559 "Inverter Engage Timeout" 560 "Charge Exit Timeout" 561 "Grid Support Entry Amps" 562 "Grid Support Exit Amps" 563 "Gen Support Entry Amps" 564 "Gen Support Exit Amps" 565 "Grid Support Entry Vdc" 566 "Grid Support Exit Vdc" 567 "Low Batt Cut Off Entry Vdc" 568 "Low Batt Recharge Vdc" 569 "Low Batt Cut Off Exit Vdc" 570 "Invert To Bypass Timeout" 571 "Force Charge" 572 "System Engage Bulk Charge" 441 "SPS Auto On External Shutdown Flt" 442 "SPS Auto Off Input Over Volt Flt" 443 "SPS Auto On Input Over Volt Flt" 444 "SPS Auto Off Input Over Volt Err" 445 "SPS Auto On Input Over Volt Err" 446 "SPS Auto Off Input Over Volt Wrn" 447 "SPS Auto On Input Over Volt Wrn" 448 "SPS Auto Off Output Over Volt Err" 449 "SPS Auto On Output Over Volt Err" 450 "SPS Auto Off Output Over Volt Wrn" 451 "SPS Auto On Output Over Volt Wrn" 452 "SPS Auto Off Output Under Volt Err" 453 "SPS Auto On Output Under Volt Err" 454 "SPS Auto Off Output Under Volt Wrn" 455 "SPS Auto On Output Under Volt Wrn" 456 "SPS Auto Off Output Over Curr Err" 457 "SPS Auto On Output Over Curr Err" 458 "SPS Auto Off Batt Over Temp Err" 459 "SPS Auto On Batt Over Temp Err" 460 "SPS Auto Off Batt Over Temp Wrn" 461 "SPS Auto On Batt Over Temp Wrn" 462 "SPS Auto Off Batt Under Temp Wrn" 463 "SPS Auto On Batt Under Temp Wrn" 464 "SPS Auto Off Heatsink Over Temp Err" 465 "SPS Auto On Heatsink Over Temp Err" 466 "SPS Auto Off Heatsink Over Temp Wrn" 467 "SPS Auto On Heatsink Over Temp Wrn" 468 "SPS Auto Off Ambient Over Temp Err" 469 "SPS Auto On Ambient Over Temp Err" 470 "SPS Auto Off Ambient Over Temp Wrn" 471 "SPS Auto On Ambient Over Temp Wrn" 472 "SPS Auto Off Capacitor Over Temp Err" 473 "SPS Auto On Capacitor Over Temp Err" 474 "SPS Auto Off Fan Flt" 475 "SPS Auto On Fan Flt" 476 "SPS Auto Off Fan Err" 477 "SPS Auto On Fan Err" 478 "SPS Auto Off Input Over Curr Err" 479 "SPS Auto On Input Over Curr Err" 480 "SPS Auto Off Output Over Curr Flt" 481 "SPS Auto On Output Over Curr Flt" 482 "SPS Auto Off Network PS Flt" 483 "SPS Auto On Network PS Flt" 484 "SPS Auto Off Setup Flt" 485 "SPS Auto On Setup Flt" 38 "Clear Command User Stats" 573 "AC Good Pending" 574 "Grid Safe" 585 "PLS Time In Float Ready" 575 "Power Conversion Fault" 576 "Low Battery Support Exit" 577 "Grid Support Exit" 578 "GFS Enable" 579 "GFS Disable" 580 "Force Sell" 486 "SPS Auto On Bulk Exit" 487 "SPS Auto Off Bulk Exit" 488 "SPS Auto On Absorption Exit" 489 "SPS Auto Off Absorption Exit" 490 "SPS Auto On State Of Charge Low" 491 "SPS Auto Off State Of Charge Low" 492 "SPS Auto On Time Of Day" 493 "SPS Auto Off Time Of Day" 581 "Sell Time Of Day Start" 582 "Sell Time Of Day Stop" 583 "Aux Port Time Of Day Start" 584 "Aux Port Time Of Day Stop" ;
VAL_ 2147552768 CfgType 0 "User" 1 "OEM" 2 "Factory" 3 "Reserved" ;
VAL_ 2147610647 AcSrcId 0 "Invalid" 1 "None" 2 "Anonymous" 3 "Shore1" 4 "Shore2" 5 "Shore3" 6 "Shore4" 7 "Shore5" 8 "Shore6" 9 "Shore7" 10 "Shore8" 11 "Shore9" 12 "Shore10" 13 "Shore11" 14 "Shore12" 15 "Shore13" 16 "Shore14" 17 "Shore15" 18 "Shore16" 19 "Gen1" 20 "Gen2" 21 "Gen3" 22 "Gen4" 23 "Gen5" 24 "Gen6" 25 "Gen7" 26 "Gen8" 27 "Gen9" 28 "Gen10" 29 "Gen11" 30 "Gen12" 31 "Gen13" 32 "Gen14" 33 "Gen15" 34 "Gen16" 35 "AC1" 36 "AC2" 37 "AC3" 38 "AC4" 39 "AC5" 40 "AC6" 41 "AC7" 42 "AC8" 43 "AC9" 44 "AC10" 45 "AC11" 46 "AC12" 47 "AC13" 48 "AC14" 49 "AC15" 50 "AC16" 51 "AC Load1" 52 "AC Load2" 53 "AC Load3" 54 "AC Load4" 55 "AC Load5" 56 "AC Load6" 57 "AC Load7" 58 "AC Load8" 59 "AC Load9" 60 "AC Load10" 61 "AC Load11" 62 "AC Load12" 63 "AC Load13" 64 "AC Load14" 65 "AC Load15" 66 "AC Load16" 67 "Grid1" 68 "Grid2" 69 "Grid3" 70 "Grid4" 71 "Grid5" 72 "Grid6" 73 "Grid7" 74 "Grid8" 75 "Grid9" 76 "Grid10" 77 "Grid11" 78 "Grid12" 79 "Grid13" 80 "Grid14" 81 "Grid15" 82 "Grid16" 252 "All" 253 "Reserved" 254 "Out Of Range" 255 "Data Not Available Do Not Change" ;
VAL_ 2147610641 OpState 265 "Quiet Time" 266 "Auto On" 267 "Auto Off" 268 "Manual On" 269 "Manual Off" 270 "Generator Shutdown" 271 "External Shutdown" 272 "AGS Fault" 273 "Suspend" 274 "Not Operating" ;
VAL_ 2147610641 GenState 0 "Preheating" 1 "Start Delay" 2 "Cranking" 3 "Starter Cooling" 4 "Warming Up" 5 "Cooling Down" 6 "Spinning Down" 7 "Shutdown Bypass" 8 "Stopping" 9 "Running" 10 "Stopped" 11 "Crank Delay" 253 "Reserved" 254 "Out Of Range" 255 "Data Not Available Do Not Change" ;
VAL_ 2147610641 GenOnReason 0 "Not On" 1 "DC Voltage Low" 2 "Battery SOC Low" 3 "AC Current High" 4 "Contact Closed" 5 "Manual On" 6 "Exercise" 7 "Non Quiet Time" 8 "External On via AGS" 9 "External On via Generator" 10 "Unable To Stop" 11 "AC Power High" 12 "DC Current High" ;
VAL_ 2147610641 GenOffReason 0 "Not Off" 1 "DC Voltage High" 2 "Battery SOC High" 3 "AC Current Low" 4 "Contact Opened" 5 "Reached Absorption" 6 "Reached Float" 7 "Manual Off" 8 "Max Run Time" 9 "Max Auto Cycle" 10 "Exercise Done" 11 "Quiet Time" 12 "External Off via AGS" 13 "Safe Mode" 14 "External Off via Generator" 15 "External Shutdown" 16 "Auto Off" 17 "Fault" 18 "Unable To Start" 19 "AC Power Low" 20 "DC Current Low" 21 "AC Good" ;
VAL_ 2147610641 AgsGenSig 0 "Off" 1 "On" 2 "Error" 3 "Unknown" ;
VAL_ 2147610641 AcSrcId 0 "Invalid" 1 "None" 2 "Anonymous" 3 "Shore1" 4 "Shore2" 5 "Shore3" 6 "Shore4" 7 "Shore5" 8 "Shore6" 9 "Shore7" 10 "Shore8" 11 "Shore9" 12 "Shore10" 13 "Shore11" 14 "Shore12" 15 "Shore13" 16 "Shore14" 17 "Shore15" 18 "Shore16" 19 "Gen1" 20 "Gen2" 21 "Gen3" 22 "Gen4" 23 "Gen5" 24 "Gen6" 25 "Gen7" 26 "Gen8" 27 "Gen9" 28 "Gen10" 29 "Gen11" 30 "Gen12" 31 "Gen13" 32 "Gen14" 33 "Gen15" 34 "Gen16" 35 "AC1" 36 "AC2" 37 "AC3" 38 "AC4" 39 "AC5" 40 "AC6" 41 "AC7" 42 "AC8" 43 "AC9" 44 "AC10" 45 "AC11" 46 "AC12" 47 "AC13" 48 "AC14" 49 "AC15" 50 "AC16" 51 "AC Load1" 52 "AC Load2" 53 "AC Load3" 54 "AC Load4" 55 "AC Load5" 56 "AC Load6" 57 "AC Load7" 58 "AC Load8" 59 "AC Load9" 60 "AC Load10" 61 "AC Load11" 62 "AC Load12" 63 "AC Load13" 64 "AC Load14" 65 "AC Load15" 66 "AC Load16" 67 "Grid1" 68 "Grid2" 69 "Grid3" 70 "Grid4" 71 "Grid5" 72 "Grid6" 73 "Grid7" 74 "Grid8" 75 "Grid9" 76 "Grid10" 77 "Grid11" 78 "Grid12" 79 "Grid13" 80 "Grid14" 81 "Grid15" 82 "Grid16" 252 "All" 253 "Reserved" 254 "Out Of Range" 255 "Data Not Available Do Not Change" ;
VAL_ 2147610648 AcSrcId 0 "Invalid" 1 "None" 2 "Anonymous" 3 "Shore1" 4 "Shore2" 5 "Shore3" 6 "Shore4" 7 "Shore5" 8 "Shore6" 9 "Shore7" 10 "Shore8" 11 "Shore9" 12 "Shore10" 13 "Shore11" 14 "Shore12" 15 "Shore13" 16 "Shore14" 17 "Shore15" 18 "Shore16" 19 "Gen1" 20 "Gen2" 21 "Gen3" 22 "Gen4" 23 "Gen5" 24 "Gen6" 25 "Gen7" 26 "Gen8" 27 "Gen9" 28 "Gen10" 29 "Gen11" 30 "Gen12" 31 "Gen13" 32 "Gen14" 33 "Gen15" 34 "Gen16" 35 "AC1" 36 "AC2" 37 "AC3" 38 "AC4" 39 "AC5" 40 "AC6" 41 "AC7" 42 "AC8" 43 "AC9" 44 "AC10" 45 "AC11" 46 "AC12" 47 "AC13" 48 "AC14" 49 "AC15" 50 "AC16" 51 "AC Load1" 52 "AC Load2" 53 "AC Load3" 54 "AC Load4" 55 "AC Load5" 56 "AC Load6" 57 "AC Load7" 58 "AC Load8" 59 "AC Load9" 60 "AC Load10" 61 "AC Load11" 62 "AC Load12" 63 "AC Load13" 64 "AC Load14" 65 "AC Load15" 66 "AC Load16" 67 "Grid1" 68 "Grid2" 69 "Grid3" 70 "Grid4" 71 "Grid5" 72 "Grid6" 73 "Grid7" 74 "Grid8" 75 "Grid9" 76 "Grid10" 77 "Grid11" 78 "Grid12" 79 "Grid13" 80 "Grid14" 81 "Grid15" 82 "Grid16" 252 "All" 253 "Reserved" 254 "Out Of Range" 255 "Data Not Available Do Not Change" ;
VAL_ 2147557120 DesiredState 0 "Manual Off" 1 "Manual On" 2 "Automatic" 253 "Reserved" 254 "Out Of Range" 255 "Data Not Available Do Not Change" 3 "Force On Auto Off" ;
VAL_ 2147557120 AcSrcId 0 "Invalid" 1 "None" 2 "Anonymous" 3 "Shore1" 4 "Shore2" 5 "Shore3" 6 "Shore4" 7 "Shore5" 8 "Shore6" 9 "Shore7" 10 "Shore8" 11 "Shore9" 12 "Shore10" 13 "Shore11" 14 "Shore12" 15 "Shore13" 16 "Shore14" 17 "Shore15" 18 "Shore16" 19 "Gen1" 20 "Gen2" 21 "Gen3" 22 "Gen4" 23 "Gen5" 24 "Gen6" 25 "Gen7" 26 "Gen8" 27 "Gen9" 28 "Gen10" 29 "Gen11" 30 "Gen12" 31 "Gen13" 32 "Gen14" 33 "Gen15" 34 "Gen16" 35 "AC1" 36 "AC2" 37 "AC3" 38 "AC4" 39 "AC5" 40 "AC6" 41 "AC7" 42 "AC8" 43 "AC9" 44 "AC10" 45 "AC11" 46 "AC12" 47 "AC13" 48 "AC14" 49 "AC15" 50 "AC16" 51 "AC Load1" 52 "AC Load2" 53 "AC Load3" 54 "AC Load4" 55 "AC Load5" 56 "AC Load6" 57 "AC Load7" 58 "AC Load8" 59 "AC Load9" 60 "AC Load10" 61 "AC Load11" 62 "AC Load12" 63 "AC Load13" 64 "AC Load14" 65 "AC Load15" 66 "AC Load16" 67 "Grid1" 68 "Grid2" 69 "Grid3" 70 "Grid4" 71 "Grid5" 72 "Grid6" 73 "Grid7" 74 "Grid8" 75 "Grid9" 76 "Grid10" 77 "Grid11" 78 "Grid12" 79 "Grid13" 80 "Grid14" 81 "Grid15" 82 "Grid16" 252 "All" 253 "Reserved" 254 "Out Of Range" 255 "Data Not Available Do Not Change" ;
VAL_ 2147560192 RelayId 1 "Relay 1" 2 "Relay 2" 3 "Relay 3" 4 "Relay 4" 5 "Relay 5" 253 "Reserved" 254 "Out Of Range" 255 "Data Not Available Do Not Change" ;
VAL_ 2147560192 RelayFunc 0 "Not Used" 1 "Run" 2 "Glow and Stop" 3 "Glow and Stop with Shutdown Bypass" 4 "Crank" 5 "Preheat" 6 "Warm Up and Cool Down" 7 "Start and Stop" 8 "Preheat with Shutdown Bypass" 9 "Momentary Run" 10 "Pulse Stop" 253 "Reserved" 254 "Out Of Range" 255 "Data Not Available Do Not Change" ;
VAL_ 2147560192 GenOutType 0 "AC Output" 1 "DC Output" 253 "Reserved" 254 "Out Of Range" 255 "Data Not Available Do Not Change" ;
VAL_ 2147560192 GenIntfType 1 "1" 2 "2" 3 "3" 4 "4" 5 "5" 6 "6" 7 "7" 8 "8" 9 "9" 10 "10" 11 "11" 12 "12" 13 "13" 14 "14" 15 "15" 16 "16" 17 "17" 18 "18" 19 "19" 20 "20" 21 "21" 22 "22" 23 "23" 24 "24" 25 "25" 26 "26" 27 "27" 28 "28" 29 "29" 30 "30" 253 "Reserved" 254 "Out of Range" 255 "Data Not Available Do Not Change" ;
VAL_ 2147560192 CfgType 0 "User" 1 "OEM" 2 "Factory" 3 "Reserved" ;
VAL_ 2147560192 AcSrcId 0 "Invalid" 1 "None" 2 "Anonymous" 3 "Shore1" 4 "Shore2" 5 "Shore3" 6 "Shore4" 7 "Shore5" 8 "Shore6" 9 "Shore7" 10 "Shore8" 11 "Shore9" 12 "Shore10" 13 "Shore11" 14 "Shore12" 15 "Shore13" 16 "Shore14" 17 "Shore15" 18 "Shore16" 19 "Gen1" 20 "Gen2" 21 "Gen3" 22 "Gen4" 23 "Gen5" 24 "Gen6" 25 "Gen7" 26 "Gen8" 27 "Gen9" 28 "Gen10" 29 "Gen11" 30 "Gen12" 31 "Gen13" 32 "Gen14" 33 "Gen15" 34 "Gen16" 35 "AC1" 36 "AC2" 37 "AC3" 38 "AC4" 39 "AC5" 40 "AC6" 41 "AC7" 42 "AC8" 43 "AC9" 44 "AC10" 45 "AC11" 46 "AC12" 47 "AC13" 48 "AC14" 49 "AC15" 50 "AC16" 51 "AC Load1" 52 "AC Load2" 53 "AC Load3" 54 "AC Load4" 55 "AC Load5" 56 "AC Load6" 57 "AC Load7" 58 "AC Load8" 59 "AC Load9" 60 "AC Load10" 61 "AC Load11" 62 "AC Load12" 63 "AC Load13" 64 "AC Load14" 65 "AC Load15" 66 "AC Load16" 67 "Grid1" 68 "Grid2" 69 "Grid3" 70 "Grid4" 71 "Grid5" 72 "Grid6" 73 "Grid7" 74 "Grid8" 75 "Grid9" 76 "Grid10" 77 "Grid11" 78 "Grid12" 79 "Grid13" 80 "Grid14" 81 "Grid15" 82 "Grid16" 252 "All" 253 "Reserved" 254 "Out Of Range" 255 "Data Not Available Do Not Change" ;
VAL_ 2147564544 StartStop 0 "Off" 1 "On" 2 "Reserved" 3 "No Change" ;
VAL_ 2147564544 DcSrcId 0 "Invalid" 1 "None" 2 "Anonymous" 3 "HouseBatBank1" 4 "HouseBatBank2" 5 "HouseBatBank3" 6 "HouseBatBank4" 7 "HouseBatBank5" 8 "HouseBatBank6" 9 "StartBatBank1" 10 "StartBatBank2" 11 "StartBatBank3" 12 "StartBatBank4" 13 "StartBatBank5" 14 "StartBatBank6" 21 "SolarArray1" 22 "SolarArray2" 23 "SolarArray3" 24 "SolarArray4" 25 "SolarArray5" 26 "SolarArray6" 27 "SolarArray7" 28 "SolarArray8" 29 "SolarArray9" 30 "SolarArray10" 31 "SolarArray11" 32 "SolarArray12" 33 "SolarArray13" 34 "SolarArray14" 35 "SolarArray15" 36 "SolarArray16" 252 "All" 253 "Reserved" 254 "Out of Range" 255 "Data Not Available Do Not Change" ;
VAL_ 2147564544 CfgType 0 "User" 1 "OEM" 2 "Factory" 3 "Reserved" ;
VAL_ 2147571200 StartStop 0 "Off" 1 "On" 2 "Reserved" 3 "No Change" ;
VAL_ 2147571200 DcSrcId 0 "Invalid" 1 "None" 2 "Anonymous" 3 "HouseBatBank1" 4 "HouseBatBank2" 5 "HouseBatBank3" 6 "HouseBatBank4" 7 "HouseBatBank5" 8 "HouseBatBank6" 9 "StartBatBank1" 10 "StartBatBank2" 11 "StartBatBank3" 12 "StartBatBank4" 13 "StartBatBank5" 14 "StartBatBank6" 21 "SolarArray1" 22 "SolarArray2" 23 "SolarArray3" 24 "SolarArray4" 25 "SolarArray5" 26 "SolarArray6" 27 "SolarArray7" 28 "SolarArray8" 29 "SolarArray9" 30 "SolarArray10" 31 "SolarArray11" 32 "SolarArray12" 33 "SolarArray13" 34 "SolarArray14" 35 "SolarArray15" 36 "SolarArray16" 252 "All" 253 "Reserved" 254 "Out of Range" 255 "Data Not Available Do Not Change" ;
VAL_ 2147571200 CfgType 0 "User" 1 "OEM" 2 "Factory" 3 "Reserved" ;
VAL_ 2147565312 CfgType 0 "User" 1 "OEM" 2 "Factory" 3 "Reserved" ;
VAL_ 2147565312 AcSrcId 0 "Invalid" 1 "None" 2 "Anonymous" 3 "Shore1" 4 "Shore2" 5 "Shore3" 6 "Shore4" 7 "Shore5" 8 "Shore6" 9 "Shore7" 10 "Shore8" 11 "Shore9" 12 "Shore10" 13 "Shore11" 14 "Shore12" 15 "Shore13" 16 "Shore14" 17 "Shore15" 18 "Shore16" 19 "Gen1" 20 "Gen2" 21 "Gen3" 22 "Gen4" 23 "Gen5" 24 "Gen6" 25 "Gen7" 26 "Gen8" 27 "Gen9" 28 "Gen10" 29 "Gen11" 30 "Gen12" 31 "Gen13" 32 "Gen14" 33 "Gen15" 34 "Gen16" 35 "AC1" 36 "AC2" 37 "AC3" 38 "AC4" 39 "AC5" 40 "AC6" 41 "AC7" 42 "AC8" 43 "AC9" 44 "AC10" 45 "AC11" 46 "AC12" 47 "AC13" 48 "AC14" 49 "AC15" 50 "AC16" 51 "AC Load1" 52 "AC Load2" 53 "AC Load3" 54 "AC Load4" 55 "AC Load5" 56 "AC Load6" 57 "AC Load7" 58 "AC Load8" 59 "AC Load9" 60 "AC Load10" 61 "AC Load11" 62 "AC Load12" 63 "AC Load13" 64 "AC Load14" 65 "AC Load15" 66 "AC Load16" 67 "Grid1" 68 "Grid2" 69 "Grid3" 70 "Grid4" 71 "Grid5" 72 "Grid6" 73 "Grid7" 74 "Grid8" 75 "Grid9" 76 "Grid10" 77 "Grid11" 78 "Grid12" 79 "Grid13" 80 "Grid14" 81 "Grid15" 82 "Grid16" 252 "All" 253 "Reserved" 254 "Out Of Range" 255 "Data Not Available Do Not Change" ;
VAL_ 2147564800 StartStop 0 "Off" 1 "On" 2 "Reserved" 3 "No Change" ;
VAL_ 2147564800 DcSrcId 0 "Invalid" 1 "None" 2 "Anonymous" 3 "HouseBatBank1" 4 "HouseBatBank2" 5 "HouseBatBank3" 6 "HouseBatBank4" 7 "HouseBatBank5" 8 "HouseBatBank6" 9 "StartBatBank1" 10 "StartBatBank2" 11 "StartBatBank3" 12 "StartBatBank4" 13 "StartBatBank5" 14 "StartBatBank6" 21 "SolarArray1" 22 "SolarArray2" 23 "SolarArray3" 24 "SolarArray4" 25 "SolarArray5" 26 "SolarArray6" 27 "SolarArray7" 28 "SolarArray8" 29 "SolarArray9" 30 "SolarArray10" 31 "SolarArray11" 32 "SolarArray12" 33 "SolarArray13" 34 "SolarArray14" 35 "SolarArray15" 36 "SolarArray16" 252 "All" 253 "Reserved" 254 "Out of Range" 255 "Data Not Available Do Not Change" ;
VAL_ 2147564800 CfgType 0 "User" 1 "OEM" 2 "Factory" 3 "Reserved" ;
VAL_ 2147571456 StartStop 0 "Off" 1 "On" 2 "Reserved" 3 "No Change" ;
VAL_ 2147571456 CfgType 0 "User" 1 "OEM" 2 "Factory" 3 "Reserved" ;
VAL_ 2147571456 AcSrcId 0 "Invalid" 1 "None" 2 "Anonymous" 3 "Shore1" 4 "Shore2" 5 "Shore3" 6 "Shore4" 7 "Shore5" 8 "Shore6" 9 "Shore7" 10 "Shore8" 11 "Shore9" 12 "Shore10" 13 "Shore11" 14 "Shore12" 15 "Shore13" 16 "Shore14" 17 "Shore15" 18 "Shore16" 19 "Gen1" 20 "Gen2" 21 "Gen3" 22 "Gen4" 23 "Gen5" 24 "Gen6" 25 "Gen7" 26 "Gen8" 27 "Gen9" 28 "Gen10" 29 "Gen11" 30 "Gen12" 31 "Gen13" 32 "Gen14" 33 "Gen15" 34 "Gen16" 35 "AC1" 36 "AC2" 37 "AC3" 38 "AC4" 39 "AC5" 40 "AC6" 41 "AC7" 42 "AC8" 43 "AC9" 44 "AC10" 45 "AC11" 46 "AC12" 47 "AC13" 48 "AC14" 49 "AC15" 50 "AC16" 51 "AC Load1" 52 "AC Load2" 53 "AC Load3" 54 "AC Load4" 55 "AC Load5" 56 "AC Load6" 57 "AC Load7" 58 "AC Load8" 59 "AC Load9" 60 "AC Load10" 61 "AC Load11" 62 "AC Load12" 63 "AC Load13" 64 "AC Load14" 65 "AC Load15" 66 "AC Load16" 67 "Grid1" 68 "Grid2" 69 "Grid3" 70 "Grid4" 71 "Grid5" 72 "Grid6" 73 "Grid7" 74 "Grid8" 75 "Grid9" 76 "Grid10" 77 "Grid11" 78 "Grid12" 79 "Grid13" 80 "Grid14" 81 "Grid15" 82 "Grid16" 252 "All" 253 "Reserved" 254 "Out Of Range" 255 "Data Not Available Do Not Change" ;
VAL_ 2147565056 StartStop 0 "Off" 1 "On" 2 "Reserved" 3 "No Change" ;
VAL_ 2147565056 CfgType 0 "User" 1 "OEM" 2 "Factory" 3 "Reserved" ;
VAL_ 2147565056 AcSrcId 0 "Invalid" 1 "None" 2 "Anonymous" 3 "Shore1" 4 "Shore2" 5 "Shore3" 6 "Shore4" 7 "Shore5" 8 "Shore6" 9 "Shore7" 10 "Shore8" 11 "Shore9" 12 "Shore10" 13 "Shore11" 14 "Shore12" 15 "Shore13" 16 "Shore14" 17 "Shore15" 18 "Shore16" 19 "Gen1" 20 "Gen2" 21 "Gen3" 22 "Gen4" 23 "Gen5" 24 "Gen6" 25 "Gen7" 26 "Gen8" 27 "Gen9" 28 "Gen10" 29 "Gen11" 30 "Gen12" 31 "Gen13" 32 "Gen14" 33 "Gen15" 34 "Gen16" 35 "AC1" 36 "AC2" 37 "AC3" 38 "AC4" 39 "AC5" 40 "AC6" 41 "AC7" 42 "AC8" 43 "AC9" 44 "AC10" 45 "AC11" 46 "AC12" 47 "AC13" 48 "AC14" 49 "AC15" 50 "AC16" 51 "AC Load1" 52 "AC Load2" 53 "AC Load3" 54 "AC Load4" 55 "AC Load5" 56 "AC Load6" 57 "AC Load7" 58 "AC Load8" 59 "AC Load9" 60 "AC Load10" 61 "AC Load11" 62 "AC Load12" 63 "AC Load13" 64 "AC Load14" 65 "AC Load15" 66 "AC Load16" 67 "Grid1" 68 "Grid2" 69 "Grid3" 70 "Grid4" 71 "Grid5" 72 "Grid6" 73 "Grid7" 74 "Grid8" 75 "Grid9" 76 "Grid10" 77 "Grid11" 78 "Grid12" 79 "Grid13" 80 "Grid14" 81 "Grid15" 82 "Grid16" 252 "All" 253 "Reserved" 254 "Out Of Range" 255 "Data Not Available Do Not Change" ;
VAL_ 2147559936 QtEnDis 0 "Off" 1 "On" 2 "Reserved" 3 "No Change" ;
VAL_ 2147559936 FloatAutoStopEnDis 0 "Off" 1 "On" 2 "Reserved" 3 "No Change" ;
VAL_ 2147559936 DcVAutoStopEnDis 0 "Off" 1 "On" 2 "Reserved" 3 "No Change" ;
VAL_ 2147559936 DcVAutoStartEnDis 0 "Off" 1 "On" 2 "Reserved" 3 "No Change" ;
VAL_ 2147559936 DcIAutoStopEnDis 0 "Off" 1 "On" 2 "Reserved" 3 "No Change" ;
VAL_ 2147559936 DcIAutoStartEnDis 0 "Off" 1 "On" 2 "Reserved" 3 "No Change" ;
VAL_ 2147559936 CntctClsAutoEnDis 0 "Off" 1 "On" 2 "Reserved" 3 "No Change" ;
VAL_ 2147559936 CfgType 0 "User" 1 "OEM" 2 "Factory" 3 "Reserved" ;
VAL_ 2147559936 BattSocAutoStopEnDis 0 "Off" 1 "On" 2 "Reserved" 3 "No Change" ;
VAL_ 2147559936 BattSocAutoStartEnDis 0 "Off" 1 "On" 2 "Reserved" 3 "No Change" ;
VAL_ 2147559936 AcSrcId 0 "Invalid" 1 "None" 2 "Anonymous" 3 "Shore1" 4 "Shore2" 5 "Shore3" 6 "Shore4" 7 "Shore5" 8 "Shore6" 9 "Shore7" 10 "Shore8" 11 "Shore9" 12 "Shore10" 13 "Shore11" 14 "Shore12" 15 "Shore13" 16 "Shore14" 17 "Shore15" 18 "Shore16" 19 "Gen1" 20 "Gen2" 21 "Gen3" 22 "Gen4" 23 "Gen5" 24 "Gen6" 25 "Gen7" 26 "Gen8" 27 "Gen9" 28 "Gen10" 29 "Gen11" 30 "Gen12" 31 "Gen13" 32 "Gen14" 33 "Gen15" 34 "Gen16" 35 "AC1" 36 "AC2" 37 "AC3" 38 "AC4" 39 "AC5" 40 "AC6" 41 "AC7" 42 "AC8" 43 "AC9" 44 "AC10" 45 "AC11" 46 "AC12" 47 "AC13" 48 "AC14" 49 "AC15" 50 "AC16" 51 "AC Load1" 52 "AC Load2" 53 "AC Load3" 54 "AC Load4" 55 "AC Load5" 56 "AC Load6" 57 "AC Load7" 58 "AC Load8" 59 "AC Load9" 60 "AC Load10" 61 "AC Load11" 62 "AC Load12" 63 "AC Load13" 64 "AC Load14" 65 "AC Load15" 66 "AC Load16" 67 "Grid1" 68 "Grid2" 69 "Grid3" 70 "Grid4" 71 "Grid5" 72 "Grid6" 73 "Grid7" 74 "Grid8" 75 "Grid9" 76 "Grid10" 77 "Grid11" 78 "Grid12" 79 "Grid13" 80 "Grid14" 81 "Grid15" 82 "Grid16" 252 "All" 253 "Reserved" 254 "Out Of Range" 255 "Data Not Available Do Not Change" ;
VAL_ 2147559936 AcPwrAutoStopEnDis 0 "Off" 1 "On" 2 "Reserved" 3 "No Change" ;
VAL_ 2147559936 AcPwrAutoStartEnDis 0 "Off" 1 "On" 2 "Reserved" 3 "No Change" ;
VAL_ 2147559936 AcIAutoStopEnDis 0 "Off" 1 "On" 2 "Reserved" 3 "No Change" ;
VAL_ 2147559936 AcIAutoStartEnDis 0 "Off" 1 "On" 2 "Reserved" 3 "No Change" ;
VAL_ 2147559936 AbsorpAutoStopEnDis 0 "Off" 1 "On" 2 "Reserved" 3 "No Change" ;
VAL_ 2147610815 XferSwMode 0 "Unknown" 1 "Grid Priority" 2 "Generator Priority" 3 "Inverter Priority" ;
VAL_ 2147610815 OpState 800 "Inactive" 801 "Input1Active" 802 "Input2Active" 803 "Input1Delay" 804 "Input2Delay" ;
VAL_ 2147599360 XferSwMode 0 "Unknown" 1 "Grid Priority" 2 "Generator Priority" 253 "Reserved" 254 "Out Of Range" 255 "Data Not Available Do Not Change" ;
VAL_ 2147599360 CfgType 0 "User" 1 "OEM" 2 "Factory" 3 "Reserved" ;
VAL_ 2147599360 AcSrcId 0 "Invalid" 1 "None" 2 "Anonymous" 3 "Shore1" 4 "Shore2" 5 "Shore3" 6 "Shore4" 7 "Shore5" 8 "Shore6" 9 "Shore7" 10 "Shore8" 11 "Shore9" 12 "Shore10" 13 "Shore11" 14 "Shore12" 15 "Shore13" 16 "Shore14" 17 "Shore15" 18 "Shore16" 19 "Gen1" 20 "Gen2" 21 "Gen3" 22 "Gen4" 23 "Gen5" 24 "Gen6" 25 "Gen7" 26 "Gen8" 27 "Gen9" 28 "Gen10" 29 "Gen11" 30 "Gen12" 31 "Gen13" 32 "Gen14" 33 "Gen15" 34 "Gen16" 35 "AC1" 36 "AC2" 37 "AC3" 38 "AC4" 39 "AC5" 40 "AC6" 41 "AC7" 42 "AC8" 43 "AC9" 44 "AC10" 45 "AC11" 46 "AC12" 47 "AC13" 48 "AC14" 49 "AC15" 50 "AC16" 51 "AC Load1" 52 "AC Load2" 53 "AC Load3" 54 "AC Load4" 55 "AC Load5" 56 "AC Load6" 57 "AC Load7" 58 "AC Load8" 59 "AC Load9" 60 "AC Load10" 61 "AC Load11" 62 "AC Load12" 63 "AC Load13" 64 "AC Load14" 65 "AC Load15" 66 "AC Load16" 67 "Grid1" 68 "Grid2" 69 "Grid3" 70 "Grid4" 71 "Grid5" 72 "Grid6" 73 "Grid7" 74 "Grid8" 75 "Grid9" 76 "Grid10" 77 "Grid11" 78 "Grid12" 79 "Grid13" 80 "Grid14" 81 "Grid15" 82 "Grid16" 252 "All" 253 "Reserved" 254 "Out Of Range" 255 "Data Not Available Do Not Change" ;
VAL_ 2147612869 WarnType 0 "Auto Reset Warning" 1 "Manual Warning" 5 "Reserved" 6 "Out Of Range" 7 "No Change Data NA" ;
VAL_ 2147612869 WarnId 34 "DC Over Voltage Warning 2" 35 "Heatsink Over Temperature Warning 1" 0 "Transistor Over Temperature Warning 1" 1 "Transistor Over Temperature Warning 2" 2 "Capacitor Over Temperature Warning 1" 3 "Transformer Over Temperature Warning 1" 4 "Battery Over Temperature Warning 1" 5 "Ambient Over Temperature Warning 1" 6 "AC Output Overload Warning" 7 "Auto Restart After Fault Enabled Warning" 9 "Battery Sensor Not Present Warning" 10 "Battery Sensor Short Warning" 11 "DC Over Voltage Warning 1" 12 "DC Under Voltage Warning 1" 13 "AC Line 1 Input Over Voltage Warning" 14 "AC Line 1 Input Under Voltage Warning" 15 "AC Line 2 Input Over Voltage Warning" 16 "AC Line 2 Input Under Voltage Warning" 18 "Cannot Equalize" 19 "Equalization Terminated Abnormally" 20 "AC Output Over Voltage Warning 1" 21 "AC Output Under Voltage Warning 1" 22 "AC Output Over Voltage Warning 2" 23 "AC Output Under Voltage Warning 2" 24 "Generator Line 1 Input Over Voltage Warning" 25 "Generator Line 1 Input Under Voltage Warning" 26 "Generator Line 2 Input Over Voltage Warning" 27 "Generator Line 2 Input Under Voltage Warning" 28 "Generator Line 1 Input Over Frequency Warning" 29 "Generator Line 1 Input Under Frequency Warning" 30 "Generator Line 2 Input Over Frequency Warning" 31 "Generator Line 2 Input Under Frequency Warning" 32 "AC Input L1 L2 120 Over Frequency Warning" 33 "AC Input L1 L2 120 Under Frequency Warning" 200 "External Genset Shutdown Warning" 201 "External Genset Startup Warning" 202 "Unable To Start Genset Warning" 203 "Reached Max Run Time Warning" 204 "Max Genset Cycle With No Intervention Warning" 205 "Gen On Not Ags" 206 "Orphaned Auto Start Trigger" 207 "Orphaned Auto Stop Trigger" 208 "No Auto Triggers Defined" 209 "Gen Off Not Ags" 250 "Failed To Set Value Warning" 251 "Confirm Equalization Warning" 252 "Confirm Restore Defaults Warning" 253 "Aborted Equalization" 254 "Failed To Set Value Due To System Mode" 255 "Clock Not Set" 256 "Device Lost" 257 "New Device" 258 "Node Instance Duplicated" 500 "Lost Network Connection" 501 "Defaults Restored On Powerup Warning" 502 "Missing Expected Status" 599 "Associations Invalid" 8189 "Reserved" 8190 "Out Of Range" 8191 "No Change Data NA" ;
VAL_ 2147612685 WarnType 0 "Auto Reset Warning" 1 "Manual Warning" 5 "Reserved" 6 "Out Of Range" 7 "No Change Data NA" ;
VAL_ 2147612685 WarnId 34 "DC Over Voltage Warning 2" 35 "Heatsink Over Temperature Warning 1" 0 "Transistor Over Temperature Warning 1" 1 "Transistor Over Temperature Warning 2" 2 "Capacitor Over Temperature Warning 1" 3 "Transformer Over Temperature Warning 1" 4 "Battery Over Temperature Warning 1" 5 "Ambient Over Temperature Warning 1" 6 "AC Output Overload Warning" 7 "Auto Restart After Fault Enabled Warning" 9 "Battery Sensor Not Present Warning" 10 "Battery Sensor Short Warning" 11 "DC Over Voltage Warning 1" 12 "DC Under Voltage Warning 1" 13 "AC Line 1 Input Over Voltage Warning" 14 "AC Line 1 Input Under Voltage Warning" 15 "AC Line 2 Input Over Voltage Warning" 16 "AC Line 2 Input Under Voltage Warning" 18 "Cannot Equalize" 19 "Equalization Terminated Abnormally" 20 "AC Output Over Voltage Warning 1" 21 "AC Output Under Voltage Warning 1" 22 "AC Output Over Voltage Warning 2" 23 "AC Output Under Voltage Warning 2" 24 "Generator Line 1 Input Over Voltage Warning" 25 "Generator Line 1 Input Under Voltage Warning" 26 "Generator Line 2 Input Over Voltage Warning" 27 "Generator Line 2 Input Under Voltage Warning" 28 "Generator Line 1 Input Over Frequency Warning" 29 "Generator Line 1 Input Under Frequency Warning" 30 "Generator Line 2 Input Over Frequency Warning" 31 "Generator Line 2 Input Under Frequency Warning" 32 "AC Input L1 L2 120 Over Frequency Warning" 33 "AC Input L1 L2 120 Under Frequency Warning" 200 "External Genset Shutdown Warning" 201 "External Genset Startup Warning" 202 "Unable To Start Genset Warning" 203 "Reached Max Run Time Warning" 204 "Max Genset Cycle With No Intervention Warning" 205 "Gen On Not Ags" 206 "Orphaned Auto Start Trigger" 207 "Orphaned Auto Stop Trigger" 208 "No Auto Triggers Defined" 209 "Gen Off Not Ags" 250 "Failed To Set Value Warning" 251 "Confirm Equalization Warning" 252 "Confirm Restore Defaults Warning" 253 "Aborted Equalization" 254 "Failed To Set Value Due To System Mode" 255 "Clock Not Set" 256 "Device Lost" 257 "New Device" 258 "Node Instance Duplicated" 500 "Lost Network Connection" 501 "Defaults Restored On Powerup Warning" 502 "Missing Expected Status" 599 "Associations Invalid" 8189 "Reserved" 8190 "Out Of Range" 8191 "No Change Data NA" ;
VAL_ 2147612870 FaultType 0 "Auto Reset Escalating Fault" 1 "Auto Reset Non Escalating Fault" 2 "Manual Fault" 5 "Reserved" 6 "Out Of Range" 7 "No Change Data NA" ;
VAL_ 2147612870 FaultId 73 "DC Over Current Shutdown 2" 74 "DC Over Voltage Shutdown 3" 0 "Transistor Over Temperature Shutdown 1" 1 "Transistor Over Temperature Shutdown 2" 2 "Capacitor Over Temperature Shutdown 1" 3 "Transformer Over Temperature Shutdown 1" 4 "Battery Over Temperature Shutdown 1" 5 "Ambient Over Temperature Shutdown 1" 6 "AC Output Overload Shutdown 1" 7 "AC Output Overload Peak Current Shutdown 1" 8 "Neutral Loss Shutdown" 9 "DC Over Voltage Shutdown 1" 10 "DC Under Voltage Immediate Shutdown 1" 11 "DC Under Voltage Shutdown 1" 12 "AC Input Line 1 Over Voltage Shutdown" 13 "AC Input Line 1 Under Voltage Shutdown" 14 "AC Input Line 2 Over Voltage Shutdown" 15 "AC Input Line 2 Under Voltage Shutdown" 16 "AC Input Line 1 Over Frequency Shutdown" 17 "AC Input Line 1 Under Frequency Shutdown" 18 "AC Input Line 2 Over Frequency Shutdown" 19 "AC Input Line 2 Under Frequency Shutdown" 22 "ADC Conversion Timeout" 23 "AC Output Over Voltage Shutdown 1" 24 "AC Output Under Voltage Shutdown 1" 25 "APS Over Voltage" 26 "APS Under Voltage" 27 "OPS Over Voltage" 28 "OPS Under Voltage" 29 "AC Backfeed Shutdown" 30 "Battery Under Temperature" 31 "Echo Charger Short Circuit" 32 "Echo Charger Reverse Polarity" 33 "Echo Charger Input Over Voltage" 34 "Echo Charger Input Under Voltage" 35 "Echo Charger Over Temperature" 36 "Echo Charger Under Temperature" 37 "Echo Charger Not Communicating" 40 "Lost Interprocessor Communications" 41 "Dead Battery Charge Timeout" 42 "AC Output Over Voltage Shutdown 2" 43 "AC Output Under Voltage Shutdown 2" 44 "Generator Line 1 Input Over Voltage Shutdown" 45 "Generator Line 1 Input Under Voltage Shutdown" 46 "Generator Line 2 Input Over Voltage Shutdown" 47 "Generator Line 2 Input Under Voltage Shutdown" 48 "Generator Line 1 Input Over Frequency Shutdown" 49 "Generator Line 1 Input Under Frequency Shutdown" 50 "Generator Line 2 Input Over Frequency Shutdown" 51 "Generator Line 2 Input Under Frequency Shutdown" 52 "AC Input L1 L2 120 Over Frequency Shutdown" 53 "AC Input L1 L2 120 Under Frequency Shutdown" 54 "APS 1 Off" 55 "Heatsink 1 Over Temperature Shutdown" 56 "Ground Fault" 57 "External Shutdown" 58 "AC Output 1 Voltage Shutdown" 59 "AC Output 1 Frequency Shutdown" 60 "AC Output 1 Impedance Shutdown" 61 "Reconnecting 1" 62 "DC-DC 1 Saturated" 63 "User Shutdown" 64 "Neutral Over Current 1" 65 "Over Voltage Antiislanding" 66 "Under Voltage Antiislanding" 67 "Over Frequency Antiislanding" 68 "Under Frequency Antiislanding" 69 "Battery Conflicting Setup" 70 "DC Over Voltage Shutdown 2" 71 "DC Over Current Shutdown" 72 "SPS Overload" 200 "Max Start Retries" 201 "Unable to Stop Generator" 203 "Gen Stop by Ext Shutdown" 250 "Clock Not Set" 251 "Device Lost" 252 "New Device" 500 "Silicon Serial ID Failure" 501 "Non-Volatile Error" 502 "Watchdog Reset" 503 "Real-time Clock Failure" 504 "Lost Network Connection" 505 "Controller Failure" 506 "Wrong Fault Identifier" 507 "Wrong Warning Identifier" 508 "Invalid Interrupt" 599 "Associations Invalid" 8189 "Reserved" 8190 "Out Of Range" 8191 "No Change Data NA" 75 "Fan Problem 1" 76 "Fan Problem 2" 77 "DC Over Current Shutdown 3" 78 "DC Over Current Shutdown 4" 79 "Fan Problem 3" 80 "Fan Problem 4" 81 "Fan Problem 5" 82 "Network Power Supply Failure" 83 "Battery Discharge Over Current" ;
VAL_ 2147612683 FaultType 0 "Auto Reset Escalating Fault" 1 "Auto Reset Non Escalating Fault" 2 "Manual Fault" 5 "Reserved" 6 "Out Of Range" 7 "No Change Data NA" ;
VAL_ 2147612683 FaultId 73 "DC Over Current Shutdown 2" 74 "DC Over Voltage Shutdown 3" 0 "Transistor Over Temperature Shutdown 1" 1 "Transistor Over Temperature Shutdown 2" 2 "Capacitor Over Temperature Shutdown 1" 3 "Transformer Over Temperature Shutdown 1" 4 "Battery Over Temperature Shutdown 1" 5 "Ambient Over Temperature Shutdown 1" 6 "AC Output Overload Shutdown 1" 7 "AC Output Overload Peak Current Shutdown 1" 8 "Neutral Loss Shutdown" 9 "DC Over Voltage Shutdown 1" 10 "DC Under Voltage Immediate Shutdown 1" 11 "DC Under Voltage Shutdown 1" 12 "AC Input Line 1 Over Voltage Shutdown" 13 "AC Input Line 1 Under Voltage Shutdown" 14 "AC Input Line 2 Over Voltage Shutdown" 15 "AC Input Line 2 Under Voltage Shutdown" 16 "AC Input Line 1 Over Frequency Shutdown" 17 "AC Input Line 1 Under Frequency Shutdown" 18 "AC Input Line 2 Over Frequency Shutdown" 19 "AC Input Line 2 Under Frequency Shutdown" 22 "ADC Conversion Timeout" 23 "AC Output Over Voltage Shutdown 1" 24 "AC Output Under Voltage Shutdown 1" 25 "APS Over Voltage" 26 "APS Under Voltage" 27 "OPS Over Voltage" 28 "OPS Under Voltage" 29 "AC Backfeed Shutdown" 30 "Battery Under Temperature" 31 "Echo Charger Short Circuit" 32 "Echo Charger Reverse Polarity" 33 "Echo Charger Input Over Voltage" 34 "Echo Charger Input Under Voltage" 35 "Echo Charger Over Temperature" 36 "Echo Charger Under Temperature" 37 "Echo Charger Not Communicating" 40 "Lost Interprocessor Communications" 41 "Dead Battery Charge Timeout" 42 "AC Output Over Voltage Shutdown 2" 43 "AC Output Under Voltage Shutdown 2" 44 "Generator Line 1 Input Over Voltage Shutdown" 45 "Generator Line 1 Input Under Voltage Shutdown" 46 "Generator Line 2 Input Over Voltage Shutdown" 47 "Generator Line 2 Input Under Voltage Shutdown" 48 "Generator Line 1 Input Over Frequency Shutdown" 49 "Generator Line 1 Input Under Frequency Shutdown" 50 "Generator Line 2 Input Over Frequency Shutdown" 51 "Generator Line 2 Input Under Frequency Shutdown" 52 "AC Input L1 L2 120 Over Frequency Shutdown" 53 "AC Input L1 L2 120 Under Frequency Shutdown" 54 "APS 1 Off" 55 "Heatsink 1 Over Temperature Shutdown" 56 "Ground Fault" 57 "External Shutdown" 58 "AC Output 1 Voltage Shutdown" 59 "AC Output 1 Frequency Shutdown" 60 "AC Output 1 Impedance Shutdown" 61 "Reconnecting 1" 62 "DC-DC 1 Saturated" 63 "User Shutdown" 64 "Neutral Over Current 1" 65 "Over Voltage Antiislanding" 66 "Under Voltage Antiislanding" 67 "Over Frequency Antiislanding" 68 "Under Frequency Antiislanding" 69 "Battery Conflicting Setup" 70 "DC Over Voltage Shutdown 2" 71 "DC Over Current Shutdown" 72 "SPS Overload" 200 "Max Start Retries" 201 "Unable to Stop Generator" 203 "Gen Stop by Ext Shutdown" 250 "Clock Not Set" 251 "Device Lost" 252 "New Device" 500 "Silicon Serial ID Failure" 501 "Non-Volatile Error" 502 "Watchdog Reset" 503 "Real-time Clock Failure" 504 "Lost Network Connection" 505 "Controller Failure" 506 "Wrong Fault Identifier" 507 "Wrong Warning Identifier" 508 "Invalid Interrupt" 599 "Associations Invalid" 8189 "Reserved" 8190 "Out Of Range" 8191 "No Change Data NA" 75 "Fan Problem 1" 76 "Fan Problem 2" 77 "DC Over Current Shutdown 3" 78 "DC Over Current Shutdown 4" 79 "Fan Problem 3" 80 "Fan Problem 4" 81 "Fan Problem 5" 82 "Network Power Supply Failure" 83 "Battery Discharge Over Current" ;
VAL_ 2147610646 TotalFlag 0 "Off" 1 "On" 2 "Error" 3 "Unknown" ;
VAL_ 2147610646 Quality 0 "Invalid" 1 "Being Qualified" 2 "Bad Frequency" 3 "Bad Level" 4 "Good" 21 "Frequency Low" 22 "Frequency High" 31 "Voltage Low" 32 "Voltage High" 253 "Reserved" 254 "Out Of Range" 255 "Data Not Available Do Not Change" ;
VAL_ 2147610646 Line 0 "Invalid" 1 "Line 1" 2 "Line 2" 3 "Line 3" 253 "Reserved" 254 "Out Of Range" 255 "Data Not Available Do Not Change" ;
VAL_ 2147610646 AcSrcId 0 "Invalid" 1 "None" 2 "Anonymous" 3 "Shore1" 4 "Shore2" 5 "Shore3" 6 "Shore4" 7 "Shore5" 8 "Shore6" 9 "Shore7" 10 "Shore8" 11 "Shore9" 12 "Shore10" 13 "Shore11" 14 "Shore12" 15 "Shore13" 16 "Shore14" 17 "Shore15" 18 "Shore16" 19 "Gen1" 20 "Gen2" 21 "Gen3" 22 "Gen4" 23 "Gen5" 24 "Gen6" 25 "Gen7" 26 "Gen8" 27 "Gen9" 28 "Gen10" 29 "Gen11" 30 "Gen12" 31 "Gen13" 32 "Gen14" 33 "Gen15" 34 "Gen16" 35 "AC1" 36 "AC2" 37 "AC3" 38 "AC4" 39 "AC5" 40 "AC6" 41 "AC7" 42 "AC8" 43 "AC9" 44 "AC10" 45 "AC11" 46 "AC12" 47 "AC13" 48 "AC14" 49 "AC15" 50 "AC16" 51 "AC Load1" 52 "AC Load2" 53 "AC Load3" 54 "AC Load4" 55 "AC Load5" 56 "AC Load6" 57 "AC Load7" 58 "AC Load8" 59 "AC Load9" 60 "AC Load10" 61 "AC Load11" 62 "AC Load12" 63 "AC Load13" 64 "AC Load14" 65 "AC Load15" 66 "AC Load16" 67 "Grid1" 68 "Grid2" 69 "Grid3" 70 "Grid4" 71 "Grid5" 72 "Grid6" 73 "Grid7" 74 "Grid8" 75 "Grid9" 76 "Grid10" 77 "Grid11" 78 "Grid12" 79 "Grid13" 80 "Grid14" 81 "Grid15" 82 "Grid16" 252 "All" 253 "Reserved" 254 "Out Of Range" 255 "Data Not Available Do Not Change" ;
VAL_ 2147610630 Waveform 0 "Invalid" 1 "Sine Wave" 2 "Modified Sine Wave" 253 "Reserved" 254 "Out Of Range" 255 "Data Not Available Do Not Change" ;
VAL_ 2147610630 TotalFlag 0 "Off" 1 "On" 2 "Error" 3 "Unknown" ;
VAL_ 2147610630 Line 0 "Invalid" 1 "Line 1" 2 "Line 2" 3 "Line 3" 253 "Reserved" 254 "Out Of Range" 255 "Data Not Available Do Not Change" ;
VAL_ 2147610630 AcSrcId 0 "Invalid" 1 "None" 2 "Anonymous" 3 "Shore1" 4 "Shore2" 5 "Shore3" 6 "Shore4" 7 "Shore5" 8 "Shore6" 9 "Shore7" 10 "Shore8" 11 "Shore9" 12 "Shore10" 13 "Shore11" 14 "Shore12" 15 "Shore13" 16 "Shore14" 17 "Shore15" 18 "Shore16" 19 "Gen1" 20 "Gen2" 21 "Gen3" 22 "Gen4" 23 "Gen5" 24 "Gen6" 25 "Gen7" 26 "Gen8" 27 "Gen9" 28 "Gen10" 29 "Gen11" 30 "Gen12" 31 "Gen13" 32 "Gen14" 33 "Gen15" 34 "Gen16" 35 "AC1" 36 "AC2" 37 "AC3" 38 "AC4" 39 "AC5" 40 "AC6" 41 "AC7" 42 "AC8" 43 "AC9" 44 "AC10" 45 "AC11" 46 "AC12" 47 "AC13" 48 "AC14" 49 "AC15" 50 "AC16" 51 "AC Load1" 52 "AC Load2" 53 "AC Load3" 54 "AC Load4" 55 "AC Load5" 56 "AC Load6" 57 "AC Load7" 58 "AC Load8" 59 "AC Load9" 60 "AC Load10" 61 "AC Load11" 62 "AC Load12" 63 "AC Load13" 64 "AC Load14" 65 "AC Load15" 66 "AC Load16" 67 "Grid1" 68 "Grid2" 69 "Grid3" 70 "Grid4" 71 "Grid5" 72 "Grid6" 73 "Grid7" 74 "Grid8" 75 "Grid9" 76 "Grid10" 77 "Grid11" 78 "Grid12" 79 "Grid13" 80 "Grid14" 81 "Grid15" 82 "Grid16" 252 "All" 253 "Reserved" 254 "Out Of Range" 255 "Data Not Available Do Not Change" ;
VAL_ 2147610631 Waveform 0 "Invalid" 1 "Sine Wave" 2 "Modified Sine Wave" 253 "Reserved" 254 "Out Of Range" 255 "Data Not Available Do Not Change" ;
VAL_ 2147610631 TotalFlag 0 "Off" 1 "On" 2 "Error" 3 "Unknown" ;
VAL_ 2147610631 Line 0 "Invalid" 1 "Line 1" 2 "Line 2" 3 "Line 3" 253 "Reserved" 254 "Out Of Range" 255 "Data Not Available Do Not Change" ;
VAL_ 2147610631 AcSrcId 0 "Invalid" 1 "None" 2 "Anonymous" 3 "Shore1" 4 "Shore2" 5 "Shore3" 6 "Shore4" 7 "Shore5" 8 "Shore6" 9 "Shore7" 10 "Shore8" 11 "Shore9" 12 "Shore10" 13 "Shore11" 14 "Shore12" 15 "Shore13" 16 "Shore14" 17 "Shore15" 18 "Shore16" 19 "Gen1" 20 "Gen2" 21 "Gen3" 22 "Gen4" 23 "Gen5" 24 "Gen6" 25 "Gen7" 26 "Gen8" 27 "Gen9" 28 "Gen10" 29 "Gen11" 30 "Gen12" 31 "Gen13" 32 "Gen14" 33 "Gen15" 34 "Gen16" 35 "AC1" 36 "AC2" 37 "AC3" 38 "AC4" 39 "AC5" 40 "AC6" 41 "AC7" 42 "AC8" 43 "AC9" 44 "AC10" 45 "AC11" 46 "AC12" 47 "AC13" 48 "AC14" 49 "AC15" 50 "AC16" 51 "AC Load1" 52 "AC Load2" 53 "AC Load3" 54 "AC Load4" 55 "AC Load5" 56 "AC Load6" 57 "AC Load7" 58 "AC Load8" 59 "AC Load9" 60 "AC Load10" 61 "AC Load11" 62 "AC Load12" 63 "AC Load13" 64 "AC Load14" 65 "AC Load15" 66 "AC Load16" 67 "Grid1" 68 "Grid2" 69 "Grid3" 70 "Grid4" 71 "Grid5" 72 "Grid6" 73 "Grid7" 74 "Grid8" 75 "Grid9" 76 "Grid10" 77 "Grid11" 78 "Grid12" 79 "Grid13" 80 "Grid14" 81 "Grid15" 82 "Grid16" 252 "All" 253 "Reserved" 254 "Out Of Range" 255 "Data Not Available Do Not Change" ;
VAL_ 2147610632 Waveform 0 "Invalid" 1 "Sine Wave" 2 "Modified Sine Wave" 253 "Reserved" 254 "Out Of Range" 255 "Data Not Available Do Not Change" ;
VAL_ 2147610632 TotalFlag 0 "Off" 1 "On" 2 "Error" 3 "Unknown" ;
VAL_ 2147610632 Line 0 "Invalid" 1 "Line 1" 2 "Line 2" 3 "Line 3" 253 "Reserved" 254 "Out Of Range" 255 "Data Not Available Do Not Change" ;
VAL_ 2147610632 AcSrcId 0 "Invalid" 1 "None" 2 "Anonymous" 3 "Shore1" 4 "Shore2" 5 "Shore3" 6 "Shore4" 7 "Shore5" 8 "Shore6" 9 "Shore7" 10 "Shore8" 11 "Shore9" 12 "Shore10" 13 "Shore11" 14 "Shore12" 15 "Shore13" 16 "Shore14" 17 "Shore15" 18 "Shore16" 19 "Gen1" 20 "Gen2" 21 "Gen3" 22 "Gen4" 23 "Gen5" 24 "Gen6" 25 "Gen7" 26 "Gen8" 27 "Gen9" 28 "Gen10" 29 "Gen11" 30 "Gen12" 31 "Gen13" 32 "Gen14" 33 "Gen15" 34 "Gen16" 35 "AC1" 36 "AC2" 37 "AC3" 38 "AC4" 39 "AC5" 40 "AC6" 41 "AC7" 42 "AC8" 43 "AC9" 44 "AC10" 45 "AC11" 46 "AC12" 47 "AC13" 48 "AC14" 49 "AC15" 50 "AC16" 51 "AC Load1" 52 "AC Load2" 53 "AC Load3" 54 "AC Load4" 55 "AC Load5" 56 "AC Load6" 57 "AC Load7" 58 "AC Load8" 59 "AC Load9" 60 "AC Load10" 61 "AC Load11" 62 "AC Load12" 63 "AC Load13" 64 "AC Load14" 65 "AC Load15" 66 "AC Load16" 67 "Grid1" 68 "Grid2" 69 "Grid3" 70 "Grid4" 71 "Grid5" 72 "Grid6" 73 "Grid7" 74 "Grid8" 75 "Grid9" 76 "Grid10" 77 "Grid11" 78 "Grid12" 79 "Grid13" 80 "Grid14" 81 "Grid15" 82 "Grid16" 252 "All" 253 "Reserved" 254 "Out Of Range" 255 "Data Not Available Do Not Change" ;
VAL_ 2147570176 RefEvtId 436 "SPS Auto Off Array V Low" 437 "SPS Auto On Array V Low" 438 "SPS Auto Off Ground Flt" 439 "SPS Auto On Ground Flt" 440 "SPS Auto Off External Shutdown Flt" 0 "None" 10 "Control Command Hibernate" 11 "Control Command Safe" 12 "Control Command Power Save" 13 "Control Command Operating" 14 "Control Command Diagnostic" 15 "Control Command Last Mode" 20 "Reset Command Reboot" 21 "Reset Command Download" 22 "Reset Command Oem" 23 "Reset Command Factory" 24 "Reset Command Reboot Clear Nv" 25 "Powered Up" 30 "Clear Command Active Faults" 31 "Clear Command Fault Log" 32 "Clear Command Active Warns" 33 "Clear Command Warn Log" 34 "Clear Command State Event Log" 35 "Clear Command Comm Stats" 36 "Clear Command Stats" 37 "Clear Command All" 40 "Date Time Configured" 50 "Warn Cleared" 51 "Fault Cleared" 52 "Fault Set" 60 "User Cfg Changed" 61 "Oem Cfg Changed" 70 "Triggered Fault" 250 "Shutdown Threshold" 251 "Shutdown Hysteresis" 252 "Warning Threshold" 253 "Warning Hysteresis" 254 "Transfer Threshold" 255 "Fan 0 Threshold" 256 "Fan 10 Threshold" 257 "Fan 20 Threshold" 258 "Fan 30 Threshold" 259 "Fan 40 Threshold" 260 "Fan 50 Threshold" 261 "Fan 60 Threshold" 262 "Fan 70 Threshold" 263 "Fan 80 Threshold" 264 "Fan 90 Threshold" 265 "Fan 100 Threshold" 266 "Relay Open Threshold" 267 "Relay Close Threshold" 268 "Charger Derating Ac In V" 269 "Charger Derating Ac In I" 270 "Charger Derating Ext Temp" 271 "Charger Derating Int Temp" 272 "Charger Derating Ripple V" 273 "Lost Ac Threshold" 274 "Lost Ac Hysteresis" 275 "Imm Shutdown Threshold" 276 "Imm Shutdown Hysteresis" 277 "Charger Shutdown Threshold" 278 "Charger Shutdown Hysteresis" 279 "Charger Warning Threshold" 280 "Charger Warning Hysteresis" 281 "Inverter Shutdown Threshold" 282 "Inverter Shutdown Hysteresis" 283 "Inverter Warning Threshold" 284 "Inverter Warning Hysteresis" 285 "Charger Derating Temp Start Point" 286 "Charger Derating Temp End Point" 287 "Charger Recharge Threshold" 300 "Ags Exercise Start" 301 "Ags Exercise Stop" 302 "Ags Quiet Time Begin" 303 "Ags Quiet Time End" 304 "Ags Battery Soc Start" 305 "Ags Battery Soc Stop" 306 "Ags Dc V Start" 307 "Ags Dc V Stop" 308 "Ags Ac I Start" 309 "Ags Ac I Stop" 310 "Ags Contact Start" 311 "Ags Contact Stop" 312 "Ags Float Stop" 313 "Ags Absorp Stop" 314 "Ags Manual On" 315 "Ags Manual Off" 316 "Ags Auto" 317 "Ags External On" 318 "Ags External Off" 319 "Gen External On" 320 "Gen External Off" 321 "Ags External Shutdown" 322 "Ags Auto Off" 323 "Ags Dc I Start" 324 "Ags Dc I Stop" 325 "Ags Ac Power Start" 326 "Ags Ac Power Stop" 400 "Sps Manual Off" 401 "Sps Manual On" 410 "Sps Auto Off" 411 "Sps Auto On" 420 "Sps Auto Off Batt V Low" 421 "Sps Auto On Batt V Low" 422 "Sps Auto Off Batt V High" 423 "Sps Auto On Batt V High" 424 "Sps Auto Off Array V High" 425 "Sps Auto On Array V High" 426 "Sps Auto Off Batt Temp Low" 427 "Sps Auto On Batt Temp Low" 428 "Sps Auto Off Batt Temp High" 429 "Sps Auto On Batt Temp High" 430 "Sps Auto Off Heat Sink Temp High" 431 "Sps Auto On Heat Sink Temp High" 432 "Sps Auto Off Fault" 433 "Sps Auto On Fault" 434 "Aps Check Timeout" 435 "Aps Qualify Timeout" 512 "Resume From Safe" 513 "AC Fault Set" 514 "Invert Fault Set" 515 "Charge Fault Set" 516 "Charger Enable" 517 "Charger Disable" 518 "Inverter Enable" 519 "Inverter Disable" 520 "Charge Suspend On" 521 "Charge Suspend Off" 522 "AC Good" 523 "AC Bad" 524 "Load Sense Enable" 525 "Load Sense Active" 526 "Invert Active" 527 "Bulk Exit" 528 "Absorption Exit" 529 "Float Exit" 530 "Float 3-Stage Set" 531 "Float 2-Stage Set" 532 "Equalize Enable" 533 "Equalize Disable" 534 "Equalize Exit" 535 "Load Sense Disable" 536 "Sell To Grid Enabled" 537 "Sell To Grid Disabled" 538 "Grid Support Enable" 539 "Grid Support Disable" 540 "Gen Support Enable" 541 "Gen Support Disable" 542 "Peak Load Shaving Enable" 543 "Peak Load Shaving Disable" 544 "Peak Load Shaving Tod Start" 545 "Peak Load Shaving Tod Stop" 546 "Unit Off" 547 "System Absorption Exit" 548 "System Inverter Enable" 549 "System AC Good" 550 "Anti Islanding Condition" 551 "Hibernate Timeout" 552 "External Sync Error" 553 "External Suspend Request" 554 "Engaging Charger" 555 "Engaging Gen Support" 556 "Grid Tie Engage Timeout" 557 "Gen Support Engage Timeout" 558 "Charge Engage Timeout" 559 "Inverter Engage Timeout" 560 "Charge Exit Timeout" 561 "Grid Support Entry Amps" 562 "Grid Support Exit Amps" 563 "Gen Support Entry Amps" 564 "Gen Support Exit Amps" 565 "Grid Support Entry Vdc" 566 "Grid Support Exit Vdc" 567 "Low Batt Cut Off Entry Vdc" 568 "Low Batt Recharge Vdc" 569 "Low Batt Cut Off Exit Vdc" 570 "Invert To Bypass Timeout" 571 "Force Charge" 572 "System Engage Bulk Charge" 441 "SPS Auto On External Shutdown Flt" 442 "SPS Auto Off Input Over Volt Flt" 443 "SPS Auto On Input Over Volt Flt" 444 "SPS Auto Off Input Over Volt Err" 445 "SPS Auto On Input Over Volt Err" 446 "SPS Auto Off Input Over Volt Wrn" 447 "SPS Auto On Input Over Volt Wrn" 448 "SPS Auto Off Output Over Volt Err" 449 "SPS Auto On Output Over Volt Err" 450 "SPS Auto Off Output Over Volt Wrn" 451 "SPS Auto On Output Over Volt Wrn" 452 "SPS Auto Off Output Under Volt Err" 453 "SPS Auto On Output Under Volt Err" 454 "SPS Auto Off Output Under Volt Wrn" 455 "SPS Auto On Output Under Volt Wrn" 456 "SPS Auto Off Output Over Curr Err" 457 "SPS Auto On Output Over Curr Err" 458 "SPS Auto Off Batt Over Temp Err" 459 "SPS Auto On Batt Over Temp Err" 460 "SPS Auto Off Batt Over Temp Wrn" 461 "SPS Auto On Batt Over Temp Wrn" 462 "SPS Auto Off Batt Under Temp Wrn" 463 "SPS Auto On Batt Under Temp Wrn" 464 "SPS Auto Off Heatsink Over Temp Err" 465 "SPS Auto On Heatsink Over Temp Err" 466 "SPS Auto Off Heatsink Over Temp Wrn" 467 "SPS Auto On Heatsink Over Temp Wrn" 468 "SPS Auto Off Ambient Over Temp Err" 469 "SPS Auto On Ambient Over Temp Err" 470 "SPS Auto Off Ambient Over Temp Wrn" 471 "SPS Auto On Ambient Over Temp Wrn" 472 "SPS Auto Off Capacitor Over Temp Err" 473 "SPS Auto On Capacitor Over Temp Err" 474 "SPS Auto Off Fan Flt" 475 "SPS Auto On Fan Flt" 476 "SPS Auto Off Fan Err" 477 "SPS Auto On Fan Err" 478 "SPS Auto Off Input Over Curr Err" 479 "SPS Auto On Input Over Curr Err" 480 "SPS Auto Off Output Over Curr Flt" 481 "SPS Auto On Output Over Curr Flt" 482 "SPS Auto Off Network PS Flt" 483 "SPS Auto On Network PS Flt" 484 "SPS Auto Off Setup Flt" 485 "SPS Auto On Setup Flt" 38 "Clear Command User Stats" 573 "AC Good Pending" 574 "Grid Safe" 585 "PLS Time In Float Ready" 575 "Power Conversion Fault" 576 "Low Battery Support Exit" 577 "Grid Support Exit" 578 "GFS Enable" 579 "GFS Disable" 580 "Force Sell" 486 "SPS Auto On Bulk Exit" 487 "SPS Auto Off Bulk Exit" 488 "SPS Auto On Absorption Exit" 489 "SPS Auto Off Absorption Exit" 490 "SPS Auto On State Of Charge Low" 491 "SPS Auto Off State Of Charge Low" 492 "SPS Auto On Time Of Day" 493 "SPS Auto Off Time Of Day" 581 "Sell Time Of Day Start" 582 "Sell Time Of Day Stop" 583 "Aux Port Time Of Day Start" 584 "Aux Port Time Of Day Stop" ;
VAL_ 2147570176 EvtId 436 "SPS Auto Off Array V Low" 437 "SPS Auto On Array V Low" 438 "SPS Auto Off Ground Flt" 439 "SPS Auto On Ground Flt" 440 "SPS Auto Off External Shutdown Flt" 0 "None" 10 "Control Command Hibernate" 11 "Control Command Safe" 12 "Control Command Power Save" 13 "Control Command Operating" 14 "Control Command Diagnostic" 15 "Control Command Last Mode" 20 "Reset Command Reboot" 21 "Reset Command Download" 22 "Reset Command Oem" 23 "Reset Command Factory" 24 "Reset Command Reboot Clear Nv" 25 "Powered Up" 30 "Clear Command Active Faults" 31 "Clear Command Fault Log" 32 "Clear Command Active Warns" 33 "Clear Command Warn Log" 34 "Clear Command State Event Log" 35 "Clear Command Comm Stats" 36 "Clear Command Stats" 37 "Clear Command All" 40 "Date Time Configured" 50 "Warn Cleared" 51 "Fault Cleared" 52 "Fault Set" 60 "User Cfg Changed" 61 "Oem Cfg Changed" 70 "Triggered Fault" 250 "Shutdown Threshold" 251 "Shutdown Hysteresis" 252 "Warning Threshold" 253 "Warning Hysteresis" 254 "Transfer Threshold" 255 "Fan 0 Threshold" 256 "Fan 10 Threshold" 257 "Fan 20 Threshold" 258 "Fan 30 Threshold" 259 "Fan 40 Threshold" 260 "Fan 50 Threshold" 261 "Fan 60 Threshold" 262 "Fan 70 Threshold" 263 "Fan 80 Threshold" 264 "Fan 90 Threshold" 265 "Fan 100 Threshold" 266 "Relay Open Threshold" 267 "Relay Close Threshold" 268 "Charger Derating Ac In V" 269 "Charger Derating Ac In I" 270 "Charger Derating Ext Temp" 271 "Charger Derating Int Temp" 272 "Charger Derating Ripple V" 273 "Lost Ac Threshold" 274 "Lost Ac Hysteresis" 275 "Imm Shutdown Threshold" 276 "Imm Shutdown Hysteresis" 277 "Charger Shutdown Threshold" 278 "Charger Shutdown Hysteresis" 279 "Charger Warning Threshold" 280 "Charger Warning Hysteresis" 281 "Inverter Shutdown Threshold" 282 "Inverter Shutdown Hysteresis" 283 "Inverter Warning Threshold" 284 "Inverter Warning Hysteresis" 285 "Charger Derating Temp Start Point" 286 "Charger Derating Temp End Point" 287 "Charger Recharge Threshold" 300 "Ags Exercise Start" 301 "Ags Exercise Stop" 302 "Ags Quiet Time Begin" 303 "Ags Quiet Time End" 304 "Ags Battery Soc Start" 305 "Ags Battery Soc Stop" 306 "Ags Dc V Start" 307 "Ags Dc V Stop" 308 "Ags Ac I Start" 309 "Ags Ac I Stop" 310 "Ags Contact Start" 311 "Ags Contact Stop" 312 "Ags Float Stop" 313 "Ags Absorp Stop" 314 "Ags Manual On" 315 "Ags Manual Off" 316 "Ags Auto" 317 "Ags External On" 318 "Ags External Off" 319 "Gen External On" 320 "Gen External Off" 321 "Ags External Shutdown" 322 "Ags Auto Off" 323 "Ags Dc I Start" 324 "Ags Dc I Stop" 325 "Ags Ac Power Start" 326 "Ags Ac Power Stop" 400 "Sps Manual Off" 401 "Sps Manual On" 410 "Sps Auto Off" 411 "Sps Auto On" 420 "Sps Auto Off Batt V Low" 421 "Sps Auto On Batt V Low" 422 "Sps Auto Off Batt V High" 423 "Sps Auto On Batt V High" 424 "Sps Auto Off Array V High" 425 "Sps Auto On Array V High" 426 "Sps Auto Off Batt Temp Low" 427 "Sps Auto On Batt Temp Low" 428 "Sps Auto Off Batt Temp High" 429 "Sps Auto On Batt Temp High" 430 "Sps Auto Off Heat Sink Temp High" 431 "Sps Auto On Heat Sink Temp High" 432 "Sps Auto Off Fault" 433 "Sps Auto On Fault" 434 "Aps Check Timeout" 435 "Aps Qualify Timeout" 512 "Resume From Safe" 513 "AC Fault Set" 514 "Invert Fault Set" 515 "Charge Fault Set" 516 "Charger Enable" 517 "Charger Disable" 518 "Inverter Enable" 519 "Inverter Disable" 520 "Charge Suspend On" 521 "Charge Suspend Off" 522 "AC Good" 523 "AC Bad" 524 "Load Sense Enable" 525 "Load Sense Active" 526 "Invert Active" 527 "Bulk Exit" 528 "Absorption Exit" 529 "Float Exit" 530 "Float 3-Stage Set" 531 "Float 2-Stage Set" 532 "Equalize Enable" 533 "Equalize Disable" 534 "Equalize Exit" 535 "Load Sense Disable" 536 "Sell To Grid Enabled" 537 "Sell To Grid Disabled" 538 "Grid Support Enable" 539 "Grid Support Disable" 540 "Gen Support Enable" 541 "Gen Support Disable" 542 "Peak Load Shaving Enable" 543 "Peak Load Shaving Disable" 544 "Peak Load Shaving Tod Start" 545 "Peak Load Shaving Tod Stop" 546 "Unit Off" 547 "System Absorption Exit" 548 "System Inverter Enable" 549 "System AC Good" 550 "Anti Islanding Condition" 551 "Hibernate Timeout" 552 "External Sync Error" 553 "External Suspend Request" 554 "Engaging Charger" 555 "Engaging Gen Support" 556 "Grid Tie Engage Timeout" 557 "Gen Support Engage Timeout" 558 "Charge Engage Timeout" 559 "Inverter Engage Timeout" 560 "Charge Exit Timeout" 561 "Grid Support Entry Amps" 562 "Grid Support Exit Amps" 563 "Gen Support Entry Amps" 564 "Gen Support Exit Amps" 565 "Grid Support Entry Vdc" 566 "Grid Support Exit Vdc" 567 "Low Batt Cut Off Entry Vdc" 568 "Low Batt Recharge Vdc" 569 "Low Batt Cut Off Exit Vdc" 570 "Invert To Bypass Timeout" 571 "Force Charge" 572 "System Engage Bulk Charge" 441 "SPS Auto On External Shutdown Flt" 442 "SPS Auto Off Input Over Volt Flt" 443 "SPS Auto On Input Over Volt Flt" 444 "SPS Auto Off Input Over Volt Err" 445 "SPS Auto On Input Over Volt Err" 446 "SPS Auto Off Input Over Volt Wrn" 447 "SPS Auto On Input Over Volt Wrn" 448 "SPS Auto Off Output Over Volt Err" 449 "SPS Auto On Output Over Volt Err" 450 "SPS Auto Off Output Over Volt Wrn" 451 "SPS Auto On Output Over Volt Wrn" 452 "SPS Auto Off Output Under Volt Err" 453 "SPS Auto On Output Under Volt Err" 454 "SPS Auto Off Output Under Volt Wrn" 455 "SPS Auto On Output Under Volt Wrn" 456 "SPS Auto Off Output Over Curr Err" 457 "SPS Auto On Output Over Curr Err" 458 "SPS Auto Off Batt Over Temp Err" 459 "SPS Auto On Batt Over Temp Err" 460 "SPS Auto Off Batt Over Temp Wrn" 461 "SPS Auto On Batt Over Temp Wrn" 462 "SPS Auto Off Batt Under Temp Wrn" 463 "SPS Auto On Batt Under Temp Wrn" 464 "SPS Auto Off Heatsink Over Temp Err" 465 "SPS Auto On Heatsink Over Temp Err" 466 "SPS Auto Off Heatsink Over Temp Wrn" 467 "SPS Auto On Heatsink Over Temp Wrn" 468 "SPS Auto Off Ambient Over Temp Err" 469 "SPS Auto On Ambient Over Temp Err" 470 "SPS Auto Off Ambient Over Temp Wrn" 471 "SPS Auto On Ambient Over Temp Wrn" 472 "SPS Auto Off Capacitor Over Temp Err" 473 "SPS Auto On Capacitor Over Temp Err" 474 "SPS Auto Off Fan Flt" 475 "SPS Auto On Fan Flt" 476 "SPS Auto Off Fan Err" 477 "SPS Auto On Fan Err" 478 "SPS Auto Off Input Over Curr Err" 479 "SPS Auto On Input Over Curr Err" 480 "SPS Auto Off Output Over Curr Flt" 481 "SPS Auto On Output Over Curr Flt" 482 "SPS Auto Off Network PS Flt" 483 "SPS Auto On Network PS Flt" 484 "SPS Auto Off Setup Flt" 485 "SPS Auto On Setup Flt" 38 "Clear Command User Stats" 573 "AC Good Pending" 574 "Grid Safe" 585 "PLS Time In Float Ready" 575 "Power Conversion Fault" 576 "Low Battery Support Exit" 577 "Grid Support Exit" 578 "GFS Enable" 579 "GFS Disable" 580 "Force Sell" 486 "SPS Auto On Bulk Exit" 487 "SPS Auto Off Bulk Exit" 488 "SPS Auto On Absorption Exit" 489 "SPS Auto Off Absorption Exit" 490 "SPS Auto On State Of Charge Low" 491 "SPS Auto Off State Of Charge Low" 492 "SPS Auto On Time Of Day" 493 "SPS Auto Off Time Of Day" 581 "Sell Time Of Day Start" 582 "Sell Time Of Day Stop" 583 "Aux Port Time Of Day Start" 584 "Aux Port Time Of Day Stop" ;
VAL_ 2147570176 CfgType 0 "User" 1 "OEM" 2 "Factory" 3 "Reserved" ;
VAL_ 2147570176 AcSrcId 0 "Invalid" 1 "None" 2 "Anonymous" 3 "Shore1" 4 "Shore2" 5 "Shore3" 6 "Shore4" 7 "Shore5" 8 "Shore6" 9 "Shore7" 10 "Shore8" 11 "Shore9" 12 "Shore10" 13 "Shore11" 14 "Shore12" 15 "Shore13" 16 "Shore14" 17 "Shore15" 18 "Shore16" 19 "Gen1" 20 "Gen2" 21 "Gen3" 22 "Gen4" 23 "Gen5" 24 "Gen6" 25 "Gen7" 26 "Gen8" 27 "Gen9" 28 "Gen10" 29 "Gen11" 30 "Gen12" 31 "Gen13" 32 "Gen14" 33 "Gen15" 34 "Gen16" 35 "AC1" 36 "AC2" 37 "AC3" 38 "AC4" 39 "AC5" 40 "AC6" 41 "AC7" 42 "AC8" 43 "AC9" 44 "AC10" 45 "AC11" 46 "AC12" 47 "AC13" 48 "AC14" 49 "AC15" 50 "AC16" 51 "AC Load1" 52 "AC Load2" 53 "AC Load3" 54 "AC Load4" 55 "AC Load5" 56 "AC Load6" 57 "AC Load7" 58 "AC Load8" 59 "AC Load9" 60 "AC Load10" 61 "AC Load11" 62 "AC Load12" 63 "AC Load13" 64 "AC Load14" 65 "AC Load15" 66 "AC Load16" 67 "Grid1" 68 "Grid2" 69 "Grid3" 70 "Grid4" 71 "Grid5" 72 "Grid6" 73 "Grid7" 74 "Grid8" 75 "Grid9" 76 "Grid10" 77 "Grid11" 78 "Grid12" 79 "Grid13" 80 "Grid14" 81 "Grid15" 82 "Grid16" 252 "All" 253 "Reserved" 254 "Out Of Range" 255 "Data Not Available Do Not Change" ;
